VERSION ""

NS_ :

BS_:

BU_: PowertrainControlModule AtmosphericSensor SafetyRestraintSystem2 Aftertreatment_2_GasOutlet Aftertreatment_2_GasIntake DieselParticulateFilterControl Turbocharger SafetyRestraintSystem1 CabDisplay2 Aftertreatment_1_GasOutlet Aftertreatment_1_GasIntake OnBoardDataLogger OffBoardDiagnosticTool2 OffBoardDiagnosticTool1 FileServer ParkingBrakeController SeatController2 FanDriveController SteeringColumnUnit CommunicationUnitRadio CommunicationUnitSatellite CommunicationUnitCellular PropulsionBatteryCharger ChassisController2 ChassisController1 EngineValveControl AuxiliaryHeater2 AuxiliaryHeater1 ClutchUnit RampControl InformationSystem1 SuspensionSystemController2 OilSensor VehicleDynamicStability ExhaustEmissionController TransmissionDisplay2 TransmissionDisplay1 ClimateControl2 WaterPumpController RearAxleSteeringController LightingOperatorControl SeatController1 IgnitionController2 IgnitionController1 TirePressureController CabController2 CabController1 PneumaticSystemController SuspensionSystemController1 HydraulicPumpController EnduranceBrakingSystem RetarderExhaustEngine2 OnBoardDiagnosticUnit HeadwayController RetarderExhaustEngine1 CabDisplay1 ManagementComputer VirtualTerminal OffVehicleGateway PowerTakeOffFront HitchControl AuxiliaryValveControl BodyController TractorTrailerBridge1 StarterSystem ElectricalSystem VehicleSecurity VehicleNavigation AerodynamicControl ElectricalChargingSystem ClimateControl1 TripRecorder InstrumentCluster SuspensionDriveAxle2 SuspensionDriveAxle1 SuspensionSteerAxle SteeringController FuelSystem CruiseControl RetarderDriveline RetarderEngine BrakesDriveAxle2 BrakesDriveAxle1 BrakesSystemController BrakesSteerAxle AxleDrive2 AxleDrive1 AxleSteering PowerTakeOff ShiftConsoleSecondary ShiftConsolePrimary Transmission2 Transmission1 Engine2 Engine1

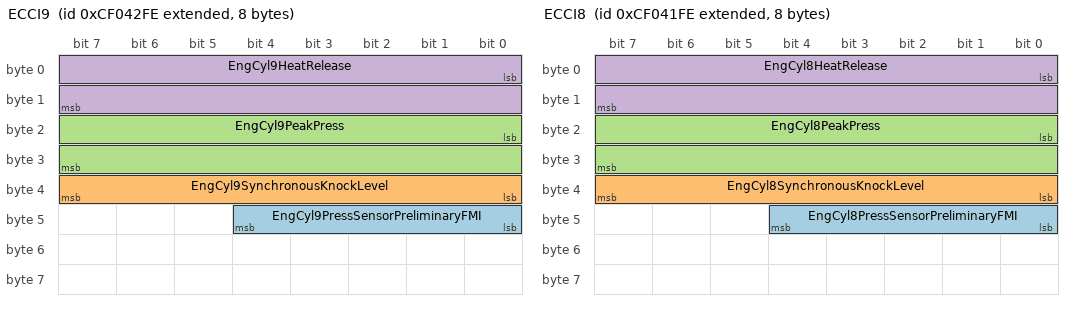
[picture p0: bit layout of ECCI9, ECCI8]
BO_ 2364556030 ECCI9: 8 Vector__XXX
 SG_ EngCyl9PressSensorPreliminaryFMI : 40|5@1+ (1,0) [0|31] "" Vector__XXX
 SG_ EngCyl9SynchronousKnockLevel : 32|8@1+ (1,0) [0|250] "%" Vector__XXX
 SG_ EngCyl9PeakPress : 16|16@1+ (0.0009765625,0) [0|62.74902344] "MPa" Vector__XXX
 SG_ EngCyl9HeatRelease : 0|16@1+ (0.0001220703125,-1) [-1|6.84362793] "kJ/l" Vector__XXX

BO_ 2364555774 ECCI8: 8 Vector__XXX
 SG_ EngCyl8PressSensorPreliminaryFMI : 40|5@1+ (1,0) [0|31] "" Vector__XXX
 SG_ EngCyl8SynchronousKnockLevel : 32|8@1+ (1,0) [0|250] "%" Vector__XXX
 SG_ EngCyl8PeakPress : 16|16@1+ (0.0009765625,0) [0|62.74902344] "MPa" Vector__XXX
 SG_ EngCyl8HeatRelease : 0|16@1+ (0.0001220703125,-1) [-1|6.84362793] "kJ/l" Vector__XXX

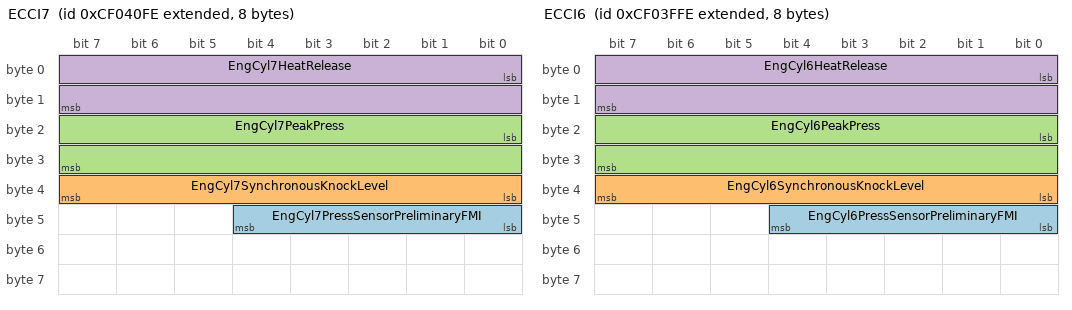
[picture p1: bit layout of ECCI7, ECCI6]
BO_ 2364555518 ECCI7: 8 Vector__XXX
 SG_ EngCyl7PressSensorPreliminaryFMI : 40|5@1+ (1,0) [0|31] "" Vector__XXX
 SG_ EngCyl7SynchronousKnockLevel : 32|8@1+ (1,0) [0|250] "%" Vector__XXX
 SG_ EngCyl7PeakPress : 16|16@1+ (0.0009765625,0) [0|62.74902344] "MPa" Vector__XXX
 SG_ EngCyl7HeatRelease : 0|16@1+ (0.0001220703125,-1) [-1|6.84362793] "kJ/l" Vector__XXX

BO_ 2364555262 ECCI6: 8 Vector__XXX
 SG_ EngCyl6PressSensorPreliminaryFMI : 40|5@1+ (1,0) [0|31] "" Vector__XXX
 SG_ EngCyl6SynchronousKnockLevel : 32|8@1+ (1,0) [0|250] "%" Vector__XXX
 SG_ EngCyl6PeakPress : 16|16@1+ (0.0009765625,0) [0|62.74902344] "MPa" Vector__XXX
 SG_ EngCyl6HeatRelease : 0|16@1+ (0.0001220703125,-1) [-1|6.84362793] "kJ/l" Vector__XXX

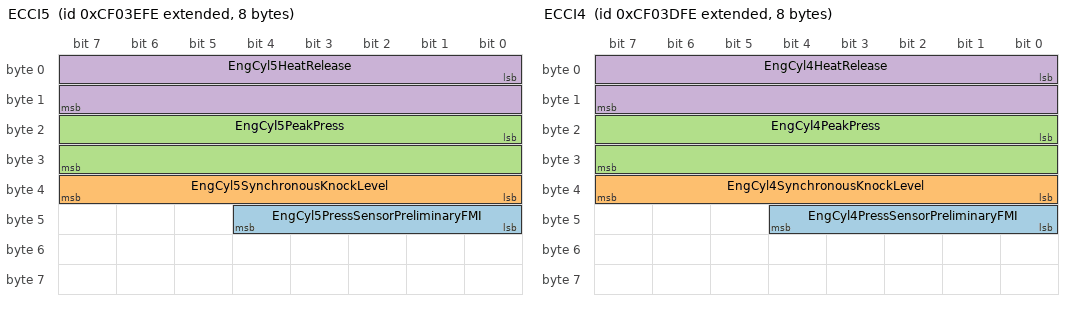
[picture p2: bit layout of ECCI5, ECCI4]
BO_ 2364555006 ECCI5: 8 Vector__XXX
 SG_ EngCyl5PressSensorPreliminaryFMI : 40|5@1+ (1,0) [0|31] "" Vector__XXX
 SG_ EngCyl5SynchronousKnockLevel : 32|8@1+ (1,0) [0|250] "%" Vector__XXX
 SG_ EngCyl5PeakPress : 16|16@1+ (0.0009765625,0) [0|62.74902344] "MPa" Vector__XXX
 SG_ EngCyl5HeatRelease : 0|16@1+ (0.0001220703125,-1) [-1|6.84362793] "kJ/l" Vector__XXX

BO_ 2364554750 ECCI4: 8 Vector__XXX
 SG_ EngCyl4PressSensorPreliminaryFMI : 40|5@1+ (1,0) [0|31] "" Vector__XXX
 SG_ EngCyl4SynchronousKnockLevel : 32|8@1+ (1,0) [0|250] "%" Vector__XXX
 SG_ EngCyl4PeakPress : 16|16@1+ (0.0009765625,0) [0|62.74902344] "MPa" Vector__XXX
 SG_ EngCyl4HeatRelease : 0|16@1+ (0.0001220703125,-1) [-1|6.84362793] "kJ/l" Vector__XXX

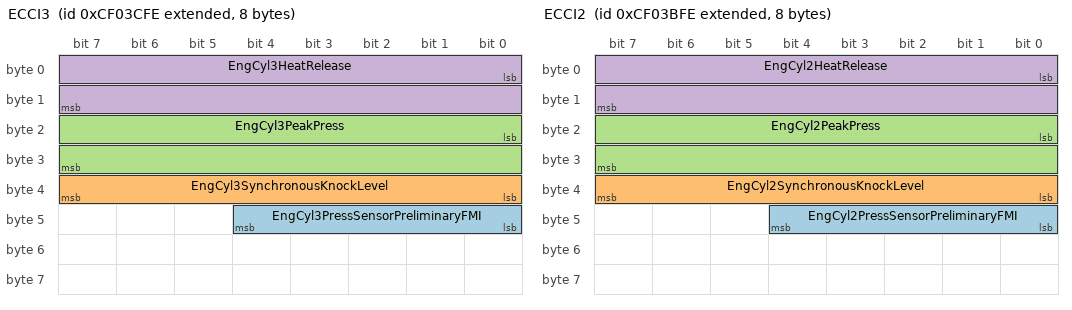
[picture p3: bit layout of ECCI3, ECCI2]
BO_ 2364554494 ECCI3: 8 Vector__XXX
 SG_ EngCyl3PressSensorPreliminaryFMI : 40|5@1+ (1,0) [0|31] "" Vector__XXX
 SG_ EngCyl3SynchronousKnockLevel : 32|8@1+ (1,0) [0|250] "%" Vector__XXX
 SG_ EngCyl3PeakPress : 16|16@1+ (0.0009765625,0) [0|62.74902344] "MPa" Vector__XXX
 SG_ EngCyl3HeatRelease : 0|16@1+ (0.0001220703125,-1) [-1|6.84362793] "kJ/l" Vector__XXX

BO_ 2364554238 ECCI2: 8 Vector__XXX
 SG_ EngCyl2PressSensorPreliminaryFMI : 40|5@1+ (1,0) [0|31] "" Vector__XXX
 SG_ EngCyl2SynchronousKnockLevel : 32|8@1+ (1,0) [0|250] "%" Vector__XXX
 SG_ EngCyl2PeakPress : 16|16@1+ (0.0009765625,0) [0|62.74902344] "MPa" Vector__XXX
 SG_ EngCyl2HeatRelease : 0|16@1+ (0.0001220703125,-1) [-1|6.84362793] "kJ/l" Vector__XXX

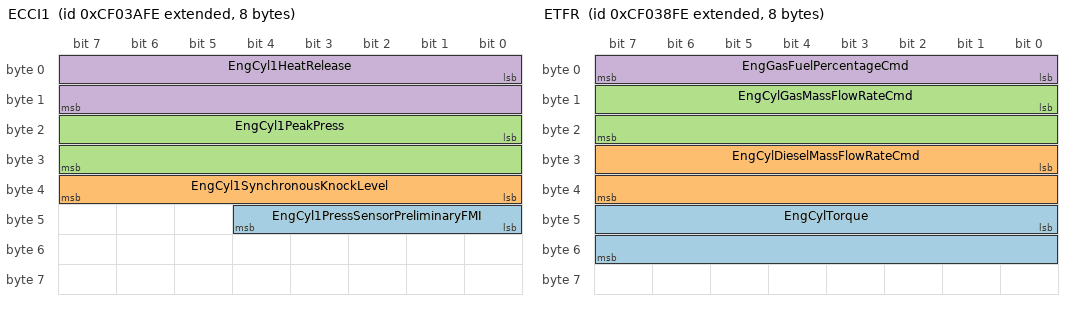
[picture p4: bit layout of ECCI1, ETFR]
BO_ 2364553982 ECCI1: 8 Vector__XXX
 SG_ EngCyl1PressSensorPreliminaryFMI : 40|5@1+ (1,0) [0|31] "" Vector__XXX
 SG_ EngCyl1SynchronousKnockLevel : 32|8@1+ (1,0) [0|100] "%" Vector__XXX
 SG_ EngCyl1PeakPress : 16|16@1+ (0.0009765625,0) [0|62.74902344] "MPa" Vector__XXX
 SG_ EngCyl1HeatRelease : 0|16@1+ (0.0001220703125,-1) [-1|6.84362793] "kJ/l" Vector__XXX

BO_ 2364553726 EASI: 8 Vector__XXX
 SG_ EngTotalIntakeMassAirFlowRate : 16|16@1+ (0.0009765625,0) [0|62.74902344] "kg/s" Vector__XXX
 SG_ EngDesiredAirFuelRatio : 0|16@1+ (0.001,0) [0|64.255] "" Vector__XXX

BO_ 2364553470 ETFR: 8 Vector__XXX
 SG_ EngCylTorque : 40|16@1+ (1,0) [0|64255] "Nm" Vector__XXX
 SG_ EngCylDieselMassFlowRateCmd : 24|16@1+ (6.103515625E-005,0) [0|3.921813965] "kg/s" Vector__XXX
 SG_ EngCylGasMassFlowRateCmd : 8|16@1+ (6.103515625E-005,0) [0|3.921813965] "kg/s" Vector__XXX
 SG_ EngGasFuelPercentageCmd : 0|8@1+ (0.5,0) [0|100] "%" Vector__XXX

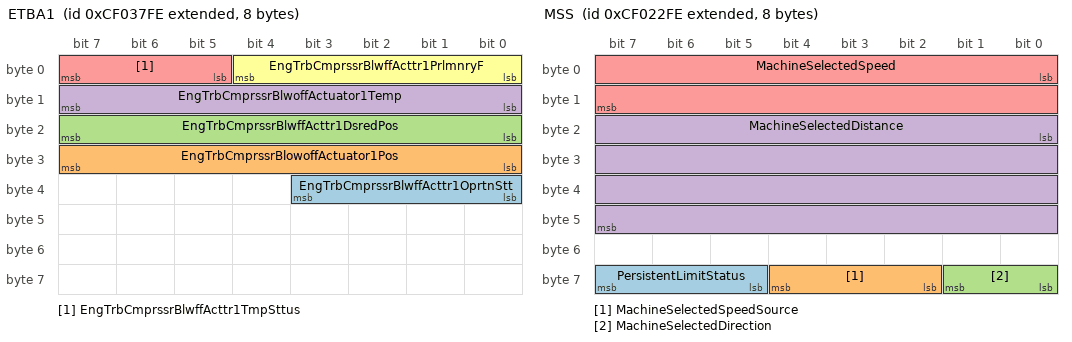
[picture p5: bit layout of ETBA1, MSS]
BO_ 2364553214 ETBA1: 8 Vector__XXX
 SG_ EngTrbCmprssrBlwffActtr1OprtnStt : 32|4@1+ (1,0) [0|15] "" Vector__XXX
 SG_ EngTrbCmprssrBlowoffActuator1Pos : 24|8@1+ (0.4,0) [0|100] "%" Vector__XXX
 SG_ EngTrbCmprssrBlwffActtr1DsredPos : 16|8@1+ (0.4,0) [0|100] "%" Vector__XXX
 SG_ EngTrbCmprssrBlwoffActuator1Temp : 8|8@1+ (1,-40) [-40|210] "°C" Vector__XXX
 SG_ EngTrbCmprssrBlwffActtr1TmpSttus : 5|3@1+ (1,0) [0|7] "" Vector__XXX
 SG_ EngTrbCmprssrBlwffActtr1PrlmnryF : 0|5@1+ (1,0) [0|31] "" Vector__XXX

BO_ 2364547838 MSS: 8 Vector__XXX
 SG_ PersistentLimitStatus : 61|3@1+ (1,0) [0|0] "" Vector__XXX
 SG_ MachineSelectedSpeedSource : 58|3@1+ (1,0) [0|0] "" Vector__XXX
 SG_ MachineSelectedDirection : 56|2@1+ (1,0) [0|0] "" Vector__XXX
 SG_ MachineSelectedDistance : 16|32@1+ (1,0) [0|0] "" Vector__XXX
 SG_ MachineSelectedSpeed : 0|16@1+ (1,0) [0|0] "" Vector__XXX

BO_ 2364547326 EBS25: 8 Vector__XXX

BO_ 2364547070 EBS26: 8 Vector__XXX

BO_ 2364546814 GC2: 8 Vector__XXX
 SG_ GeneratorGoverningBias : 0|16@1+ (0.004,-125) [-125|125] "%" Vector__XXX

BO_ 2364546046 GPM17: 8 Vector__XXX

BO_ 2364538369 PropA: 256 Vector__XXX
 SG_ ManufacturerSpecificInformation : 128|64@1+ (1,0) [0|0] "" Vector__XXX
 SG_ ManufacSpecInfo004_u32 : 96|32@1+ (1,0) [0|0] "" Vector__XXX
 SG_ ManufacSpecInfo002_u32 : 64|32@1+ (1,0) [0|0] "" Vector__XXX
 SG_ ManufacSpecInfo002_u32 : 32|32@1+ (1,0) [0|0] "" Vector__XXX
 SG_ ManufacSpecInfo001_u32 : 0|32@1+ (1,0) [0|0] "" Vector__XXX
 SG_ ManufacturerSpecificInformation1 : 192|64@1+ (1,0) [0|0] "" Vector__XXX

BO_ 2364014334 VT21: 8 Vector__XXX

BO_ 2363948798 VT12: 8 Vector__XXX

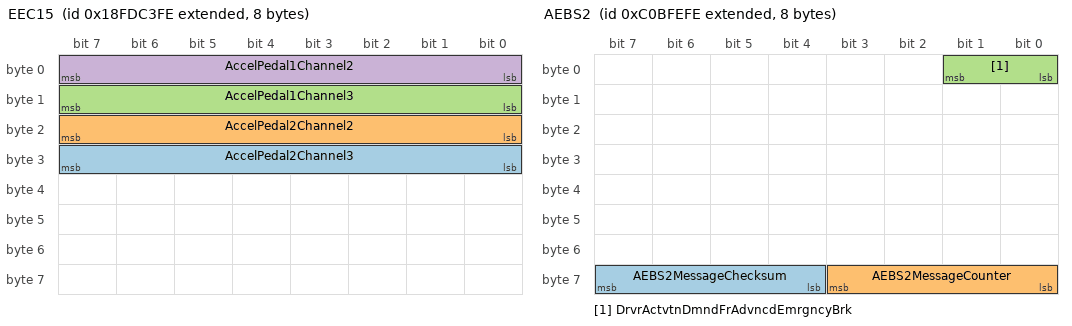
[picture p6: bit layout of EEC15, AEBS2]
BO_ 2566767614 EEC15: 8 Vector__XXX
 SG_ AccelPedal2Channel3 : 24|8@1+ (0.4,0) [0|100] "%" Vector__XXX
 SG_ AccelPedal2Channel2 : 16|8@1+ (0.4,0) [0|100] "%" Vector__XXX
 SG_ AccelPedal1Channel3 : 8|8@1+ (0.4,0) [0|100] "%" Vector__XXX
 SG_ AccelPedal1Channel2 : 0|8@1+ (0.4,0) [0|100] "%" Vector__XXX

BO_ 2559049470 ESR: 8 Vector__XXX
 SG_ DesiredEngFuelingState : 0|2@1+ (1,0) [0|3] "" Vector__XXX
 SG_ RequestedFuelType : 8|8@1+ (1,0) [0|255] "" Vector__XXX

BO_ 2349596414 AEBS2: 8 Vector__XXX
 SG_ AEBS2MessageChecksum : 60|4@1+ (1,0) [0|15] "" Vector__XXX
 SG_ AEBS2MessageCounter : 56|4@1+ (1,0) [0|15] "" Vector__XXX
 SG_ DrvrActvtnDmndFrAdvncdEmrgncyBrk : 0|2@1+ (1,0) [0|3] "" Vector__XXX

BO_ 2362375934 KWP3: 8 Vector__XXX

BO_ 2362310398 KWP4: 8 Vector__XXX

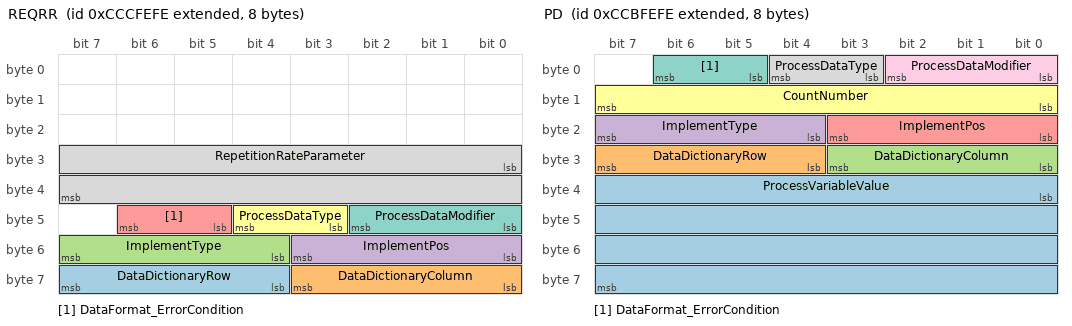
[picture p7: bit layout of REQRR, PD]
BO_ 2362244862 REQRR: 8 Vector__XXX
 SG_ DataDictionaryRow : 60|4@1+ (1,0) [0|0] "" Vector__XXX
 SG_ DataDictionaryColumn : 56|4@1+ (1,0) [0|0] "" Vector__XXX
 SG_ ImplementType : 52|4@1+ (1,0) [0|0] "" Vector__XXX
 SG_ ImplementPos : 48|4@1+ (1,0) [0|0] "" Vector__XXX
 SG_ DataFormat_ErrorCondition : 45|2@1+ (1,0) [0|0] "" Vector__XXX
 SG_ ProcessDataType : 43|2@1+ (1,0) [0|0] "" Vector__XXX
 SG_ ProcessDataModifier : 40|3@1+ (1,0) [0|0] "" Vector__XXX
 SG_ RepetitionRateParameter : 24|16@1+ (1,0) [0|0] "" Vector__XXX

BO_ 2362179326 PD: 8 Vector__XXX
 SG_ ProcessVariableValue : 32|32@1+ (1,0) [0|0] "" Vector__XXX
 SG_ DataDictionaryRow : 28|4@1+ (1,0) [0|0] "" Vector__XXX
 SG_ DataDictionaryColumn : 24|4@1+ (1,0) [0|0] "" Vector__XXX
 SG_ ImplementType : 20|4@1+ (1,0) [0|0] "" Vector__XXX
 SG_ ImplementPos : 16|4@1+ (1,0) [0|0] "" Vector__XXX
 SG_ CountNumber : 8|8@1+ (1,0) [0|0] "" Vector__XXX
 SG_ DataFormat_ErrorCondition : 5|2@1+ (1,0) [0|0] "" Vector__XXX
 SG_ ProcessDataType : 3|2@1+ (1,0) [0|0] "" Vector__XXX
 SG_ ProcessDataModifier : 0|3@1+ (1,0) [0|0] "" Vector__XXX

BO_ 2361982718 ETPCM: 8 Vector__XXX

BO_ 2361917182 ETPDT: 8 Vector__XXX

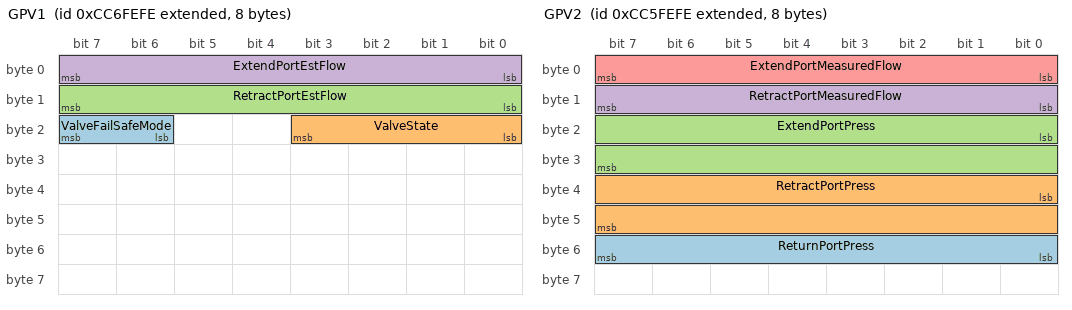
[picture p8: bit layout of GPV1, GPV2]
BO_ 2361851646 GPV1: 8 Vector__XXX
 SG_ ValveFailSafeMode : 22|2@1+ (1,0) [0|0] "" Vector__XXX
 SG_ ValveState : 16|4@1+ (1,0) [0|0] "" Vector__XXX
 SG_ RetractPortEstFlow : 8|8@1+ (1,0) [0|0] "" Vector__XXX
 SG_ ExtendPortEstFlow : 0|8@1+ (1,0) [0|0] "" Vector__XXX

BO_ 2361786110 GPV2: 8 Vector__XXX
 SG_ ReturnPortPress : 48|8@1+ (1,0) [0|0] "" Vector__XXX
 SG_ RetractPortPress : 32|16@1+ (1,0) [0|0] "" Vector__XXX
 SG_ ExtendPortPress : 16|16@1+ (1,0) [0|0] "" Vector__XXX
 SG_ RetractPortMeasuredFlow : 8|8@1+ (1,0) [0|0] "" Vector__XXX
 SG_ ExtendPortMeasuredFlow : 0|8@1+ (1,0) [0|0] "" Vector__XXX

BO_ 2361720574 GPV3: 8 Vector__XXX
 SG_ PortFlowCmd : 0|8@1+ (1,0) [0|0] "" Vector__XXX

BO_ 2361458430 PCM16: 8 Vector__XXX

BO_ 2361392894 PCM15: 8 Vector__XXX

BO_ 2361327358 PCM14: 8 Vector__XXX

BO_ 2361261822 PCM13: 8 Vector__XXX

BO_ 2361196286 PCM12: 8 Vector__XXX

BO_ 2361130750 PCM11: 8 Vector__XXX

BO_ 2361065214 PCM10: 8 Vector__XXX

BO_ 2360999678 PCM9: 8 Vector__XXX

BO_ 2360934142 PCM8: 8 Vector__XXX

BO_ 2360868606 PCM7: 8 Vector__XXX

BO_ 2360803070 PCM6: 8 Vector__XXX

BO_ 2360737534 PCM5: 8 Vector__XXX

BO_ 2360671998 PCM4: 8 Vector__XXX

BO_ 2360606462 PCM3: 8 Vector__XXX

BO_ 2360540926 PCM2: 8 Vector__XXX

BO_ 2360475390 PCM1: 8 Vector__XXX

BO_ 2360409854 CIM: 8 Vector__XXX

BO_ 2360344318 PLM: 8 Vector__XXX

BO_ 2360213246 GSC: 8 Vector__XXX

BO_ 2360147710 GMS: 8 Vector__XXX

BO_ 2360082174 FSC: 8 Vector__XXX

BO_ 2358968062 GPM18: 8 Vector__XXX

BO_ 2358509310 NM: 8 Vector__XXX
 SG_ VehicleSystemQualifierFlag m0 : 12|1@1+ (1,0) [0|1] "" Vector__XXX
 SG_ VehicleSystemInstanceQualifierFl m0 : 13|1@1+ (1,0) [0|1] "" Vector__XXX
 SG_ NameChecksum m0 : 0|8@1+ (1,0) [0|0] "" Vector__XXX
 SG_ NMControlModeIndicator M : 16|4@1+ (1,0) [0|15] "" Vector__XXX
 SG_ ManufacturerCodeQualifierFlag m0M : 8|1@1+ (1,0) [0|1] "" Vector__XXX
 SG_ IndustryGroupQualifierFlag m0 : 14|1@1+ (1,0) [0|1] "" Vector__XXX
 SG_ FunctionQualifierFlag m0 : 11|1@1+ (1,0) [0|1] "" Vector__XXX
 SG_ FunctionInstanceQualifierFlag m0 : 10|1@1+ (1,0) [0|1] "" Vector__XXX
 SG_ ErrorCode m4 : 0|8@1+ (1,0) [0|0] "" Vector__XXX
 SG_ ECUInstanceQualifierFlag m0 : 9|1@1+ (1,0) [0|1] "" Vector__XXX
 SG_ CommandVehicleSystemInstance m0 : 56|4@1+ (1,0) [0|15] "" Vector__XXX
 SG_ CommandVehicleSystem m0 : 49|7@1+ (1,0) [0|127] "" Vector__XXX
 SG_ CommandManufacturerCode m0 : 21|11@1+ (1,0) [0|2047] "" Vector__XXX
 SG_ CommandIndustryGroup m0 : 60|3@1+ (1,0) [0|7] "" Vector__XXX
 SG_ CommandFunctionInstance m0 : 35|5@1+ (1,0) [0|31] "" Vector__XXX
 SG_ CommandFunction m0 : 40|8@1+ (1,0) [0|255] "" Vector__XXX
 SG_ CommandECUInstance m0 : 32|3@1+ (1,0) [0|7] "" Vector__XXX
 SG_ CommandArbitraryAddressCapable m0 : 63|1@1+ (1,0) [0|1] "" Vector__XXX
 SG_ ArbitraryAddressCapableQualifier m0 : 15|1@1+ (1,0) [0|1] "" Vector__XXX

BO_ 2358181630 SCMCC: 8 Vector__XXX

BO_ 2358116094 SCCCM: 8 Vector__XXX

BO_ 2358050558 CCP_CRO: 8 Vector__XXX

BO_ 2357985022 CCP_DTO: 8 Vector__XXX

BO_ 2558983934 SPOC: 8 Vector__XXX
 SG_ SwitchedPowerOutput18Cmd : 36|2@1+ (1,0) [0|3] "" Vector__XXX
 SG_ SwitchedPowerOutput19Cmd : 34|2@1+ (1,0) [0|3] "" Vector__XXX
 SG_ SwitchedPowerOutput20Cmd : 32|2@1+ (1,0) [0|3] "" Vector__XXX
 SG_ SwitchedPowerOutput13Cmd : 30|2@1+ (1,0) [0|3] "" Vector__XXX
 SG_ SwitchedPowerOutput14Cmd : 27|2@1+ (1,0) [0|3] "" Vector__XXX
 SG_ SwitchedPowerOutput15Cmd : 26|2@1+ (1,0) [0|3] "" Vector__XXX
 SG_ SwitchedPowerOutput16Cmd : 24|2@1+ (1,0) [0|3] "" Vector__XXX
 SG_ SwitchedPowerOutput9Cmd : 22|2@1+ (1,0) [0|3] "" Vector__XXX
 SG_ SwitchedPowerOutput10Cmd : 20|2@1+ (1,0) [0|3] "" Vector__XXX
 SG_ SwitchedPowerOutput29Cmd : 62|2@1+ (1,0) [0|3] "" Vector__XXX
 SG_ SwitchedPowerOutput30Cmd : 60|2@1+ (1,0) [0|3] "" Vector__XXX
 SG_ SwitchedPowerOutput31Cmd : 58|2@1+ (1,0) [0|3] "" Vector__XXX
 SG_ SwitchedPowerOutput32Cmd : 56|2@1+ (1,0) [0|3] "" Vector__XXX
 SG_ SwitchedPowerOutput25Cmd : 54|2@1+ (1,0) [0|3] "" Vector__XXX
 SG_ SwitchedPowerOutput26Cmd : 52|2@1+ (1,0) [0|3] "" Vector__XXX
 SG_ SwitchedPowerOutput27Cmd : 50|2@1+ (1,0) [0|3] "" Vector__XXX
 SG_ SwitchedPowerOutput28Cmd : 48|2@1+ (1,0) [0|3] "" Vector__XXX
 SG_ SwitchedPowerOutput21Cmd : 46|2@1+ (1,0) [0|3] "" Vector__XXX
 SG_ SwitchedPowerOutput22Cmd : 44|2@1+ (1,0) [0|3] "" Vector__XXX
 SG_ SwitchedPowerOutput23Cmd : 42|2@1+ (1,0) [0|3] "" Vector__XXX
 SG_ SwitchedPowerOutput24Cmd : 40|2@1+ (1,0) [0|3] "" Vector__XXX
 SG_ SwitchedPowerOutput17Cmd : 38|2@1+ (1,0) [0|3] "" Vector__XXX
 SG_ SwitchedPowerOutput11Cmd : 18|2@1+ (1,0) [0|3] "" Vector__XXX
 SG_ SwitchedPowerOutput12Cmd : 16|2@1+ (1,0) [0|3] "" Vector__XXX
 SG_ SwitchedPowerOutput5Cmd : 14|2@1+ (1,0) [0|3] "" Vector__XXX
 SG_ SwitchedPowerOutput6Cmd : 12|2@1+ (1,0) [0|3] "" Vector__XXX
 SG_ SwitchedPowerOutput7Cmd : 10|2@1+ (1,0) [0|3] "" Vector__XXX
 SG_ SwitchedPowerOutput8Cmd : 8|2@1+ (1,0) [0|3] "" Vector__XXX
 SG_ SwitchedPowerOutput1Cmd : 6|2@1+ (1,0) [0|3] "" Vector__XXX
 SG_ SwitchedPowerOutput2Cmd : 4|2@1+ (1,0) [0|3] "" Vector__XXX
 SG_ SwitchedPowerOutput3Cmd : 2|2@1+ (1,0) [0|3] "" Vector__XXX
 SG_ SwitchedPowerOutput4Cmd : 0|2@1+ (1,0) [0|3] "" Vector__XXX

BO_ 2349727486 TC2: 8 Vector__XXX
 SG_ TransMode10 : 2|2@1+ (1,0) [0|3] "" Vector__XXX
 SG_ TransMode9 : 0|2@1+ (1,0) [0|3] "" Vector__XXX

BO_ 2550988542 EEC16: 8 Vector__XXX
 SG_ AccelPedalPos3 : 0|8@1+ (0.4,0) [0|100] "%" Vector__XXX

BO_ 2349268734 CAM21: 8 Vector__XXX

BO_ 2349203198 CAM11: 8 Vector__XXX

BO_ 2566767358 EEC14: 8 Vector__XXX
 SG_ FuelType : 48|8@1+ (1,0) [0|255] "" Vector__XXX
 SG_ EngFuelMassFlowRate : 32|16@1+ (0.005,0) [0|321.275] "g/s" Vector__XXX
 SG_ EngExhstGsRcrcltn1Valve2PosError : 16|16@1+ (0.004,-125) [-125|132.02] "%" Vector__XXX
 SG_ EngExhstGsRcrcltn1Valve1PosError : 0|16@1+ (0.004,-125) [-125|132.02] "%" Vector__XXX

BO_ 2566706686 AT1P1I: 8 Vector__XXX
 SG_ Aftrtrtmnt1DslExhstFldPumpHeater : 0|8@1+ (0.4,0) [0|100] "%" Vector__XXX

BO_ 2566705406 EPSI: 8 Vector__XXX
 SG_ Aftertreatment2ParticulateSensor : 16|16@1+ (0.0125,0) [0|803.1875] "mg/m^3" Vector__XXX
 SG_ Aftertreatment1ParticulateSensor : 0|16@1+ (0.0125,0) [0|803.1875] "mg/m^3" Vector__XXX

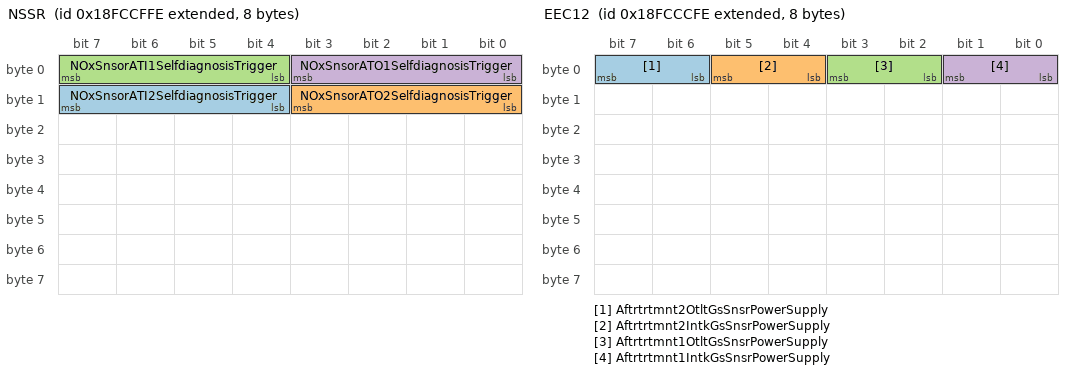
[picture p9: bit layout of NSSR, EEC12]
BO_ 2566705150 NSSR: 8 Vector__XXX
 SG_ NOxSnsorATI2SelfdiagnosisTrigger : 12|4@1+ (1,0) [0|15] "" Vector__XXX
 SG_ NOxSnsorATO2SelfdiagnosisTrigger : 8|4@1+ (1,0) [0|15] "" Vector__XXX
 SG_ NOxSnsorATI1SelfdiagnosisTrigger : 4|4@1+ (1,0) [0|15] "" Vector__XXX
 SG_ NOxSnsorATO1SelfdiagnosisTrigger : 0|4@1+ (1,0) [0|15] "" Vector__XXX

BO_ 2566704382 EEC12: 8 Vector__XXX
 SG_ Aftrtrtmnt2OtltGsSnsrPowerSupply : 6|2@1+ (1,0) [0|3] "" Vector__XXX
 SG_ Aftrtrtmnt2IntkGsSnsrPowerSupply : 4|2@1+ (1,0) [0|3] "" Vector__XXX
 SG_ Aftrtrtmnt1OtltGsSnsrPowerSupply : 2|2@1+ (1,0) [0|3] "" Vector__XXX
 SG_ Aftrtrtmnt1IntkGsSnsrPowerSupply : 0|2@1+ (1,0) [0|3] "" Vector__XXX

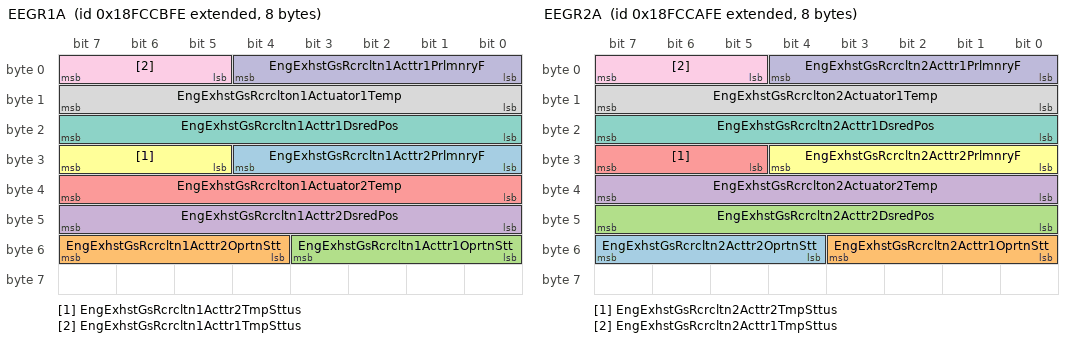
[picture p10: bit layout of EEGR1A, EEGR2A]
BO_ 2566704126 EEGR1A: 8 Vector__XXX
 SG_ EngExhstGsRcrcltn1Acttr2PrlmnryF : 24|5@1+ (1,0) [0|31] "" Vector__XXX
 SG_ EngExhstGsRcrcltn1Acttr2OprtnStt : 52|4@1+ (1,0) [0|15] "" Vector__XXX
 SG_ EngExhstGsRcrcltn1Acttr1OprtnStt : 48|4@1+ (1,0) [0|15] "" Vector__XXX
 SG_ EngExhstGsRcrcltn1Acttr2DsredPos : 40|8@1+ (0.4,0) [0|100] "%" Vector__XXX
 SG_ EngExhstGsRcrclton1Actuator2Temp : 32|8@1+ (1,-40) [-40|210] "°C" Vector__XXX
 SG_ EngExhstGsRcrcltn1Acttr2TmpSttus : 29|3@1+ (1,0) [0|7] "" Vector__XXX
 SG_ EngExhstGsRcrcltn1Acttr1DsredPos : 16|8@1+ (0.4,0) [0|100] "%" Vector__XXX
 SG_ EngExhstGsRcrclton1Actuator1Temp : 8|8@1+ (1,-40) [-40|210] "°C" Vector__XXX
 SG_ EngExhstGsRcrcltn1Acttr1TmpSttus : 5|3@1+ (1,0) [0|7] "" Vector__XXX
 SG_ EngExhstGsRcrcltn1Acttr1PrlmnryF : 0|5@1+ (1,0) [0|31] "" Vector__XXX

BO_ 2566703870 EEGR2A: 8 Vector__XXX
 SG_ EngExhstGsRcrcltn2Acttr2OprtnStt : 52|4@1+ (1,0) [0|15] "" Vector__XXX
 SG_ EngExhstGsRcrcltn2Acttr1OprtnStt : 48|4@1+ (1,0) [0|15] "" Vector__XXX
 SG_ EngExhstGsRcrcltn2Acttr2DsredPos : 40|8@1+ (0.4,0) [0|100] "%" Vector__XXX
 SG_ EngExhstGsRcrclton2Actuator2Temp : 32|8@1+ (1,-40) [-40|210] "°C" Vector__XXX
 SG_ EngExhstGsRcrcltn2Acttr2TmpSttus : 29|3@1+ (1,0) [0|7] "" Vector__XXX
 SG_ EngExhstGsRcrcltn2Acttr2PrlmnryF : 24|5@1+ (1,0) [0|31] "" Vector__XXX
 SG_ EngExhstGsRcrcltn2Acttr1DsredPos : 16|8@1+ (0.4,0) [0|100] "%" Vector__XXX
 SG_ EngExhstGsRcrclton2Actuator1Temp : 8|8@1+ (1,-40) [-40|210] "°C" Vector__XXX
 SG_ EngExhstGsRcrcltn2Acttr1TmpSttus : 5|3@1+ (1,0) [0|7] "" Vector__XXX
 SG_ EngExhstGsRcrcltn2Acttr1PrlmnryF : 0|5@1+ (1,0) [0|31] "" Vector__XXX

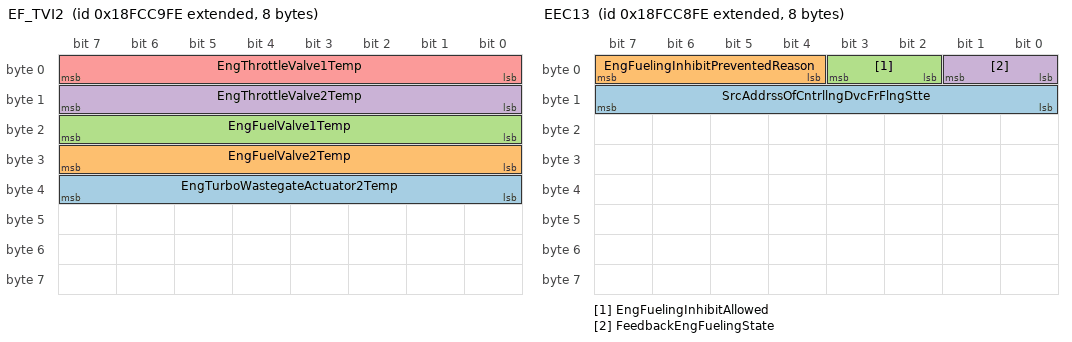
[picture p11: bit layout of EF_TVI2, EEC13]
BO_ 2566703614 EF_TVI2: 8 Vector__XXX
 SG_ EngTurboWastegateActuator2Temp : 32|8@1+ (1,-40) [-40|210] "°C" Vector__XXX
 SG_ EngFuelValve2Temp : 24|8@1+ (1,-40) [-40|210] "°C" Vector__XXX
 SG_ EngFuelValve1Temp : 16|8@1+ (1,-40) [-40|210] "°C" Vector__XXX
 SG_ EngThrottleValve2Temp : 8|8@1+ (1,-40) [-40|210] "°C" Vector__XXX
 SG_ EngThrottleValve1Temp : 0|8@1+ (1,-40) [-40|210] "°C" Vector__XXX

BO_ 2566703358 EEC13: 8 Vector__XXX
 SG_ SrcAddrssOfCntrllngDvcFrFlngStte : 8|8@1+ (1,0) [0|255] "" Vector__XXX
 SG_ EngFuelingInhibitPreventedReason : 4|4@1+ (1,0) [0|15] "" Vector__XXX
 SG_ EngFuelingInhibitAllowed : 2|2@1+ (1,0) [0|3] "" Vector__XXX
 SG_ FeedbackEngFuelingState : 0|2@1+ (1,0) [0|3] "" Vector__XXX

BO_ 2566702590 A1SCREGT2: 8 Vector__XXX
 SG_ Aftrtrtmnt1SCRIntrmdtGsTmpPrlmnr : 16|5@1+ (1,0) [0|31] "" Vector__XXX
 SG_ Aftrtrtmnt1SCRIntrmediateGasTemp : 0|16@1+ (0.03125,-273) [-273|1734.96875] "°C" Vector__XXX

BO_ 2566702334 A2SCREGT2: 8 Vector__XXX
 SG_ Aftrtrtmnt2SCRIntrmdtGsTmpPrlmnr : 16|5@1+ (1,0) [0|31] "" Vector__XXX
 SG_ Aftrtrtmnt2SCRIntrmediateGasTemp : 0|16@1+ (0.03125,-273) [-273|1734.96875] "°C" Vector__XXX

BO_ 2566702078 GFI4: 8 Vector__XXX
 SG_ SupplyGasMethanePercentage : 0|16@1+ (0.0025,0) [0|160.6375] "%" Vector__XXX

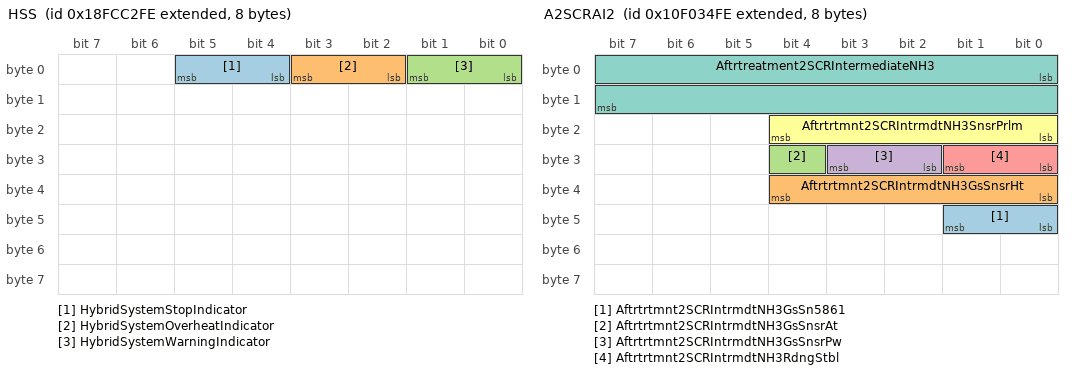
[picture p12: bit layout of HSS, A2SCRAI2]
BO_ 2566701822 HSS: 8 Vector__XXX
 SG_ HybridSystemStopIndicator : 4|2@1+ (1,0) [0|3] "" Vector__XXX
 SG_ HybridSystemOverheatIndicator : 2|2@1+ (1,0) [0|3] "" Vector__XXX
 SG_ HybridSystemWarningIndicator : 0|2@1+ (1,0) [0|3] "" Vector__XXX

BO_ 2431661310 A2SCRAI2: 8 Vector__XXX
 SG_ Aftrtrtmnt2SCRIntrmdtNH3GsSn5861 : 40|2@1+ (1,0) [0|3] "" Vector__XXX
 SG_ Aftrtrtmnt2SCRIntrmdtNH3GsSnsrHt : 32|5@1+ (1,0) [0|31] "" Vector__XXX
 SG_ Aftrtrtmnt2SCRIntrmdtNH3GsSnsrAt : 28|1@1+ (1,0) [0|1] "" Vector__XXX
 SG_ Aftrtrtmnt2SCRIntrmdtNH3GsSnsrPw : 26|2@1+ (1,0) [0|3] "" Vector__XXX
 SG_ Aftrtrtmnt2SCRIntrmdtNH3RdngStbl : 24|2@1+ (1,0) [0|3] "" Vector__XXX
 SG_ Aftrtrtmnt2SCRIntrmdtNH3SnsrPrlm : 16|5@1+ (1,0) [0|31] "" Vector__XXX
 SG_ Aftrtreatment2SCRIntermediateNH3 : 0|16@1+ (0.1,-200) [-200|6225.5] "ppm" Vector__XXX

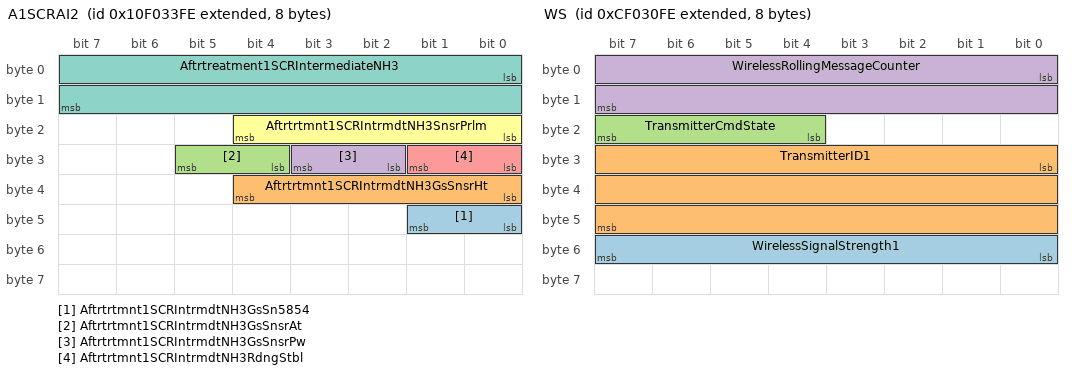
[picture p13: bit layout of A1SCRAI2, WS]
BO_ 2431661054 A1SCRAI2: 8 Vector__XXX
 SG_ Aftrtrtmnt1SCRIntrmdtNH3GsSn5854 : 40|2@1+ (1,0) [0|3] "" Vector__XXX
 SG_ Aftrtrtmnt1SCRIntrmdtNH3GsSnsrHt : 32|5@1+ (1,0) [0|31] "" Vector__XXX
 SG_ Aftrtrtmnt1SCRIntrmdtNH3GsSnsrAt : 28|2@1+ (1,0) [0|3] "" Vector__XXX
 SG_ Aftrtrtmnt1SCRIntrmdtNH3GsSnsrPw : 26|2@1+ (1,0) [0|3] "" Vector__XXX
 SG_ Aftrtrtmnt1SCRIntrmdtNH3RdngStbl : 24|2@1+ (1,0) [0|3] "" Vector__XXX
 SG_ Aftrtrtmnt1SCRIntrmdtNH3SnsrPrlm : 16|5@1+ (1,0) [0|31] "" Vector__XXX
 SG_ Aftrtreatment1SCRIntermediateNH3 : 0|16@1+ (0.1,-200) [-200|6225.5] "ppm" Vector__XXX

BO_ 2230334206 LDISP: 8 Vector__XXX
 SG_ LnrDsplcmntSnsrSnsrFigureOfMerit : 16|2@1+ (1,0) [0|3] "" Vector__XXX
 SG_ MeasuredLinearDisplacement : 0|16@1+ (0.1,0) [0|6425.5] "mm" Vector__XXX

BO_ 2230333950 WAND: 8 Vector__XXX
 SG_ WandSensorFigureOfMerit : 16|2@1+ (1,0) [0|3] "" Vector__XXX
 SG_ WandAngle : 0|16@1+ (0.002,-64) [-64|64.51] "deg" Vector__XXX

BO_ 2364551422 WS: 8 Vector__XXX
 SG_ WirelessSignalStrength1 : 48|8@1+ (0.5,-125) [-125|0] "dBm" Vector__XXX
 SG_ TransmitterID1 : 24|24@1+ (1,0) [0|16449635] "" Vector__XXX
 SG_ TransmitterCmdState : 20|4@1+ (1,0) [0|15] "" Vector__XXX
 SG_ WirelessRollingMessageCounter : 0|16@1+ (1,0) [0|64255] "" Vector__XXX

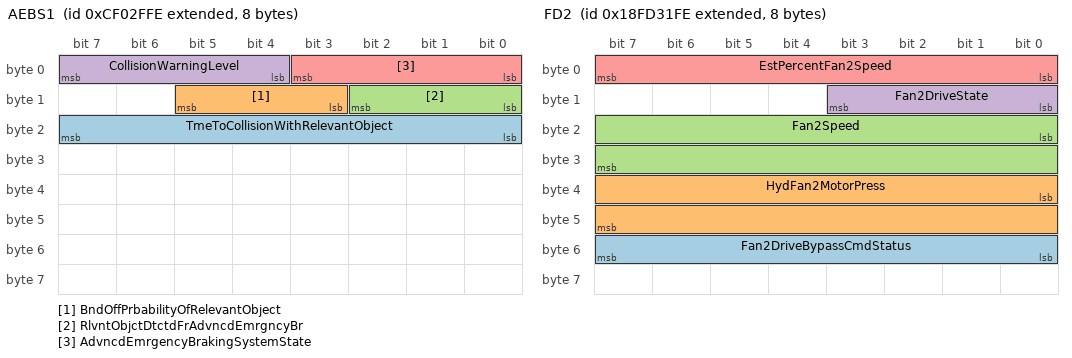
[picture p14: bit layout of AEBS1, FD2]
BO_ 2364551166 AEBS1: 8 Vector__XXX
 SG_ TmeToCollisionWithRelevantObject : 16|8@1+ (0.05,0) [0|12.5] "s" Vector__XXX
 SG_ BndOffPrbabilityOfRelevantObject : 11|3@1+ (1,0) [0|7] "" Vector__XXX
 SG_ RlvntObjctDtctdFrAdvncdEmrgncyBr : 8|3@1+ (1,0) [0|7] "" Vector__XXX
 SG_ CollisionWarningLevel : 4|4@1+ (1,0) [0|15] "" Vector__XXX
 SG_ AdvncdEmrgencyBrakingSystemState : 0|4@1+ (1,0) [0|15] "" Vector__XXX

BO_ 2566730238 FD2: 8 Vector__XXX
 SG_ Fan2DriveBypassCmdStatus : 48|8@1+ (0.4,0) [0|100] "%" Vector__XXX
 SG_ HydFan2MotorPress : 32|16@1+ (0.5,0) [0|32127.5] "kPa" Vector__XXX
 SG_ Fan2Speed : 16|16@1+ (0.125,0) [0|8031.875] "rpm" Vector__XXX
 SG_ Fan2DriveState : 8|4@1+ (1,0) [0|15] "" Vector__XXX
 SG_ EstPercentFan2Speed : 0|8@1+ (0.4,0) [0|100] "%" Vector__XXX

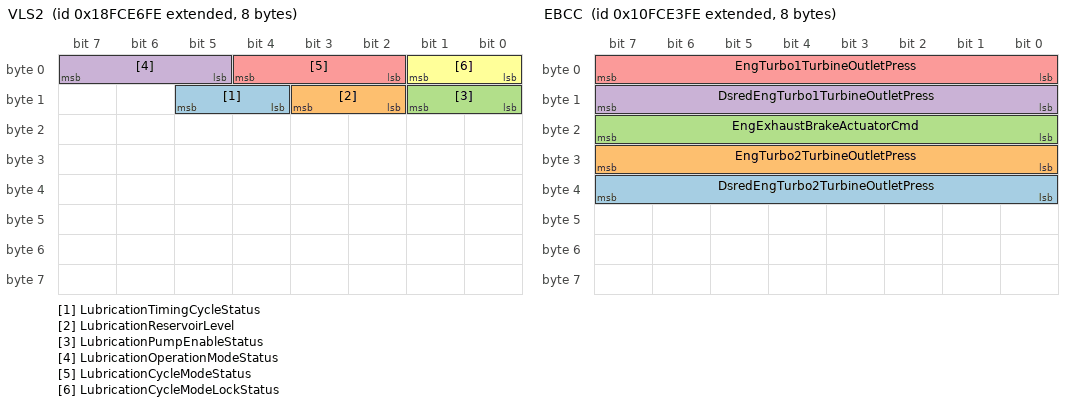
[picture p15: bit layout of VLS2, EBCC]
BO_ 2566711038 VLS2: 8 Vector__XXX
 SG_ LubricationTimingCycleStatus : 12|2@1+ (1,0) [0|3] "" Vector__XXX
 SG_ LubricationReservoirLevel : 10|2@1+ (1,0) [0|3] "" Vector__XXX
 SG_ LubricationPumpEnableStatus : 8|2@1+ (1,0) [0|3] "" Vector__XXX
 SG_ LubricationOperationModeStatus : 5|3@1+ (1,0) [0|7] "" Vector__XXX
 SG_ LubricationCycleModeStatus : 2|3@1+ (1,0) [0|7] "" Vector__XXX
 SG_ LubricationCycleModeLockStatus : 0|2@1+ (1,0) [0|3] "" Vector__XXX

BO_ 2566710782 HOP: 8 Vector__XXX
 SG_ HydOilTemp : 48|16@1+ (0.03125,-273) [-273|1734.96875] "°C" Vector__XXX
 SG_ HydOilRelativeDielectricity : 32|16@1+ (0.0001220703125,0) [0|7.844] "" Vector__XXX
 SG_ HydOilDensity : 16|16@1+ (3.052E-005,0) [0|1.961] "g/cc" Vector__XXX
 SG_ HydOilDynamicViscosity : 0|16@1+ (0.015625,0) [0|1003.984375] "Cp" Vector__XXX

BO_ 2566710526 EFP: 8 Vector__XXX
 SG_ EngFuelTemp : 48|16@1+ (0.03125,-273) [-273|1734.96875] "°C" Vector__XXX
 SG_ EngFuelDielectricity : 32|16@1+ (0.0001220703125,0) [0|7.844] "" Vector__XXX
 SG_ EngFuelDensity : 16|16@1+ (3.052E-005,0) [0|1.961] "g/cc" Vector__XXX
 SG_ EngFuelDynamicViscosity : 0|16@1+ (0.015625,0) [0|1003.984375] "Cp" Vector__XXX

BO_ 2432492542 EBCC: 8 Vector__XXX
 SG_ DsredEngTurbo2TurbineOutletPress : 32|8@1+ (2,0) [0|500] "kPa" Vector__XXX
 SG_ EngTurbo2TurbineOutletPress : 24|8@1+ (2,0) [0|500] "kPa" Vector__XXX
 SG_ EngExhaustBrakeActuatorCmd : 16|8@1+ (0.4,0) [0|100] "%" Vector__XXX
 SG_ DsredEngTurbo1TurbineOutletPress : 8|8@1+ (2,0) [0|500] "kPa" Vector__XXX
 SG_ EngTurbo1TurbineOutletPress : 0|8@1+ (2,0) [0|500] "kPa" Vector__XXX

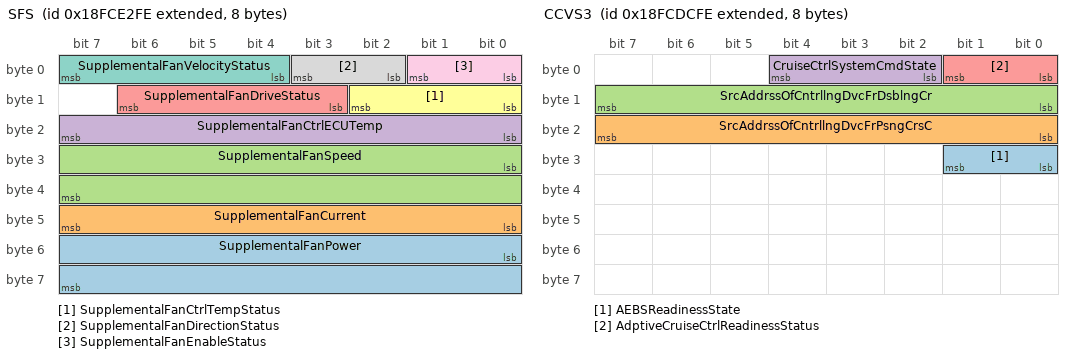
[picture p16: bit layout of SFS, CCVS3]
BO_ 2566710014 SFS: 8 Vector__XXX
 SG_ SupplementalFanPower : 48|16@1+ (0.5,0) [0|32127.5] "W" Vector__XXX
 SG_ SupplementalFanCurrent : 40|8@1+ (1,-125) [-125|125] "A" Vector__XXX
 SG_ SupplementalFanSpeed : 24|16@1+ (0.5,0) [0|32127.5] "rpm" Vector__XXX
 SG_ SupplementalFanCtrlECUTemp : 16|8@1+ (1,-40) [-40|210] "°C" Vector__XXX
 SG_ SupplementalFanDriveStatus : 11|4@1+ (1,0) [0|15] "" Vector__XXX
 SG_ SupplementalFanCtrlTempStatus : 8|3@1+ (1,0) [0|7] "" Vector__XXX
 SG_ SupplementalFanVelocityStatus : 4|4@1+ (1,0) [0|15] "" Vector__XXX
 SG_ SupplementalFanDirectionStatus : 2|2@1+ (1,0) [0|3] "" Vector__XXX
 SG_ SupplementalFanEnableStatus : 0|2@1+ (1,0) [0|3] "" Vector__XXX

BO_ 2566709758 LFE2: 8 Vector__XXX
 SG_ HighResolutionEngFuelRate : 0|32@1+ (0.001,0) [0|4211081.215] "L/h" Vector__XXX

BO_ 2566709502 DPFC2: 8 Vector__XXX
 SG_ Aftertreatment2FuelMassRate : 48|16@1+ (0.05,0) [0|3212.75] "g/min" Vector__XXX
 SG_ Aftertreatment1FuelMassRate : 32|16@1+ (0.05,0) [0|3212.75] "g/min" Vector__XXX
 SG_ RelativeUnburnedFuelMassFromEng : 16|16@1+ (0.0025,0) [0|160.6375] "%" Vector__XXX
 SG_ Aftrtrtmnt1DslPrtcltFltrIntkTmpS : 0|16@1+ (0.03125,-273) [-273|1734.96875] "°C" Vector__XXX

BO_ 2566709246 EFL_P12: 8 Vector__XXX
 SG_ EngFuelFilterDegradation : 24|8@1+ (1,0) [0|250] "%" Vector__XXX
 SG_ EngFilteredFuelDeliveryAbsPress : 16|8@1+ (4,0) [0|1000] "kPa" Vector__XXX
 SG_ EngFilteredFuelDeliveryPress : 8|8@1+ (4,0) [0|1000] "kPa" Vector__XXX
 SG_ EngFuelDeliveryAbsPress : 0|8@1+ (4,0) [0|1000] "kPa" Vector__XXX

BO_ 2566708990 AT1AC3: 8 Vector__XXX
 SG_ Aftertreatment1SecondAirAbsPress : 0|16@1+ (0.1,0) [0|6425.5] "kPa" Vector__XXX

BO_ 2566708734 AT2AC3: 8 Vector__XXX
 SG_ Aftertreatment2SecondAirAbsPress : 0|16@1+ (0.1,0) [0|6425.5] "kPa" Vector__XXX

BO_ 2566708478 CCVS3: 8 Vector__XXX
 SG_ AEBSReadinessState : 24|2@1+ (1,0) [0|3] "" Vector__XXX
 SG_ SrcAddrssOfCntrllngDvcFrPsngCrsC : 16|8@1+ (1,0) [0|255] "" Vector__XXX
 SG_ SrcAddrssOfCntrllngDvcFrDsblngCr : 8|8@1+ (1,0) [0|255] "" Vector__XXX
 SG_ CruiseCtrlSystemCmdState : 2|3@1+ (1,0) [0|7] "" Vector__XXX
 SG_ AdptiveCruiseCtrlReadinessStatus : 0|2@1+ (1,0) [0|3] "" Vector__XXX

BO_ 2566708222 AT1DPF1S3: 8 Vector__XXX
 SG_ Aftrtrtmnt1DslPrtcltFltr1StS5635 : 48|16@1+ (0.1,0) [0|6425.5] "MHz" Vector__XXX
 SG_ Aftrtrtmnt1DslPrtcltFltr1StS5634 : 32|16@1+ (0.1,0) [0|6425.5] "MHz" Vector__XXX
 SG_ Aftrtrtmnt1DslPrtcltFltr1StS5633 : 16|16@1+ (0.1,0) [0|6425.5] "MHz" Vector__XXX
 SG_ Aftrtrtmnt1DslPrtcltFltr1StSnsrA : 0|16@1+ (0.1,0) [0|6425.5] "MHz" Vector__XXX

BO_ 2566707966 AT1DPF1S4: 8 Vector__XXX
 SG_ Aftrtrtmnt1DslPrtcltFltr1StS5639 : 48|16@1+ (0.0025,0) [0|160.6375] "%" Vector__XXX
 SG_ Aftrtrtmnt1DslPrtcltFltr1StS5638 : 32|16@1+ (0.1,0) [0|6425.5] "MHz" Vector__XXX
 SG_ Aftrtrtmnt1DslPrtcltFltr1StSnsrF : 16|16@1+ (0.0025,0) [0|160.6375] "%" Vector__XXX
 SG_ Aftrtrtmnt1DslPrtcltFltr1StSnsrA : 0|16@1+ (0.1,0) [0|6425.5] "MHz" Vector__XXX

BO_ 2566707710 AT1DPF1S5: 8 Vector__XXX
 SG_ Aftrtrtmnt1DslPrtcltFltr1StS5643 : 48|16@1+ (0.0025,0) [0|160.6375] "%" Vector__XXX
 SG_ Aftrtrtmnt1DslPrtcltFltr1StS5642 : 32|16@1+ (0.1,0) [0|6425.5] "MHz" Vector__XXX
 SG_ Aftrtrtmnt1DslPrtcltFltr1StSnsrF : 16|16@1+ (0.0025,0) [0|160.6375] "%" Vector__XXX
 SG_ Aftrtrtmnt1DslPrtcltFltr1StSnsrA : 0|16@1+ (0.1,0) [0|6425.5] "MHz" Vector__XXX

BO_ 2360016638 CFS: 8 Vector__XXX

BO_ 2365423102 FMS1: 8 Vector__XXX

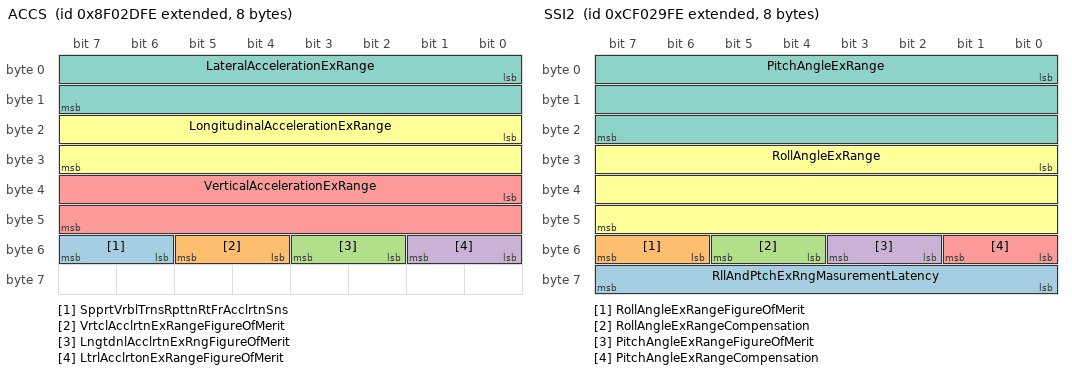
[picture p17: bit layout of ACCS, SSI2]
BO_ 2297441790 ACCS: 8 Vector__XXX
 SG_ SpprtVrblTrnsRpttnRtFrAcclrtnSns : 54|2@1+ (1,0) [0|3] "" Vector__XXX
 SG_ VrtclAcclrtnExRangeFigureOfMerit : 52|2@1+ (1,0) [0|3] "" Vector__XXX
 SG_ LngtdnlAcclrtnExRngFigureOfMerit : 50|2@1+ (1,0) [0|3] "" Vector__XXX
 SG_ LtrlAcclrtonExRangeFigureOfMerit : 48|2@1+ (1,0) [0|3] "" Vector__XXX
 SG_ VerticalAccelerationExRange : 32|16@1+ (0.01,-320) [-320|322.55] "m/s²" Vector__XXX
 SG_ LongitudinalAccelerationExRange : 16|16@1+ (0.01,-320) [-320|322.55] "m/s²" Vector__XXX
 SG_ LateralAccelerationExRange : 0|16@1+ (0.01,-320) [-320|322.55] "m/s²" Vector__XXX

BO_ 2566699006 VEP4: 8 Vector__XXX
 SG_ HybridBatteryPackRemainingCharge : 0|16@1+ (0.0025,0) [0|160.6375] "%" Vector__XXX

BO_ 2364549630 SSI2: 8 Vector__XXX
 SG_ RllAndPtchExRngMasurementLatency : 56|8@1+ (0.5,0) [0|125] "ms" Vector__XXX
 SG_ RollAngleExRangeFigureOfMerit : 54|2@1+ (1,0) [0|3] "" Vector__XXX
 SG_ RollAngleExRangeCompensation : 52|2@1+ (1,0) [0|3] "" Vector__XXX
 SG_ PitchAngleExRangeFigureOfMerit : 50|2@1+ (1,0) [0|3] "" Vector__XXX
 SG_ PitchAngleExRangeCompensation : 48|2@1+ (1,0) [0|3] "" Vector__XXX
 SG_ RollAngleExRange : 24|24@1+ (3.0517578125E-005,-250) [-250|250.9999] "deg" Vector__XXX
 SG_ PitchAngleExRange : 0|24@1+ (3.0517578125E-005,-250) [-250|250.9999] "deg" Vector__XXX

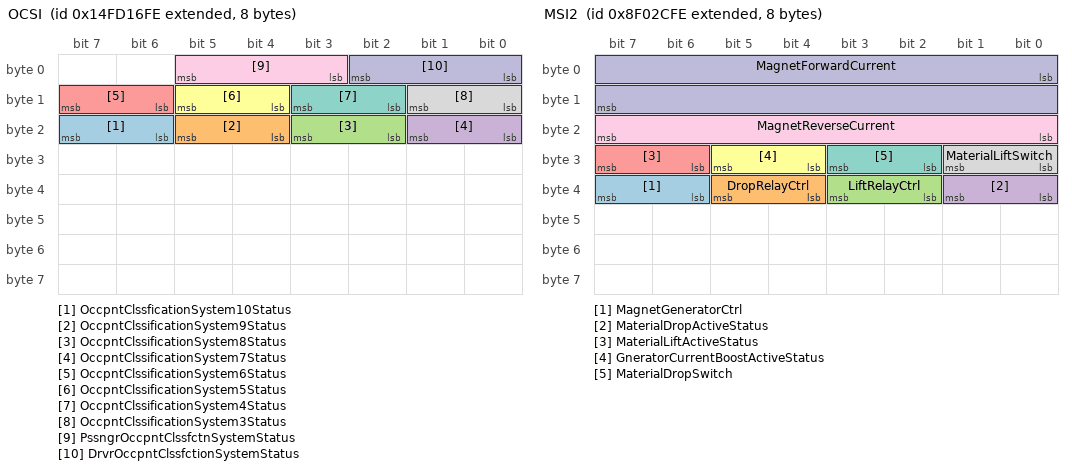
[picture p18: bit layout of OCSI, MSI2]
BO_ 2499614462 OCSI: 8 Vector__XXX
 SG_ OccpntClssficationSystem10Status : 22|2@1+ (1,0) [0|3] "" Vector__XXX
 SG_ OccpntClssificationSystem9Status : 20|2@1+ (1,0) [0|3] "" Vector__XXX
 SG_ OccpntClssificationSystem8Status : 18|2@1+ (1,0) [0|3] "" Vector__XXX
 SG_ OccpntClssificationSystem7Status : 16|2@1+ (1,0) [0|3] "" Vector__XXX
 SG_ OccpntClssificationSystem6Status : 14|2@1+ (1,0) [0|3] "" Vector__XXX
 SG_ OccpntClssificationSystem5Status : 12|2@1+ (1,0) [0|3] "" Vector__XXX
 SG_ OccpntClssificationSystem4Status : 10|2@1+ (1,0) [0|3] "" Vector__XXX
 SG_ OccpntClssificationSystem3Status : 8|2@1+ (1,0) [0|3] "" Vector__XXX
 SG_ PssngrOccpntClssfctnSystemStatus : 3|3@1+ (1,0) [0|7] "" Vector__XXX
 SG_ DrvrOccpntClssfctionSystemStatus : 0|3@1+ (1,0) [0|7] "" Vector__XXX

BO_ 2560098046 NCS: 8 Vector__XXX
 SG_ CabNoiseCtrlTuningStatus : 2|4@1+ (1,0) [0|15] "" Vector__XXX
 SG_ CabNoiseCtrlStatus : 0|2@1+ (1,0) [0|3] "" Vector__XXX

BO_ 2560163582 NC1: 8 Vector__XXX
 SG_ CabNoiseCtrlTuningCmd : 2|3@1+ (1,0) [0|7] "" Vector__XXX
 SG_ CabNoiseCtrlCmd : 0|2@1+ (1,0) [0|3] "" Vector__XXX

BO_ 2297441534 MSI2: 8 Vector__XXX
 SG_ MagnetGeneratorCtrl : 38|2@1+ (1,0) [0|3] "" Vector__XXX
 SG_ DropRelayCtrl : 36|2@1+ (1,0) [0|3] "" Vector__XXX
 SG_ LiftRelayCtrl : 34|2@1+ (1,0) [0|3] "" Vector__XXX
 SG_ MaterialDropActiveStatus : 32|2@1+ (1,0) [0|3] "" Vector__XXX
 SG_ MaterialLiftActiveStatus : 30|2@1+ (1,0) [0|3] "" Vector__XXX
 SG_ GneratorCurrentBoostActiveStatus : 28|2@1+ (1,0) [0|3] "" Vector__XXX
 SG_ MaterialDropSwitch : 26|2@1+ (1,0) [0|3] "" Vector__XXX
 SG_ MaterialLiftSwitch : 24|2@1+ (1,0) [0|3] "" Vector__XXX
 SG_ MagnetReverseCurrent : 16|8@1+ (1,0) [0|250] "A" Vector__XXX
 SG_ MagnetForwardCurrent : 0|16@1+ (1,0) [0|64255] "A" Vector__XXX

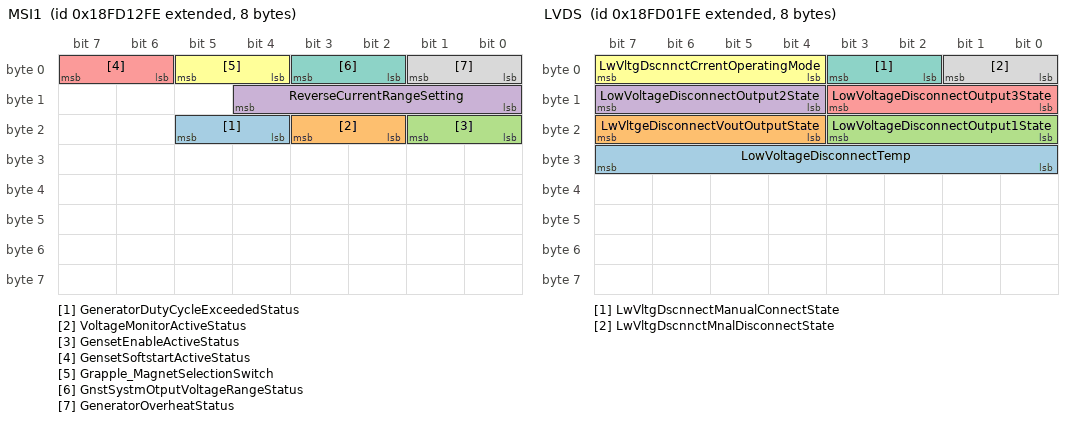
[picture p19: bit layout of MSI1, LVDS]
BO_ 2566722302 MSI1: 8 Vector__XXX
 SG_ GeneratorDutyCycleExceededStatus : 20|2@1+ (1,0) [0|3] "" Vector__XXX
 SG_ VoltageMonitorActiveStatus : 18|2@1+ (1,0) [0|3] "" Vector__XXX
 SG_ GensetEnableActiveStatus : 16|2@1+ (1,0) [0|3] "" Vector__XXX
 SG_ ReverseCurrentRangeSetting : 8|5@1+ (1,0) [0|31] "" Vector__XXX
 SG_ GensetSoftstartActiveStatus : 6|2@1+ (1,0) [0|3] "" Vector__XXX
 SG_ Grapple_MagnetSelectionSwitch : 4|2@1+ (1,0) [0|3] "" Vector__XXX
 SG_ GnstSystmOtputVoltageRangeStatus : 2|2@1+ (1,0) [0|3] "" Vector__XXX
 SG_ GeneratorOverheatStatus : 0|2@1+ (1,0) [0|3] "" Vector__XXX

BO_ 2566722558 MSCI: 8 Vector__XXX
 SG_ MagnetRatedPower : 8|16@1+ (0.5,0) [0|32127.5] "kW" Vector__XXX
 SG_ MagnetBoostTime : 0|8@1+ (0.25,0) [0|62.5] "s" Vector__XXX

BO_ 2560032510 LVDSOM: 8 Vector__XXX
 SG_ LwVltgDscnnctDsiredOperatingMode : 0|4@1+ (1,0) [0|15] "" Vector__XXX

BO_ 2566717950 LVDS: 8 Vector__XXX
 SG_ LowVoltageDisconnectTemp : 24|8@1+ (1,-40) [-40|210] "°C" Vector__XXX
 SG_ LwVltgeDisconnectVoutOutputState : 20|4@1+ (1,0) [0|15] "" Vector__XXX
 SG_ LowVoltageDisconnectOutput1State : 16|4@1+ (1,0) [0|15] "" Vector__XXX
 SG_ LowVoltageDisconnectOutput2State : 12|4@1+ (1,0) [0|15] "" Vector__XXX
 SG_ LowVoltageDisconnectOutput3State : 8|4@1+ (1,0) [0|15] "" Vector__XXX
 SG_ LwVltgDscnnctCrrentOperatingMode : 4|4@1+ (1,0) [0|15] "" Vector__XXX
 SG_ LwVltgDscnnectManualConnectState : 2|2@1+ (1,0) [0|3] "" Vector__XXX
 SG_ LwVltgDscnnctMnalDisconnectState : 0|2@1+ (1,0) [0|3] "" Vector__XXX

BO_ 2499604222 LLRE: 8 Vector__XXX
 SG_ BldReferenceElevationOffsetRight : 48|16@1+ (1,-32000) [-32000|32255] "mm" Vector__XXX
 SG_ BldeReferenceElevationOffsetLeft : 32|16@1+ (1,-32000) [-32000|32255] "mm" Vector__XXX
 SG_ BladeElevationDeviationRight : 16|16@1+ (1,-32000) [-32000|32255] "mm" Vector__XXX
 SG_ BladeElevationDeviationLeft : 0|16@1+ (1,-32000) [-32000|32255] "mm" Vector__XXX

BO_ 2358902526 JLCM: 8 Vector__XXX
 SG_ Joystick3Lamp10Cmd : 58|2@1+ (1,0) [0|3] "" Vector__XXX
 SG_ Joystick3Lamp9Cmd : 56|2@1+ (1,0) [0|3] "" Vector__XXX
 SG_ Joystick3Lamp8Cmd : 54|2@1+ (1,0) [0|3] "" Vector__XXX
 SG_ Joystick3Lamp7Cmd : 52|2@1+ (1,0) [0|3] "" Vector__XXX
 SG_ Joystick3Lamp6Cmd : 50|2@1+ (1,0) [0|3] "" Vector__XXX
 SG_ Joystick3Lamp5Cmd : 48|2@1+ (1,0) [0|3] "" Vector__XXX
 SG_ Joystick3Lamp4Cmd : 46|2@1+ (1,0) [0|3] "" Vector__XXX
 SG_ Joystick3Lamp3Cmd : 44|2@1+ (1,0) [0|3] "" Vector__XXX
 SG_ Joystick3Lamp2Cmd : 42|2@1+ (1,0) [0|3] "" Vector__XXX
 SG_ Joystick3Lamp1Cmd : 40|2@1+ (1,0) [0|3] "" Vector__XXX
 SG_ Joystick2Lamp10Cmd : 38|2@1+ (1,0) [0|3] "" Vector__XXX
 SG_ Joystick2Lamp9Cmd : 36|2@1+ (1,0) [0|3] "" Vector__XXX
 SG_ Joystick2Lamp8Cmd : 34|2@1+ (1,0) [0|3] "" Vector__XXX
 SG_ Joystick2Lamp7Cmd : 32|2@1+ (1,0) [0|3] "" Vector__XXX
 SG_ Joystick2Lamp6Cmd : 30|2@1+ (1,0) [0|3] "" Vector__XXX
 SG_ Joystick2Lamp5Cmd : 28|2@1+ (1,0) [0|3] "" Vector__XXX
 SG_ Joystick2Lamp4Cmd : 26|2@1+ (1,0) [0|3] "" Vector__XXX
 SG_ Joystick2Lamp3Cmd : 24|2@1+ (1,0) [0|3] "" Vector__XXX
 SG_ Joystick2Lamp2Cmd : 22|2@1+ (1,0) [0|3] "" Vector__XXX
 SG_ Joystick2Lamp1Cmd : 20|2@1+ (1,0) [0|3] "" Vector__XXX
 SG_ Joystick1Lamp10Cmd : 18|2@1+ (1,0) [0|3] "" Vector__XXX
 SG_ Joystick1Lamp9Cmd : 16|2@1+ (1,0) [0|3] "" Vector__XXX
 SG_ Joystick1Lamp8Cmd : 14|2@1+ (1,0) [0|3] "" Vector__XXX
 SG_ Joystick1Lamp7Cmd : 12|2@1+ (1,0) [0|3] "" Vector__XXX
 SG_ Joystick1Lamp6Cmd : 10|2@1+ (1,0) [0|3] "" Vector__XXX
 SG_ Joystick1Lamp5Cmd : 8|2@1+ (1,0) [0|3] "" Vector__XXX
 SG_ Joystick1Lamp4Cmd : 6|2@1+ (1,0) [0|3] "" Vector__XXX
 SG_ Joystick1Lamp3Cmd : 4|2@1+ (1,0) [0|3] "" Vector__XXX
 SG_ Joystick1Lamp2Cmd : 2|2@1+ (1,0) [0|3] "" Vector__XXX
 SG_ Joystick1Lamp1Cmd : 0|2@1+ (1,0) [0|3] "" Vector__XXX

CM_ BO_ 2364556030 "Used to communicate combustion information of Engine Cylinder 9. The PGN is transmitted at the end of every combustion in Cylinder 9.";
CM_ SG_ 2364556030 EngCyl9PressSensorPreliminaryFMI "Used to identify the applicable J1939-73 FMI detected in the engine cylinder 9 pressure sensor.  When there is no failure FMI 31 is sent. In the case of multiple failures the most severe is communicated.";
CM_ SG_ 2364556030 EngCyl9SynchronousKnockLevel "Used to indicate the level of knock for engine cylinder 9. The level of knock is reported using a relative scale where 0% is least level of knock, and increasing levels indicate more knock until 100% indicates the most severe level of knock allowed ...";
CM_ SG_ 2364556030 EngCyl9PeakPress "Peak pressure in engine cylinder 9 in combustion cycle.";
CM_ SG_ 2364556030 EngCyl9HeatRelease "The amount of heat produced during combustion in engine cylinder 9.  The negative range is to cover thermodynamic behavior during misfire.";
CM_ BO_ 2364555774 "Used to communicate combustion information of Engine Cylinder 8. The PGN is transmitted at the end of every combustion in Cylinder 8.";
CM_ SG_ 2364555774 EngCyl8PressSensorPreliminaryFMI "Used to identify the applicable J1939-73 FMI detected in the engine cylinder 8 pressure sensor.  When there is no failure FMI 31 is sent. In the case of multiple failures the most severe is communicated.";
CM_ SG_ 2364555774 EngCyl8SynchronousKnockLevel "Used to indicate the level of knock for engine cylinder 8. The level of knock is reported using a relative scale where 0% is least level of knock, and increasing levels indicate more knock until 100% indicates the most severe level of knock allowed ...";
CM_ SG_ 2364555774 EngCyl8PeakPress "Peak pressure in engine cylinder 8 in combustion cycle.";
CM_ SG_ 2364555774 EngCyl8HeatRelease "The amount of heat produced during combustion in engine cylinder 8.  The negative range is to cover thermodynamic behavior during misfire.";
CM_ BO_ 2364555518 "Used to communicate combustion information of Engine Cylinder 7. The PGN is transmitted at the end of every combustion in Cylinder 7.";
CM_ SG_ 2364555518 EngCyl7PressSensorPreliminaryFMI "Used to identify the applicable J1939-73 FMI detected in the engine cylinder 7 pressure sensor.  When there is no failure FMI 31 is sent. In the case of multiple failures the most severe is communicated.";
CM_ SG_ 2364555518 EngCyl7SynchronousKnockLevel "Used to indicate the level of knock for engine cylinder 7. The level of knock is reported using a relative scale where 0% is least level of knock, and increasing levels indicate more knock until 100% indicates the most severe level of knock allowed ...";
CM_ SG_ 2364555518 EngCyl7PeakPress "Peak pressure in engine cylinder 7 in combustion cycle.";
CM_ SG_ 2364555518 EngCyl7HeatRelease "The amount of heat produced during combustion in engine cylinder 7.  The negative range is to cover thermodynamic behavior during misfire.";
CM_ BO_ 2364555262 "Used to communicate combustion information of Engine Cylinder 6. The PGN is transmitted at the end of every combustion in Cylinder 6.";
CM_ SG_ 2364555262 EngCyl6PressSensorPreliminaryFMI "Used to identify the applicable J1939-73 FMI detected in the engine cylinder 6 pressure sensor.  When there is no failure FMI 31 is sent. In the case of multiple failures the most severe is communicated.";
CM_ SG_ 2364555262 EngCyl6SynchronousKnockLevel "Used to indicate the level of knock for engine cylinder 6. The level of knock is reported using a relative scale where 0% is least level of knock, and increasing levels indicate more knock until 100% indicates the most severe level of knock allowed ...";
CM_ SG_ 2364555262 EngCyl6PeakPress "Peak pressure in engine cylinder 6 in combustion cycle.";
CM_ SG_ 2364555262 EngCyl6HeatRelease "The amount of heat produced during combustion in engine cylinder 6.  The negative range is to cover thermodynamic behavior during misfire.";
CM_ BO_ 2364555006 "Used to communicate combustion information of Engine Cylinder 5. The PGN is transmitted at the end of every combustion in Cylinder 5.";
CM_ SG_ 2364555006 EngCyl5PressSensorPreliminaryFMI "Used to identify the applicable J1939-73 FMI detected in the engine cylinder 5 pressure sensor.  When there is no failure FMI 31 is sent. In the case of multiple failures the most severe is communicated.";
CM_ SG_ 2364555006 EngCyl5SynchronousKnockLevel "Used to indicate the level of knock for engine cylinder 6. The level of knock is reported using a relative scale where 0% is least level of knock, and increasing levels indicate more knock until 100% indicates the most severe level of knock allowed ...";
CM_ SG_ 2364555006 EngCyl5PeakPress "Peak pressure in engine cylinder 5 in combustion cycle.";
CM_ SG_ 2364555006 EngCyl5HeatRelease "The amount of heat produced during combustion in engine cylinder 5.  The negative range is to cover thermodynamic behavior during misfire.";
CM_ BO_ 2364554750 "Used to communicate combustion information of Engine Cylinder 4. The PGN is transmitted at the end of every combustion in Cylinder 4.";
CM_ SG_ 2364554750 EngCyl4PressSensorPreliminaryFMI "Used to identify the applicable J1939-73 FMI detected in the engine cylinder 4 pressure sensor.  When there is no failure FMI 31 is sent. In the case of multiple failures the most severe is communicated.";
CM_ SG_ 2364554750 EngCyl4SynchronousKnockLevel "Used to indicate the level of knock for engine cylinder 4. The level of knock is reported using a relative scale where 0% is least level of knock, and increasing levels indicate more knock until 100% indicates the most severe level of knock allowed ...";
CM_ SG_ 2364554750 EngCyl4PeakPress "Peak pressure in engine cylinder 4 in combustion cycle.";
CM_ SG_ 2364554750 EngCyl4HeatRelease "The amount of heat produced during combustion in engine cylinder 4.  The negative range is to cover thermodynamic behavior during misfire.";
CM_ BO_ 2364554494 "Used to communicate combustion information of Engine Cylinder 3. The PGN is transmitted at the end of every combustion in Cylinder 3.";
CM_ SG_ 2364554494 EngCyl3PressSensorPreliminaryFMI "Used to identify the applicable J1939-73 FMI detected in the engine cylinder 3 pressure sensor.  When there is no failure FMI 31 is sent. In the case of multiple failures the most severe is communicated.";
CM_ SG_ 2364554494 EngCyl3SynchronousKnockLevel "Used to indicate the level of knock for engine cylinder 3. The level of knock is reported using a relative scale where 0% is least level of knock, and increasing levels indicate more knock until 100% indicates the most severe level of knock allowed ...";
CM_ SG_ 2364554494 EngCyl3PeakPress "Peak pressure in engine cylinder 3 in combustion cycle.";
CM_ SG_ 2364554494 EngCyl3HeatRelease "The amount of heat produced during combustion in engine cylinder 3.  The negative range is to cover thermodynamic behavior during misfire.";
CM_ BO_ 2364554238 "Used to communicate combustion information of Engine Cylinder 2. The PGN is transmitted at the end of every combustion in Cylinder 2.";
CM_ SG_ 2364554238 EngCyl2PressSensorPreliminaryFMI "Used to identify the applicable J1939-73 FMI detected in the engine cylinder 2 pressure sensor.  When there is no failure FMI 31 is sent. In the case of multiple failures the most severe is communicated.";
CM_ SG_ 2364554238 EngCyl2SynchronousKnockLevel "Used to indicate the level of knock for engine cylinder 2. The level of knock is reported using a relative scale where 0% is least level of knock, and increasing levels indicate more knock until 100% indicates the most severe level of knock allowed ...";
CM_ SG_ 2364554238 EngCyl2PeakPress "Peak pressure in engine cylinder 2 in combustion cycle.";
CM_ SG_ 2364554238 EngCyl2HeatRelease "The amount of heat produced during combustion in engine cylinder 2.  The negative range is to cover thermodynamic behavior during misfire.";
CM_ BO_ 2364553982 "Used to communicate combustion information of Engine Cylinder 1. The PGN is transmitted at the end of every combustion in Cylinder 1.";
CM_ SG_ 2364553982 EngCyl1PressSensorPreliminaryFMI "Used to identify the applicable J1939-73 FMI detected in the engine cylinder 1 pressure sensor.  When there is no failure FMI 31 is sent. In the case of multiple failures the most severe is communicated.";
CM_ SG_ 2364553982 EngCyl1SynchronousKnockLevel "Used to indicate the level of knock for engine cylinder 1. The level of knock is reported using a relative scale where 0% is least level of knock, and increasing levels indicate more knock until 100% indicates the most severe level of knock allowed ...";
CM_ SG_ 2364553982 EngCyl1PeakPress "Peak pressure in engine cylinder 1 in combustion cycle.";
CM_ SG_ 2364553982 EngCyl1HeatRelease "The amount of heat produced during combustion in Engine cylinder 1. The negative range is to cover thermodynamic behavior during misfire.";
CM_ BO_ 2364553726 "Used to transmit parameters related to air systems.";
CM_ SG_ 2364553726 EngTotalIntakeMassAirFlowRate "Mass Flow rate of air entering the engine. This also includes the amount of exhaust gas recirculated, if any.";
CM_ SG_ 2364553726 EngDesiredAirFuelRatio "Reports the desired Air Fuel ratio for the engine.

Air Fuel Ratio specifies the amount of air required to completely burn one unit of fuel in the engine to meet the required engine performance and emission standards.";
CM_ BO_ 2364553470 "Used to transmit requested information for engine torque and fuel rate.";
CM_ SG_ 2364553470 EngCylTorque "Calculated engine torque output per cylinder.";
CM_ SG_ 2364553470 EngCylDieselMassFlowRateCmd "Commanded Mass Flow rate of diesel fuel delivered to the engine normalized per cylinder.";
CM_ SG_ 2364553470 EngCylGasMassFlowRateCmd "Commanded Mass Flow rate of gaseous fuel delivered to the engine normalized per cylinder.";
CM_ SG_ 2364553470 EngGasFuelPercentageCmd "Percentage of Gaseous fuel used, in terms of % mass of fuel. 0% means no Gaseous fuel used and 100 % means completely gaseous fuel is used.";
CM_ BO_ 2364553214 "Used to transmit Engine Turbocharger Blowoff Actuator parameters";
CM_ SG_ 2364553214 EngTrbCmprssrBlwffActtr1OprtnStt "Used to identify the status of Engine Turbocharger Compressor Blowoff Actuator 1.
0000 - Normal
0001 - Alarm (fully operational but needs service)
0010 - Alarm High Severity (functional but transient performance may be reduced)
0011 - Derate ...";
CM_ SG_ 2364553214 EngTrbCmprssrBlowoffActuator1Pos "Actual position of the turbocharger compressor blowoff actuator, where 0% represents fully closed and 100% represents fully open.";
CM_ SG_ 2364553214 EngTrbCmprssrBlwffActtr1DsredPos "The requested position of the Engine Turbocharger Compressor Blowoff actuator by the engine ECM, where 0% represents bypass fully closed and 100% represents fully open.  This is the position that the device is attempting to achieve.";
CM_ SG_ 2364553214 EngTrbCmprssrBlwoffActuator1Temp "Temperature of the Engine Turbocharger Compressor Bypass Actuator 1 drive circuitry. Temperature excursions may affect the torque output.";
CM_ SG_ 2364553214 EngTrbCmprssrBlwffActtr1TmpSttus "Used to identify the status of the Engine Turbocharger Compresssor Blowoff Actuator 1 drive circuitry temperature. Temperature excursions may affect the torque output.
000 - High Most severe
001 - High Least severe
010 - In Range
011 - Low Least ...";
CM_ SG_ 2364553214 EngTrbCmprssrBlwffActtr1PrlmnryF "Used to identify the applicable J1939-73 FMI detected in the Engine Turbocharger Blowoff Actuator 1 by the manufacturer's software. When there is no failure FMI 31 is transmitted. When there are multiple failures, the most severe is transmitted.";
CM_ BO_ 2364547838 "Message that provides the current machine selected speed, direction, and source parameters.";
CM_ SG_ 2364547838 PersistentLimitStatus "Reports the tractor ECU's present limit status associated with a parameter whose commands are presistent  (i.e. hitch position)";
CM_ SG_ 2364547838 MachineSelectedSpeedSource "Indicates the speed source that is currently being reported in the machine speed parameter.";
CM_ SG_ 2364547838 MachineSelectedDirection "Indicates the current direction of travel of the machine.";
CM_ SG_ 2364547838 MachineSelectedDistance "Actual distance traveled by the machine based on the value of selected machine speed.";
CM_ SG_ 2364547838 MachineSelectedSpeed "Reports the value of one of the currently available machine speeds (wheel, ground, or navigational-based) which the machine has determined to best represent the machine's speed.";
CM_ BO_ 2364547326 "Message to transmit data of the towed vehicle to the towing vehicle. See ISO 11992-2.";
CM_ BO_ 2364547070 "Message to transmit data of the towed vehicle to the towing vehicle. See ISO 11992-2.";
CM_ BO_ 2364546814 "Contains parameters that allow the generator control system to control the engine and to provide information about the generator control system";
CM_ SG_ 2364546814 GeneratorGoverningBias "Control signal used to govern the genset's speed or load (depending on isochronous or utility parallel operation, respectively)
NOTE:  If this method of engine control is used, the PGN 0 (TSC1) is not expected to be received by the engine ...";
CM_ BO_ 2364546046 "Message to transmit data of the towing vehicle to the towed vehicle. See ISO 11992-3.";
CM_ BO_ 2364538369 "This proprietary PG uses the Destination Specific PDU Format allowing manufacturers to direct their proprietary communications to a specific destination node.";
CM_ SG_ 2566767614 AccelPedal2Channel3 "Sensor output 3 for the accelerator pedal #2 position when using a redundant-style sensor.  The ratio of actual accelerator pedal position to maximum pedal position. This is for the second occurrence of the accelerator pedal. Although it is used as ...";
CM_ SG_ 2566767614 AccelPedal2Channel2 "Sensor output 2 for the accelerator pedal #2 position when using a redundant-style sensor.  The ratio of actual accelerator pedal position to maximum pedal position. This is for the second occurrence of the accelerator pedal. Although it is used as ...";
CM_ SG_ 2566767614 AccelPedal1Channel3 "Sensor output 3 for the accelerator pedal #1 position when using a redundant-style sensor.  The ratio of actual accelerator pedal position to maximum pedal position. This is for the first occurrence of the accelerator pedal. Although it is used as ...";
CM_ SG_ 2566767614 AccelPedal1Channel2 "Sensor output 2 for the accelerator pedal #1 position when using a redundant-style sensor.  The ratio of actual accelerator pedal position to maximum pedal position. This is for the first occurrence of the accelerator pedal. Although it is used as ...";
CM_ SG_ 2559049470 DesiredEngFuelingState "Devices send this request to the engine controller to:
(a) Shut off engine fueling, but remain prepared to re-start quickly by not shutting down the control system, or
(b) Keep the engine running.
00 Fueling not desired (shut off engine fueling)
 ...";
CM_ SG_ 2559049470 RequestedFuelType "Engine controller receives this request from another control module to select the type of fuel to be used for engine operation.
0x00 - Not available - NONE
0x01 - Gasoline/petrol - GAS
0x02 - Methanol - METH
0x03 - Ethanol - ETH
0x04 - Diesel - ...";
CM_ BO_ 2349596414 "Advanced Emergency Braking System message 2.";
CM_ SG_ 2349596414 AEBS2MessageChecksum "Used to check the message checksum of the transmitting (HMI) unit within the AEBS2 system.
Checksum = (Byte1 + Byte2 + Byte3 + Byte4 + Byte5 + Byte6 + Byte7 + (message counter & 0x0F) + message ID low byte + message ID mid low byte + message ID mid ...";
CM_ SG_ 2349596414 AEBS2MessageCounter "The message counter is increased with every transmitted AEBS2 message.  After reaching a value of 0xF the next value will be 0.";
CM_ SG_ 2349596414 DrvrActvtnDmndFrAdvncdEmrgncyBrk "According to the Vienna world convention on road traffic the driver must be provided with means to deactivate an Advanced Emergency Braking System. This command is to be transmitted from the respective HMI unit to the AEBS unit.
00 - the driver ...";
CM_ BO_ 2362375934 "KWP2000 Mixed physical addressing";
CM_ BO_ 2362310398 "KWP2000 Mixed functional addressing";
CM_ BO_ 2362244862 "This message allows the system to adapt the bus bandwidth to the needs of the user of messages.";
CM_ SG_ 2362244862 DataDictionaryRow "This 4 bit parameter indicates the Row that is to be used within the specific Data Dictionary Table identified by the Implement Type. This is the Group (GRUP) in LBS documents.";
CM_ SG_ 2362244862 DataDictionaryColumn "This 4 bit parameter indicates the Column that is to be used within the specific Data Dictionary Table identified by the Implement Type. This is the Instance (INST) in LBS documents.";
CM_ SG_ 2362244862 ImplementType "This 4 bit parameter indicates which data dictionary page is to be used to locate the identity of the following data.";
CM_ SG_ 2362244862 ImplementPos "This 4 bit parameter of this message will indicate which Implement is referenced within a set of identical Implements.";
CM_ SG_ 2362244862 DataFormat_ErrorCondition "This 2 bit parameter that indicates the format or availability of the data in the following Process Data Parameter.";
CM_ SG_ 2362244862 ProcessDataType "This 2 bit parameter indicates what the data in the following Process Data Parameters is to be used for.";
CM_ SG_ 2362244862 ProcessDataModifier "This 3 bit parameter that indicates how the data in the following Process Data Parameters is to be used when combined with the Process Data Type parameter.";
CM_ SG_ 2362244862 RepetitionRateParameter "This parameter defines the repetition rate of the specified PGN.";
CM_ BO_ 2362179326 "The Process Data message has been defined as a destination specific message implying that the sender must decide which implement should receive the message.Working Set).";
CM_ SG_ 2362179326 ProcessVariableValue "This 4 byte parameter contains the actual data  for the Process Data Message.";
CM_ SG_ 2362179326 DataDictionaryRow "This 4 bit parameter indicates the Row that is to be used within the specific Data Dictionary Table identified by the Implement Type. This is the Group (GRUP) in LBS documents.";
CM_ SG_ 2362179326 DataDictionaryColumn "This 4 bit parameter indicates the Column that is to be used within the specific Data Dictionary Table identified by the Implement Type. This is the Instance (INST) in LBS documents.";
CM_ SG_ 2362179326 ImplementType "This 4 bit parameter indicates which data dictionary page is to be used to locate the identity of the following data.";
CM_ SG_ 2362179326 ImplementPos "This 4 bit parameter of this message will indicate which Implement is referenced within a set of identical Implements.";
CM_ SG_ 2362179326 CountNumber "This parameter indicates which member of the set of possible entities is being referenced. The means of generating this Count Number is explained in the following clause.";
CM_ SG_ 2362179326 DataFormat_ErrorCondition "This 2 bit parameter that indicates the format or availability of the data in the following Process Data Parameter.";
CM_ SG_ 2362179326 ProcessDataType "This 2 bit parameter indicates what the data in the following Process Data Parameters is to be used for.";
CM_ SG_ 2362179326 ProcessDataModifier "This 3 bit parameter that indicates how the data in the following Process Data Parameters is to be used when combined with the Process Data Type parameter.";
CM_ BO_ 2361982718 "Defined in ISO 11783-6  Annex L";
CM_ BO_ 2361917182 "Defined in ISO 11783-6  Annex L";
CM_ BO_ 2361851646 "This message provides the estimated flow of a general purpose valve.  Defined in ISO 11783-7.";
CM_ SG_ 2361851646 ValveFailSafeMode "Command for setting the fail safe mode of a general purpose valve.";
CM_ SG_ 2361851646 ValveState "The measured state of the general purpose valve.   With float enabled, hydraulic fluid may flow to or from the tractor as driven by the implement.";
CM_ SG_ 2361851646 RetractPortEstFlow "The value reported by the controller of flow through the extend port of an auxiliary valve of a tractor";
CM_ SG_ 2361851646 ExtendPortEstFlow "The value reported by the controller of flow through the extend port of an auxiliary valve of a tractor";
CM_ BO_ 2361786110 "This message provides the measurement of a general purpose valve.  Defined in ISO11783-7.";
CM_ SG_ 2361786110 ReturnPortPress "The measured nominal pressure at the return port of an auxiliary valve of a tractor";
CM_ SG_ 2361786110 RetractPortPress "The measured nominal pressure at the retract port of an auxiliary valve of a tractor";
CM_ SG_ 2361786110 ExtendPortPress "The measured nominal pressure at the extend port of an auxiliary valve of a tractor";
CM_ SG_ 2361786110 RetractPortMeasuredFlow "The measured flow through the retract port of an auxiliary valve of a tractor";
CM_ SG_ 2361786110 ExtendPortMeasuredFlow "The measured flow through the extend port of an auxiliary valve of a tractor";
CM_ BO_ 2361720574 "This message provides control of the flow through a general purpose valve.  Defined in ISO 11783-7.";
CM_ SG_ 2361720574 PortFlowCmd "The command to set the flow through the extend or retract port of an auxiliary valve of a tractor";
CM_ BO_ 2361458430 "Proprietarily Configuration message for use in J1939-74.";
CM_ BO_ 2361392894 "Proprietarily Configuration message for use in J1939-74.";
CM_ BO_ 2361327358 "Proprietarily Configuration message for use in J1939-74.";
CM_ BO_ 2361261822 "Proprietarily Configuration message for use in J1939-74.";
CM_ BO_ 2361196286 "Proprietarily Configuration message for use in J1939-74.";
CM_ BO_ 2361130750 "Proprietarily Configuration message for use in J1939-74.";
CM_ BO_ 2361065214 "Proprietarily Configuration message for use in J1939-74.";
CM_ BO_ 2360999678 "Proprietarily Configuration message for use in J1939-74.";
CM_ BO_ 2360934142 "Proprietarily Configuration message for use in J1939-74.";
CM_ BO_ 2360868606 "Proprietarily Configuration message for use in J1939-74.";
CM_ BO_ 2360803070 "Proprietarily Configuration message for use in J1939-74.";
CM_ BO_ 2360737534 "Proprietarily Configuration message for use in J1939-74.";
CM_ BO_ 2360671998 "Proprietarily Configuration message for use in J1939-74.";
CM_ BO_ 2360606462 "Proprietarily Configuration message for use in J1939-74.";
CM_ BO_ 2360540926 "Proprietarily Configuration message for use in J1939-74.";
CM_ BO_ 2360475390 "Proprietarily Configuration message for use in J1939-74.";
CM_ BO_ 2360409854 "Message used to identify the data content (by SPN) of one of the configurable messages
(identified by PGN).";
CM_ BO_ 2360344318 "This message is designed to cause other CAs to respond with the identity of any message that they send in which the particular parameter (identified by specific SPN) is contained";
CM_ BO_ 2360213246 "Steering command expressed as desired curvature";
CM_ BO_ 2360147710 "Machine system feedback detailing status of machine relative to guidance operation";
CM_ BO_ 2360082174 "Used for obtaining status of the client, volume handling, file access, file handling and directory handling.  Description of messages is given in ISO 11783 Part 13.";
CM_ BO_ 2358968062 "Message to transmit data of the towing vehicle to the towed vehicle. See ISO 11992-3.";
CM_ BO_ 2358509310 "A message to change fields of the NAME of a CA";
CM_ BO_ 2358181630 "The PGN is for a sequence control system, such as a headland management system, which includes tractor and implement functions in one system.";
CM_ BO_ 2358116094 "This PGN is for sending response messages from control functions to a Sequence Control Master on the tractor and connected implement(s).";
CM_ BO_ 2358050558 "TheCRO message is the one of two PGNs needed by the CAN Calibration Protocol. It is sent by a tool to send queries or commands to a target ECU.";
CM_ BO_ 2357985022 "The DTO message is the one of two PGNs needed by the CAN Calibration Protocol. It is sent by an ECU in response tool to tool queries or commands.";
CM_ BO_ 2558983934 "The switched power outputs command is sent to the Power Distribution Module (PDM) to change the state of the PDM's switched power outputs.

This command is sent to the PDM as needed to change the power outputs, but no faster than once every 100ms.";
CM_ SG_ 2558983934 SwitchedPowerOutput18Cmd "Desired state of Switched Power Output #18. Used to set the desired state.

00 - Output off
01 - Output on
10 - Reserved
11 - Take no action";
CM_ SG_ 2558983934 SwitchedPowerOutput19Cmd "Desired state of Switched Power Output #19. Used to set the desired state.

00 - Output off
01 - Output on
10 - Reserved
11 - Take no action";
CM_ SG_ 2558983934 SwitchedPowerOutput20Cmd "Desired state of Switched Power Output #20. Used to set the desired state.

00 - Output off
01 - Output on
10 - Reserved
11 - Take no action";
CM_ SG_ 2558983934 SwitchedPowerOutput13Cmd "Desired state of Switched Power Output #13. Used to set the desired state.

00 - Output off
01 - Output on
10 - Reserved
11 - Take no action";
CM_ SG_ 2558983934 SwitchedPowerOutput14Cmd "Desired state of Switched Power Output #14. Used to set the desired state.

00 - Output off
01 - Output on
10 - Reserved
11 - Take no action";
CM_ SG_ 2558983934 SwitchedPowerOutput15Cmd "Desired state of Switched Power Output #15. Used to set the desired state.

00 - Output off
01 - Output on
10 - Reserved
11 - Take no action";
CM_ SG_ 2558983934 SwitchedPowerOutput16Cmd "Desired state of Switched Power Output #16. Used to set the desired state.

00 - Output off
01 - Output on
10 - Reserved
11 - Take no action";
CM_ SG_ 2558983934 SwitchedPowerOutput9Cmd "Desired state of Switched Power Output #9. Used to set the desired state.

00 - Output off
01 - Output on
10 - Reserved
11 - Take no action";
CM_ SG_ 2558983934 SwitchedPowerOutput10Cmd "Desired state of Switched Power Output #10. Used to set the desired state.

00 - Output off
01 - Output on
10 - Reserved
11 - Take no action";
CM_ SG_ 2558983934 SwitchedPowerOutput29Cmd "Desired state of Switched Power Output #29. Used to set the desired state.

00 - Output off
01 - Output on
10 - Reserved
11 - Take no action";
CM_ SG_ 2558983934 SwitchedPowerOutput30Cmd "Desired state of Switched Power Output #30. Used to set the desired state.

00 - Output off
01 - Output on
10 - Reserved
11 - Take no action";
CM_ SG_ 2558983934 SwitchedPowerOutput31Cmd "Desired state of Switched Power Output #31. Used to set the desired state.

00 - Output off
01 - Output on
10 - Reserved
11 - Take no action";
CM_ SG_ 2558983934 SwitchedPowerOutput32Cmd "Desired state of Switched Power Output #32. Used to set the desired state.

00 - Output off
01 - Output on
10 - Reserved
11 - Take no action";
CM_ SG_ 2558983934 SwitchedPowerOutput25Cmd "Desired state of Switched Power Output #25. Used to set the desired state.

00 - Output off
01 - Output on
10 - Reserved
11 - Take no action";
CM_ SG_ 2558983934 SwitchedPowerOutput26Cmd "Desired state of Switched Power Output #26. Used to set the desired state.

00 - Output off
01 - Output on
10 - Reserved
11 - Take no action";
CM_ SG_ 2558983934 SwitchedPowerOutput27Cmd "Desired state of Switched Power Output #27. Used to set the desired state.

00 - Output off
01 - Output on
10 - Reserved
11 - Take no action";
CM_ SG_ 2558983934 SwitchedPowerOutput28Cmd "Desired state of Switched Power Output #28. Used to set the desired state.

00 - Output off
01 - Output on
10 - Reserved
11 - Take no action";
CM_ SG_ 2558983934 SwitchedPowerOutput21Cmd "Desired state of Switched Power Output #21. Used to set the desired state.

00 - Output off
01 - Output on
10 - Reserved
11 - Take no action";
CM_ SG_ 2558983934 SwitchedPowerOutput22Cmd "Desired state of Switched Power Output #22. Used to set the desired state.

00 - Output off
01 - Output on
10 - Reserved
11 - Take no action";
CM_ SG_ 2558983934 SwitchedPowerOutput23Cmd "Desired state of Switched Power Output #23. Used to set the desired state.

00 - Output off
01 - Output on
10 - Reserved
11 - Take no action";
CM_ SG_ 2558983934 SwitchedPowerOutput24Cmd "Desired state of Switched Power Output #24. Used to set the desired state.

00 - Output off
01 - Output on
10 - Reserved
11 - Take no action";
CM_ SG_ 2558983934 SwitchedPowerOutput17Cmd "Desired state of Switched Power Output #17. Used to set the desired state.

00 - Output off
01 - Output on
10 - Reserved
11 - Take no action";
CM_ SG_ 2558983934 SwitchedPowerOutput11Cmd "Desired state of Switched Power Output #11. Used to set the desired state.

00 - Output off
01 - Output on
10 - Reserved
11 - Take no action";
CM_ SG_ 2558983934 SwitchedPowerOutput12Cmd "Desired state of Switched Power Output #12. Used to set the desired state.

00 - Output off
01 - Output on
10 - Reserved
11 - Take no action";
CM_ SG_ 2558983934 SwitchedPowerOutput5Cmd "Desired state of Switched Power Output #5. Used to set the desired state.

00 - Output off
01 - Output on
10 - Reserved
11 - Take no action";
CM_ SG_ 2558983934 SwitchedPowerOutput6Cmd "Desired state of Switched Power Output #6. Used to set the desired state.

00 - Output off
01 - Output on
10 - Reserved
11 - Take no action";
CM_ SG_ 2558983934 SwitchedPowerOutput7Cmd "Desired state of Switched Power Output #7. Used to set the desired state.

00 - Output off
01 - Output on
10 - Reserved
11 - Take no action";
CM_ SG_ 2558983934 SwitchedPowerOutput8Cmd "Desired state of Switched Power Output #8. Used to set the desired state.

00 - Output off
01 - Output on
10 - Reserved
11 - Take no action";
CM_ SG_ 2558983934 SwitchedPowerOutput1Cmd "Desired state of Switched Power Output #1. Used to set the desired state.

00 - Output off
01 - Output on
10 - Reserved
11 - Take no action";
CM_ SG_ 2558983934 SwitchedPowerOutput2Cmd "Desired state of Switched Power Output #2. Used to set the desired state.

00 - Output off
01 - Output on
10 - Reserved
11 - Take no action";
CM_ SG_ 2558983934 SwitchedPowerOutput3Cmd "Desired state of Switched Power Output #3. Used to set the desired state.

00 - Output off
01 - Output on
10 - Reserved
11 - Take no action";
CM_ SG_ 2558983934 SwitchedPowerOutput4Cmd "Desired state of Switched Power Output #4. Used to set the desired state.

00 - Output off
01 - Output on
10 - Reserved
11 - Take no action";
CM_ BO_ 2349727486 "Used to communicate transmission control information";
CM_ SG_ 2349727486 TransMode10 "Indicates whether transmission mode 10 is enabled. Modes are manufacturer specific and are not necessarily mutually exclusive. See also SPN 6568. 

00 Disable
01 Enable
10 Reserved
11 Take no action";
CM_ SG_ 2349727486 TransMode9 "Indicates whether transmission mode 9 is enabled. Modes are manufacturer specific and are not necessarily mutually exclusive. See also SPN 6567. 

00 Disable
01 Enable
10 Reserved
11 Take no action";
CM_ SG_ 2550988542 AccelPedalPos3 "The ratio of actual position of the third analog engine speed/torque request input device (such as an accelerator pedal or throttle lever) to the maximum position of the input device.  This parameter is intended for the third accelerator control in ...";
CM_ BO_ 2349268734 "Message to transmit data of the towed vehicle to the towing vehicle. See ISO 11992-3.";
CM_ BO_ 2349203198 "Message to transmit data of the towing vehicle to the towed vehicle. See ISO 11992-3.";
CM_ SG_ 2566767358 FuelType "Type of fuel currently being utilized by the vehicle
Data Byte - Scaling - External Display
0x00 - Not available - NONE
0x01 - Gasoline/petrol - GAS
0x02 - Methanol - METH
0x03 - Ethanol - ETH
0x04 - Diesel - DSL
0x05 - Liquefied Petroleum ...";
CM_ SG_ 2566767358 EngFuelMassFlowRate "Mass of liquid fuel consumed by engine per unit of time.";
CM_ SG_ 2566767358 EngExhstGsRcrcltn1Valve2PosError "The position error of the Exhaust Gas Recirculation 1 valve 2, determined as the actual position (SPN 3821) minus the commanded position (SPN 3822).";
CM_ SG_ 2566767358 EngExhstGsRcrcltn1Valve1PosError "The position error of the Exhaust Gas Recirculation 1 valve, determined as the actual position (SPN 27) minus the commanded position (SPN 2791).";
CM_ BO_ 2566706686 "Contains information on Diesel Exhaust Fluid Pumps";
CM_ SG_ 2566706686 Aftrtrtmnt1DslExhstFldPumpHeater "Percentage of heating applied to the aftertreatment 1 diesel exhaust fluid pump heater. A value of 0% means no heating applied, a value of 100% means full heating applied. The diesel exhaust fluid pump heater warms the diesel exhaust fluid in the ...";
CM_ SG_ 2566705406 Aftertreatment2ParticulateSensor "The particulate sensor measures the mass concentration of particulate matter in the exhaust downstream of the DPF in exhaust bank 2.";
CM_ SG_ 2566705406 Aftertreatment1ParticulateSensor "The particulate sensor measures the mass concentration of particulate matter in the exhaust downstream of the DPF in exhaust bank 1.";
CM_ BO_ 2566705150 "Request to initiate the self-diagnosis of the NOx sensors implemented in the system.
This request may be sent at any time, but should not be sent if the status parameter indicates the self-diagnosis is not possible (state = 100 in SPNs 5713, 5714, ...";
CM_ SG_ 2566705150 NOxSnsorATI2SelfdiagnosisTrigger "Signal to trigger the self-diagnosis of NOx sensor ATI2 (Aftertreatment Intake Bank 2)
0000 Diagnostic mode disabled
0001 NOx Sensor ATI2 Self Diagnosis Request at Lambda=1.0
0010 NOx Sensor ATI2 Self Diagnosis Request at partial load
0011 NOx ...";
CM_ SG_ 2566705150 NOxSnsorATO2SelfdiagnosisTrigger "Signal to trigger the self-diagnosis of NOx sensor ATO2 (Aftertreatment Outlet Bank 2)
0000 Diagnostic mode disabled
0001 NOx Sensor ATO2 Self Diagnosis Request at Lambda=1.0
0010 NOx Sensor ATO2 Self Diagnosis Request at partial load
0011 NOx ...";
CM_ SG_ 2566705150 NOxSnsorATI1SelfdiagnosisTrigger "Signal to trigger the self-diagnosis of NOx sensor ATI1 (Aftertreatment Intake Bank 1)
0000 Diagnostic mode disabled
0001 NOx Sensor ATI1 Self Diagnosis Request at Lambda=1.0
0010 NOx Sensor ATI1 Self Diagnosis Request at partial load
0011 NOx ...";
CM_ SG_ 2566705150 NOxSnsorATO1SelfdiagnosisTrigger "Signal to trigger the self-diagnosis of NOx sensor ATO1 (Aftertreatment Outlet Bank 1)
0000 Diagnostic mode disabled
0001 NOx Sensor ATO1 Self Diagnosis Request at Lambda=1.0
0010 NOx Sensor ATO1 Self Diagnosis Request at partial load
0011 NOx ...";
CM_ BO_ 2566704382 "Engine Related Parameters";
CM_ SG_ 2566704382 Aftrtrtmnt2OtltGsSnsrPowerSupply "State signal which indicates when the Aftertreatment 2 Outlet Gas Sensor driver output is being driven.  On means the ECU is powering the Aftertreatment 2 Intake Gas Sensor.  Note that the ECU is external to the sensor.
00 – Off
01 – On: The ECU ...";
CM_ SG_ 2566704382 Aftrtrtmnt2IntkGsSnsrPowerSupply "State signal which indicates when the Aftertreatment 2 Intake Gas Sensor driver output is being driven.  On means the ECU is powering the Aftertreatment 2 Intake Gas Sensor.  Note that the ECU is external to the sensor.
00 – Off
01 – On: The ECU ...";
CM_ SG_ 2566704382 Aftrtrtmnt1OtltGsSnsrPowerSupply "State signal which indicates when the Aftertreatment 1 Outlet Gas Sensor driver output is being driven.  On means the ECU is powering the Aftertreatment 1 Intake Gas Sensor.  Note that the ECU is external to the sensor.
00 – Off
01 – On: The ECU ...";
CM_ SG_ 2566704382 Aftrtrtmnt1IntkGsSnsrPowerSupply "State signal which indicates when the Aftertreatment 1 Intake Gas Sensor driver output is being driven.  On means the ECU is powering the Aftertreatment 1 Intake Gas Sensor.  Note that the ECU is external to the sensor.
00 – Off
01 – On: The ECU ...";
CM_ BO_ 2566704126 "Engine Exhaust Gas Recirculation 1 Actuator related parameters";
CM_ SG_ 2566704126 EngExhstGsRcrcltn1Acttr2PrlmnryF "Used to identify the applicable J1939-73 FMI detected in the Engine Exhaust Gas Recirculation 1 Actuator 2 by the manufacturer’s software. When there is no failure FMI 31 is transmitted. When there are multiple failures, the most severe is ...";
CM_ SG_ 2566704126 EngExhstGsRcrcltn1Acttr2OprtnStt "Used to identify the status of Exhaust Gas Recirculation 1 Actuator 2
0000 – Normal
0001 – Alarm (fully operational but needs service)
0010 – Alarm High Severity (functional but transient performance may be reduced)
0011 – Derate Active (torque ...";
CM_ SG_ 2566704126 EngExhstGsRcrcltn1Acttr1OprtnStt "Used to identify the status of Exhaust Gas Recirculation 1 Actuator 1
0000 – Normal
0001 – Alarm (fully operational but needs service)
0010 – Alarm High Severity (functional but transient performance may be reduced)
0011 – Derate Active (torque ...";
CM_ SG_ 2566704126 EngExhstGsRcrcltn1Acttr2DsredPos "The requested position of the Engine Exhaust Gas Recirculation 1 Actuator 2 by the engine ECU, where 0% represents fully closed and 100% represents fully open.

This is the position that the device is attempting to achieve.";
CM_ SG_ 2566704126 EngExhstGsRcrclton1Actuator2Temp "Temperature of the Engine Exhaust Gas Recirculation 1 Actuator 2 drive circuitry.  Temperature excursions may affect the torque output.";
CM_ SG_ 2566704126 EngExhstGsRcrcltn1Acttr2TmpSttus "Used to identify the status of the Engine Exhaust Gas Recirculation 1 Actuator 2 drive circuitry temperature.  Temperature excursions may affect the torque output.
000 – High Most severe
001 – High Least severe
010 – In Range
011 – Low Least ...";
CM_ SG_ 2566704126 EngExhstGsRcrcltn1Acttr1DsredPos "The requested position of the Engine Exhaust Gas Recirculation 1 Actuator 1 by the engine ECU, where 0% represents fully closed and 100% represents fully open.

This is the position that the device is attempting to achieve.";
CM_ SG_ 2566704126 EngExhstGsRcrclton1Actuator1Temp "Temperature of the Engine Exhaust Gas Recirculation 1 Actuator 1 drive circuitry.  Temperature excursions may affect the torque output.";
CM_ SG_ 2566704126 EngExhstGsRcrcltn1Acttr1TmpSttus "Used to identify the status of the Engine Exhaust Gas Recirculation 1 Actuator 1 drive circuitry temperature.  Temperature excursions may affect the torque output.
000 – High Most severe
001 – High Least severe
010 – In Range
011 – Low Least ...";
CM_ SG_ 2566704126 EngExhstGsRcrcltn1Acttr1PrlmnryF "Used to identify the applicable J1939-73 FMI detected in the Engine Exhaust Gas Recirculation 1 Actuator 1 by the manufacturer’s software. When there is no failure FMI 31 is transmitted. When there are multiple failures, the most severe is ...";
CM_ BO_ 2566703870 "Engine Exhaust Gas Recirculation 2 Actuator related parameters";
CM_ SG_ 2566703870 EngExhstGsRcrcltn2Acttr2OprtnStt "Used to identify the status of Exhaust Gas Recirculation 2 Actuator 2
0000 – Normal
0001 – Alarm (fully operational but needs service)
0010 – Alarm High Severity (functional but transient performance may be reduced)
0011 – Derate Active (torque ...";
CM_ SG_ 2566703870 EngExhstGsRcrcltn2Acttr1OprtnStt "Used to identify the status of Exhaust Gas Recirculation 2 Actuator 1
0000 – Normal
0001 – Alarm (fully operational but needs service)
0010 – Alarm High Severity (functional but transient performance may be reduced)
0011 – Derate Active (torque ...";
CM_ SG_ 2566703870 EngExhstGsRcrcltn2Acttr2DsredPos "The requested position of the Engine Exhaust Gas Recirculation 2 Actuator 2 by the engine ECU, where 0% represents fully closed and 100% represents fully open.

This is the position that the device is attempting to achieve.";
CM_ SG_ 2566703870 EngExhstGsRcrclton2Actuator2Temp "Temperature of the Engine Exhaust Gas Recirculation 2 Actuator 2 drive circuitry.  Temperature excursions may affect the torque output.";
CM_ SG_ 2566703870 EngExhstGsRcrcltn2Acttr2TmpSttus "Used to identify the status of the Engine Exhaust Gas Recirculation 2 Actuator 2 drive circuitry temperature.  Temperature excursions may affect the torque output.
000 – High Most severe
001 – High Least severe
010 – In Range
011 – Low Least ...";
CM_ SG_ 2566703870 EngExhstGsRcrcltn2Acttr2PrlmnryF "Used to identify the applicable J1939-73 FMI detected in the Engine Exhaust Gas Recirculation 2 Actuator 2 by the manufacturer’s software. When there is no failure FMI 31 is transmitted. When there are multiple failures, the most severe is ...";
CM_ SG_ 2566703870 EngExhstGsRcrcltn2Acttr1DsredPos "The requested position of the Engine Exhaust Gas Recirculation 2 Actuator 1 by the engine ECU, where 0% represents fully closed and 100% represents fully open.

This is the position that the device is attempting to achieve.";
CM_ SG_ 2566703870 EngExhstGsRcrclton2Actuator1Temp "Temperature of the Engine Exhaust Gas Recirculation 2 Actuator 1 drive circuitry.  Temperature excursions may affect the torque output.";
CM_ SG_ 2566703870 EngExhstGsRcrcltn2Acttr1TmpSttus "Used to identify the status of the Engine Exhaust Gas Recirculation 2 Actuator 1 drive circuitry temperature.  Temperature excursions may affect the torque output.
000 – High Most severe
001 – High Least severe
010 – In Range
011 – Low Least ...";
CM_ SG_ 2566703870 EngExhstGsRcrcltn2Acttr1PrlmnryF "Used to identify the applicable J1939-73 FMI detected in the Engine Exhaust Gas Recirculation 2 Actuator 1 by the manufacturer’s software. When there is no failure FMI 31 is transmitted. When there are multiple failures, the most severe is ...";
CM_ BO_ 2566703614 "This PGN will be used to transmit the Feedback information from the Engine Throttle and Fuel Actuator.";
CM_ SG_ 2566703614 EngTurboWastegateActuator2Temp "Temperature of the Engine Turbocharger Wastegate Actuator 2 drive circuitry.  Temperature excursions may affect the torque output.";
CM_ SG_ 2566703614 EngFuelValve2Temp "Temperature of the Engine Fuel Valve 2 drive circuitry. Temperature excursions may affect the torque output.";
CM_ SG_ 2566703614 EngFuelValve1Temp "Temperature of the Engine Fuel Valve 1 drive circuitry. Temperature excursions may affect the torque output.";
CM_ SG_ 2566703614 EngThrottleValve2Temp "Temperature of the engine throttle valve 2 drive circuitry (SPN 3783).  Temperature excursions may affect the torque output.";
CM_ SG_ 2566703614 EngThrottleValve1Temp "Temperature of the engine throttle valve 1 drive circuitry (SPN 53).  Temperature excursions may affect the torque output.";
CM_ SG_ 2566703358 SrcAddrssOfCntrllngDvcFrFlngStte "The J1939 source address of the device currently controlling the fueling state via SPN 5793.
254 (0xFE) is used to indicate that the Source Address of Controlling Device for Fueling State parameter is supported, but no device is currently ...";
CM_ SG_ 2566703358 EngFuelingInhibitPreventedReason "If Engine Fueling Inhibit Allowed (SPN 5795) indicates that the engine will not inhibit fueling, then this parameter will indicate the reason.
If more than one reason exists at the same time, then it is up to the manufacturer to decide which one to ...";
CM_ SG_ 2566703358 EngFuelingInhibitAllowed "This parameter is broadcast by the engine control system, and indicates to other devices on the network whether or not it will respond to requests to inhibit engine fueling via SPN 5793 Desired Engine Fueling State. With this information, devices ...";
CM_ SG_ 2566703358 FeedbackEngFuelingState "This parameter provides feedback to the network that SPN 5793 Desired Engine Fueling State was honored. SPN 5795 Engine Fueling Inhibit Allowed indicates the engine’s current ability to honor requests via SPN 5793 Desired Engine Fueling State.
00 = ...";
CM_ BO_ 2566702590 "This message contains SCR catalyst gas temperature information for aftertreatment system 1 (or bank 1).";
CM_ SG_ 2566702590 Aftrtrtmnt1SCRIntrmdtGsTmpPrlmnr "Used to identify the applicable J1939-73 FMI detected in the aftertreatment SCR intermediate temperature sensor by the manufacturer’s sensor control software in exhaust bank 1. When there is no failure FMI 31 is sent. In the case of multiple ...";
CM_ SG_ 2566702590 Aftrtrtmnt1SCRIntrmediateGasTemp "Temperature of engine combustion byproducts at an intermediate point in the SCR component in exhaust bank 1.";
CM_ BO_ 2566702334 "This message contains SCR catalyst gas temperature information for aftertreatment system 2 (or bank 2).";
CM_ SG_ 2566702334 Aftrtrtmnt2SCRIntrmdtGsTmpPrlmnr "Used to identify the applicable J1939-73 FMI detected in the aftertreatment SCR intermediate temperature sensor by the manufacturer’s sensor control software in exhaust bank 2. When there is no failure FMI 31 is sent. In the case of multiple ...";
CM_ SG_ 2566702334 Aftrtrtmnt2SCRIntrmediateGasTemp "Temperature of engine combustion byproducts at an intermediate point in the SCR component in exhaust bank 2.";
CM_ BO_ 2566702078 "Gaseous fuel information 4";
CM_ SG_ 2566702078 SupplyGasMethanePercentage "The percentage of methane in the gas supplied to the engine.";
CM_ BO_ 2566701822 "Status information of a hybrid system.";
CM_ SG_ 2566701822 HybridSystemStopIndicator "Signal from a hybrid system indicating that some aspect of its operation is not functioning correctly, and as a result, the vehicle must be stopped. The indicator is typically a lamp. Distinctions in meaning between the continuous and flashing ...";
CM_ SG_ 2566701822 HybridSystemOverheatIndicator "Signal from a hybrid system indicating that at least one of its monitored temperatures is above normal acceptable limits, and as a result, hybrid system operation may be altered or restricted. The indicator is typically a lamp. Distinctions in ...";
CM_ SG_ 2566701822 HybridSystemWarningIndicator "Signal from a hybrid system indicating that some aspect of its operation is not functioning correctly, and as a result, hybrid system operation may be altered or restricted. The indicator is typically a lamp. Distinctions in meaning between the ...";
CM_ BO_ 2431661310 "This message contains aftertreatment intermediate ammonia information for aftertreatment system 2 (or bank 2).";
CM_ SG_ 2431661310 Aftrtrtmnt2SCRIntrmdtNH3GsSn5861 "Indicates the heater status in the warm-up process. Upon receiving a power-up command, the NH3 gas sensor ramps up according to a manufacturer defined profile. The Preheat 1, Preheat 2, and Automatic messages are regions within this profile in ...";
CM_ SG_ 2431661310 Aftrtrtmnt2SCRIntrmdtNH3GsSnsrHt "Used to identify the applicable J1939-73 FMI detected in the heater of the SCR intermediate NH3 exhaust gas sensor by the manufacturer’s sensor control software in exhaust bank 2. When there is no failure FMI 31 is sent. In the case of multiple ...";
CM_ SG_ 2431661310 Aftrtrtmnt2SCRIntrmdtNH3GsSnsrAt "Indicates that the heater element of the aftertreatment SCR intermediate NH3 gas sensor is within the manufacturer’s specified range for accurate measurements in exhaust bank 2.
00 - Heater element is not in range
01 - Heater element is in range
 ...";
CM_ SG_ 2431661310 Aftrtrtmnt2SCRIntrmdtNH3GsSnsrPw "Indicates that the power supplied to the aftertreatment SCR intermediate NH3 gas sensor is within the manufacturer’s specification in exhaust bank 2.
00 - Heater element is not in range
01 - Heater element is in range
10 - Error
11 - Not ...";
CM_ SG_ 2431661310 Aftrtrtmnt2SCRIntrmdtNH3RdngStbl "Indicates that the NH3 reading of the aftertreatment SCR intermediate NH3 sensor is stable as determined by the manufacturer’s control software in exhaust bank 2.

00 - Reading is not stable
01 - Reading is stable
10 - Error
11 - Not available";
CM_ SG_ 2431661310 Aftrtrtmnt2SCRIntrmdtNH3SnsrPrlm "Used to identify the applicable J1939-73 FMI detected in the aftertreatment SCR intermediate NH3 sensor by the manufacturer’s sensor control software in exhaust bank 2. When there is no failure FMI 31 is sent. In the case of multiple failures the ...";
CM_ SG_ 2431661310 Aftrtreatment2SCRIntermediateNH3 "The amount of NH3 in the exhaust aftertreatment system measured by a NH3 sensor at an intermediate point in the SCR system, represented in NH3 molecule parts per million non-NH3 molecules in exhaust bank 2.";
CM_ BO_ 2431661054 "This message contains aftertreatment intermediate ammonia information for aftertreatment system 1 (or bank 1).";
CM_ SG_ 2431661054 Aftrtrtmnt1SCRIntrmdtNH3GsSn5854 "Indicates the heater status in the warm-up process. Upon receiving a power-up command, the NH3 gas sensor ramps up according to a manufacturer defined profile. The Preheat 1, Preheat 2, and Automatic messages are regions within this profile in ...";
CM_ SG_ 2431661054 Aftrtrtmnt1SCRIntrmdtNH3GsSnsrHt "Used to identify the applicable J1939-73 FMI detected in the heater of the outlet NH3 exhaust gas sensor by the manufacturer’s sensor control software in exhaust bank 1. When there is no failure FMI 31 is sent. In the case of multiple failures the ...";
CM_ SG_ 2431661054 Aftrtrtmnt1SCRIntrmdtNH3GsSnsrAt "Indicates that the heater element of the aftertreatment SCR intermediate NH3 gas sensor is within the manufacturer’s specified range for accurate measurements in exhaust bank 1.
00 - Heater element is not in range
01 - Heater element is in range
 ...";
CM_ SG_ 2431661054 Aftrtrtmnt1SCRIntrmdtNH3GsSnsrPw "Indicates that the power supplied to the aftertreatment SCR intermediate NH3 gas sensor is within the manufacturer’s specification in exhaust bank 1.

00 - Power is not in range
01 - Power is in range
10 - Error
11 - Not available";
CM_ SG_ 2431661054 Aftrtrtmnt1SCRIntrmdtNH3RdngStbl "Indicates that the NH3 reading of the aftertreatment SCR intermediate NH3 sensor is stable as determined by the manufacturer’s control software in exhaust bank 1.

00 - Reading is not stable
01 - Reading is stable
10 - Error
11 - Not available";
CM_ SG_ 2431661054 Aftrtrtmnt1SCRIntrmdtNH3SnsrPrlm "Used to identify the applicable J1939-73 FMI detected in the aftertreatment SCR intermediate NH3 sensor by the manufacturer’s sensor control software in exhaust bank 1. When there is no failure FMI 31 is sent. In the case of multiple failures the ...";
CM_ SG_ 2431661054 Aftrtreatment1SCRIntermediateNH3 "The amount of NH3 in the exhaust aftertreatment system measured by a NH3 sensor at an intermediate point in the SCR system, represented in NH3 molecule parts per million non-NH3 molecules in exhaust bank 1.";
CM_ BO_ 2230334206 "The Linear Displacement Sensor is an electromechanical sensor that detects the distance of an object from the body of the sensor.";
CM_ SG_ 2230334206 LnrDsplcmntSnsrSnsrFigureOfMerit "Figure of Merit sensor status of Linear Displacement Sensor.

00    Sensor fully functional
01    Sensor degraded
10    Sensor failed
11    Sensor not available";
CM_ SG_ 2230334206 MeasuredLinearDisplacement "Distance to target as measured by the Linear Displacement Sensor.";
CM_ BO_ 2230333950 "The wand sensor is an electromechanical sensor that detects the angle of deflection of a wand.";
CM_ SG_ 2230333950 WandSensorFigureOfMerit "Figure of Merit sensor status for a wand sensor.

00    Sensor fully functional
01    Sensor degraded
10    Sensor failed
11    Sensor not available";
CM_ SG_ 2230333950 WandAngle "A wand sensor measures the angle of deflection of a wand from its null position. This parameter reports the measured angle of a wand sensor.";
CM_ BO_ 2364551422 "Carries commands received by the wireless transceiver from an off-board transmitter and conveys
the status of the on-board wireless transceiver. The message originates from the on-board wireless
transceiver and is directed to an Electronic Control ...";
CM_ SG_ 2364551422 WirelessSignalStrength1 "The absolute received signal strength of the signal received from the off-board transmitter. The signal strength is reported as a Received Signal Strength Indicator (RSSI) value calculated in dBm.";
CM_ SG_ 2364551422 TransmitterID1 "The ID of the off-board transmitter that sent the incoming message received by the wireless transceiver.";
CM_ SG_ 2364551422 TransmitterCmdState "The command contained in the signal received by the wireless transceiver from an off-board transmitter.
0000b - Stop
0001b - Clear
0010b - Field Test
0011b - Transmitter Test
0100b - Standby
0101b to 1101b - Reserved
1110b - Error
1111b - ...";
CM_ SG_ 2364551422 WirelessRollingMessageCounter "A counter incremented with each instance of the Wireless Status message. The counter shall increment from 0 to 64255, rolling over to 0 on the next increment after 64255. The enables recipients of the Wireless Status message to detect problems with ...";
CM_ BO_ 2364551166 "Advanced Emergency Braking System message 1.";
CM_ SG_ 2364551166 TmeToCollisionWithRelevantObject "The time to collision is the duration after which the predicted travelling paths of host vehicle and relevant object lead to a distance of 0m between both.
Note:  It is up to the system manufacturer to choose a suitable calculation method to ...";
CM_ SG_ 2364551166 BndOffPrbabilityOfRelevantObject "Probabilty if monitored relevant object might start a turning maneuver, which could clear the travelling path of the host vehicle.
000 - no indication for a bend off maneuver of the relevant object
001 - low probability for a bend off maneuver of ...";
CM_ SG_ 2364551166 RlvntObjctDtctdFrAdvncdEmrgncyBr "Indication if the advanced emergency braking system (AEBS) is monitoring a relevant object
000 - no relevant object monitored
001 - relevant object is being monitored
010 - relevant object is not being detected reliably
011..101 - reserved
110 ...";
CM_ SG_ 2364551166 CollisionWarningLevel "To implement different HMI (human machine interface) concepts, e.g. visual only, visual/audible, different warning tones etc., the AEBS provides different levels of collision warning.
0000 - no warning
0001 - warning level 1 - lowest
0010 - ...";
CM_ SG_ 2364551166 AdvncdEmrgencyBrakingSystemState "Current operational state of advanced emergency braking system
0000 - system is not ready (initialization not finished)
0001 - system is temporarily not available (e.g. due to boundary conditions necessary for operation)
0010 - system is ...";
CM_ BO_ 2566730238 "This parameter group transfers status and measured information for a second engine coolant fan.  For systems with a single or the primary fan, see PGN 65213.";
CM_ SG_ 2566730238 Fan2DriveBypassCmdStatus "Status of the Fan Drive Bypass Command for the second fan as being commanded by the ECU.  The fan drive bypass diverts pump pressure away from the hydraulic motor to maintain the fan drive pressure.  0% is defined as no bypass (i.e. diverting no fan ...";
CM_ SG_ 2566730238 HydFan2MotorPress "The hydraulic pressure used to drive the second fan system, sensed before the hydraulic fan motor.";
CM_ SG_ 2566730238 Fan2Speed "The speed of the second fan associated with engine coolant system.";
CM_ SG_ 2566730238 Fan2DriveState "This parameter is used to indicate the current state or mode of operation by the second fan drive.
0000 Fan off
0001 Engine system–General
0010 Excessive engine air temperature
0011 Excessive engine oil temperature
0100 Excessive engine coolant ...";
CM_ SG_ 2566730238 EstPercentFan2Speed "Estimated fan speed as a ratio of the fan drive (current speed) to the fully engaged fan drive (maximum fan speed).  A two state fan (off/on) will use 0% and 100% respectively.  A three state fan (off/intermediate/on) will use 0%, 50% and 100% ...";
CM_ BO_ 2566711038 "Reports vehicle/chassis lubrication systems status";
CM_ SG_ 2566711038 LubricationTimingCycleStatus "Reports the status of the lubrication activation clock.
00 - Paused
01 - Enabled
10 - Error
11 - Not available or not installed
Note:  In some vehicles or machines, lubrication is only required when the vehicle or machine is in certain state e ...";
CM_ SG_ 2566711038 LubricationReservoirLevel "Reports the status of the lubrication system reservior level.  The lubrication reservoir stores the grease for the lubrication system. The lubrication pump draws grease from this reservoir and pushes it into the vehicle/chassis joints
00 - ...";
CM_ SG_ 2566711038 LubricationPumpEnableStatus "Reports the operational status of the lubrication system pump.  In the disabled state, the lubrication pump will not run a lubrication cycle.  In the enabled state, the lubrication system will perform normal operations.
00 - Disabled
01 - Enabled
 ...";
CM_ SG_ 2566711038 LubricationOperationModeStatus "Reports the current operational mode status of the lubrication system.
Automatic is the normal operation mode of lubrication system. In this mode the operator has the privilege to change duty cycle mode, if the lubrication mode in not locked.
In ...";
CM_ SG_ 2566711038 LubricationCycleModeStatus "Reports the current lubrication cycle mode of the lubrication system
000 - Cycle mode # 1 (Lowest Lubrication Frequency)
001 - Cycle mode # 2
010 - Cycle mode # 3 (Highest Lubrication Frequency)
011 to 101 - Reserved
110 - Error
111 - Not ...";
CM_ SG_ 2566711038 LubricationCycleModeLockStatus "Reports status of the ability to change the lubrication cycle mode.  Locking the lubrication mode would prevent the changing of the lubrication cycle mode, perhaps by an operator

00 - Not Locked
01 - Locked
10 - Error
11 - Not available";
CM_ BO_ 2566710782 "Hydraulic Oil Properties.  This hydraulic fluid is for the entire hydraulics system of a piece of equipment.";
CM_ SG_ 2566710782 HydOilTemp "Hydraulic Oil Temperature.  This hydraulic fluid is for the entire hydraulics system of a piece of equipment.";
CM_ SG_ 2566710782 HydOilRelativeDielectricity "Hydraulic oil relative dielectricity used to describe the hydraulic oil quality.  This hydraulic fluid is for the entire hydraulics system of a piece of equipment.";
CM_ SG_ 2566710782 HydOilDensity "Density of hydraulic oil.  This hydraulic fluid is for the entire hydraulics system of a piece of equipment.";
CM_ SG_ 2566710782 HydOilDynamicViscosity "Dynamic viscosity of hydraulic oil.  This hydraulic fluid is for the entire hydraulics system of a piece of equipment.";
CM_ BO_ 2566710526 "Engine Fuel Properties";
CM_ SG_ 2566710526 EngFuelTemp "Engine Fuel Temperature.  See also SPNs 174 or 3468 for alternate resolution.";
CM_ SG_ 2566710526 EngFuelDielectricity "Engine fuel relative dielectricity.";
CM_ SG_ 2566710526 EngFuelDensity "Density of engine fuel";
CM_ SG_ 2566710526 EngFuelDynamicViscosity "Dynamic viscosity of engine fuel";
CM_ BO_ 2432492542 "Contains information about the engine exhaust brake system control.";
CM_ SG_ 2432492542 DsredEngTurbo2TurbineOutletPress "The desired gage pressure of the combustion by-products exiting the turbine side of the turbocharger 5 at the current engine operating conditions.";
CM_ SG_ 2432492542 EngTurbo2TurbineOutletPress "Gage pressure of the combustion by-products exiting the turbine side of the turbocharger 2.";
CM_ SG_ 2432492542 EngExhaustBrakeActuatorCmd "The control command applied to the engine exhaust brake actuator, where 0% represents no braking and 100% represents full braking.";
CM_ SG_ 2432492542 DsredEngTurbo1TurbineOutletPress "The desired gage pressure of the combustion by-products exiting the turbine side of the turbocharger 1 at the current engine operating conditions.";
CM_ SG_ 2432492542 EngTurbo1TurbineOutletPress "Gage pressure of the combustion by-products exiting the turbine side of the turbocharger 1.";
CM_ BO_ 2566710014 "The status of Supplemental Fan. This is a supplemental fan used for additional cooling beyond that of the primary cooling fan system. For example, this fan could be used to provide additional cooling to an aftertreatment system";
CM_ SG_ 2566710014 SupplementalFanPower "Estimated Power output of Supplemental Fan";
CM_ SG_ 2566710014 SupplementalFanCurrent "Measured electrical current of supplemental fan drive.";
CM_ SG_ 2566710014 SupplementalFanSpeed "Measured speed of supplemental fan.";
CM_ SG_ 2566710014 SupplementalFanCtrlECUTemp "Measured temperature of Supplemental Fan Controller ECU.";
CM_ SG_ 2566710014 SupplementalFanDriveStatus "The drive status of the Supplemental Fan. This status parameter indicates the overall health of the fan drive. It will indicate that the fan is working OK or if there is an internal fault such as open winding or internal short circuit.
0000 ...";
CM_ SG_ 2566710014 SupplementalFanCtrlTempStatus "Internal Controller Temperature Status of Supplemental Fan.

000   High most severe 
001   High Least severe 
010   In Range 
011   Low Least severe 
100   Low Most severe 
101   Not Defined 
110   Error 
111   Not available";
CM_ SG_ 2566710014 SupplementalFanVelocityStatus "Status of the rotational velocity of Supplemental Fan. Used to indicate if the fan is spinning at the desired speed. If fan is not able to obtain the commanded speed, velocity error is indicated. If fan is unable to spin, the fan is in Fan Stall ...";
CM_ SG_ 2566710014 SupplementalFanDirectionStatus "Rotational Direction of Supplemental Fan. Fan could be spinning forward or reverse.

00   Forward
01   Reverse
10   Error
11   Not available/Not installed";
CM_ SG_ 2566710014 SupplementalFanEnableStatus "Enable/Disable Status of Supplemental Fan.

00   Disabled
01   Enabled
10   Error
11   Not available/Not installed";
CM_ SG_ 2566709758 HighResolutionEngFuelRate "Amount of fuel consumed by engine per unit of time.  

NOTE - See SPN 183 for alternate resolution.";
CM_ BO_ 2566709502 "The purpose of this PGN is to group parameters about the diesel particulate filter regeneration control.";
CM_ SG_ 2566709502 Aftertreatment2FuelMassRate "Mass rate of total fuel being delivered to Atertreatment 2 for DPF regeneration.";
CM_ SG_ 2566709502 Aftertreatment1FuelMassRate "Mass rate of total fuel being delivered to aftertreatment 1 for DPF regeneration.";
CM_ SG_ 2566709502 RelativeUnburnedFuelMassFromEng "The unburned amount of diesel fuel coming out of the engine. This fuel increases the temperature while oxidated in the DOC. Therefore, this amount of fuel also needs to be taken into account of the HCD temperature controller.";
CM_ SG_ 2566709502 Aftrtrtmnt1DslPrtcltFltrIntkTmpS "Set point temperature for the particulate filter (DPF) regeneration at the intake to the DPF for Exhaust bank 1.";
CM_ BO_ 2566709246 "12th PGN which identifies parameters that are either measuring various pressures within the engine or identifying engine fluid levels";
CM_ SG_ 2566709246 EngFuelFilterDegradation "The estimated percentage relative to the useful life of the engine fuel filter.
This is not a calculation of the physical restriction of the filter.  0% is typical of a new filter.  100% is typical of an end of life filter, the filter should be ...";
CM_ SG_ 2566709246 EngFilteredFuelDeliveryAbsPress "Absolute pressure of fuel in system as delivered from supply pump to the injection pump after the pressure side fuel filter.  See SPN 5579 for gage pressure of fuel in system after the pressure side fuel filter.";
CM_ SG_ 2566709246 EngFilteredFuelDeliveryPress "Gage pressure of fuel in system as delivered from supply pump to the injection pump after the pressure side fuel filter.  See SPN 5580 for absolute pressure of fuel in system after the pressure side fuel filter.";
CM_ SG_ 2566709246 EngFuelDeliveryAbsPress "Absolute pressure of fuel in system as delivered from supply pump to the injection pump.  See also SPN 94 for Fuel Delivery Pressure (Gage).";
CM_ BO_ 2566708990 "This PGN contains information about the Aftertreatment 1 Air Control.
NOTE: This message will be transmitted by the engine or aftertreatment controller. Other aftertreatment air control information could be added in the future.";
CM_ SG_ 2566708990 Aftertreatment1SecondAirAbsPress "Absolute pressure of the secondary air for aftertreatment 1. Secondary air is air provided to the exhaust system (per SAE J2403).

For gage pressure, see SPN 3837.";
CM_ BO_ 2566708734 "This PGN contains information about the Aftertreatment 2 Air Control.
NOTE: This message will be transmitted by the engine or aftertreatment controller. Other aftertreatment air control information could be added in the future.";
CM_ SG_ 2566708734 Aftertreatment2SecondAirAbsPress "Absolute pressure of the secondary air for aftertreatment 2. Secondary air is air provided to the exhaust system (per SAE J2403).

For gage pressure, see SPN 3838.";
CM_ BO_ 2566708478 "Cruise Control / Vehicle Speed 3";
CM_ SG_ 2566708478 AEBSReadinessState "Advanced emergency braking systems (AEBS) will limit the engine torque via TSC1 during warning and braking phases. Therefore the engine controller gives a feedback to the AEBS if it is configured and able to obey these limitation commands.
00 - Off ...";
CM_ SG_ 2566708478 SrcAddrssOfCntrllngDvcFrPsngCrsC "The source address of the SAE J1939 device that is currently sending the Cruise Control Pause Command (SPN 5605).
If there are multiple devices sending Cruise Control Pause Command with a value of 01, then the value transmitted for this parameter ...";
CM_ SG_ 2566708478 SrcAddrssOfCntrllngDvcFrDsblngCr "The source address of the SAE J1939 device that is currently sending the Cruise Control Disable Command (SPN 5603).
If there are multiple devices sending Cruise Control Disable Command with a value of 01, then the value transmitted for this ...";
CM_ SG_ 2566708478 CruiseCtrlSystemCmdState "Indicates the current state of the cruise control system due to the Cruise Control System Commands, which include Cruise Control Disable Command (SPN 5603), Cruise Control Resume Command (SPN 5604), and Cruise Control Pause Command (SPN 5605).
000 ...";
CM_ SG_ 2566708478 AdptiveCruiseCtrlReadinessStatus "This parameter is used to indicate an application's state of readiness for responding to commands from an adaptive cruise control system controller.
00 - Off -- Cruise Control System is not configured to accept commands from an adaptive cruise ...";
CM_ BO_ 2566708222 "This message is used to specify up to 4 soot sensor analysis frequencies to request the soot sensor signal data associated with those analysis frequencies for aftertreatment 1 diesel particulate filter 1.";
CM_ SG_ 2566708222 Aftrtrtmnt1DslPrtcltFltr1StS5635 "Fourth requested analysis frequency for the diesel particulate filter 1 soot sensor.";
CM_ SG_ 2566708222 Aftrtrtmnt1DslPrtcltFltr1StS5634 "Third requested analysis frequency for the diesel particulate filter 1 soot sensor.";
CM_ SG_ 2566708222 Aftrtrtmnt1DslPrtcltFltr1StS5633 "Second requested analysis frequency for the diesel particulate filter 1 soot sensor.";
CM_ SG_ 2566708222 Aftrtrtmnt1DslPrtcltFltr1StSnsrA "First requested analysis frequency for the diesel particulate filter 1 soot sensor.";
CM_ BO_ 2566707966 "This message is used report the analysis frequency and associated soot sensor signal data for two of the requested analysis frequencies for the aftertreatment 1 diesel particulate filter 1.";
CM_ SG_ 2566707966 Aftrtrtmnt1DslPrtcltFltr1StS5639 "The soot signal attenuation measurement for analysis frequency 2 for the diesel particulate filter 1 soot sensor.  See SPN 5633.";
CM_ SG_ 2566707966 Aftrtrtmnt1DslPrtcltFltr1StS5638 "The analysis frequency associated with the frequency 2 soot signal for the diesel particulate filter 1 soot sensor.  See SPN 5633.";
CM_ SG_ 2566707966 Aftrtrtmnt1DslPrtcltFltr1StSnsrF "The soot signal attenuation measurement for analysis frequency 1 for the diesel particulate filter 1 soot sensor.  See SPN 5632.";
CM_ SG_ 2566707966 Aftrtrtmnt1DslPrtcltFltr1StSnsrA "The analysis frequency associated with the frequency 1 soot signal for the diesel particulate filter 1 soot sensor.  See SPN 5632.";
CM_ BO_ 2566707710 "This message is used report the analysis frequency and associated soot sensor signal data for two of the requested analysis frequencies for the aftertreatment 1 diesel particulate filter 1.";
CM_ SG_ 2566707710 Aftrtrtmnt1DslPrtcltFltr1StS5643 "The soot signal attenuation measurement for analysis frequency 4 for the diesel particulate filter 1 soot sensor.  See SPN 5635.";
CM_ SG_ 2566707710 Aftrtrtmnt1DslPrtcltFltr1StS5642 "The analysis frequency associated with the frequency 4 soot signal for the diesel particulate filter 1 soot sensor.  See SPN 5635.";
CM_ SG_ 2566707710 Aftrtrtmnt1DslPrtcltFltr1StSnsrF "The soot signal attenuation measurement for analysis frequency 3 for the diesel particulate filter 1 soot sensor.  See SPN 5634.";
CM_ SG_ 2566707710 Aftrtrtmnt1DslPrtcltFltr1StSnsrA "The analysis frequency associated with the frequency 3 soot signal for the diesel particulate filter 1 soot sensor.  See SPN 5634.";
CM_ BO_ 2360016638 "Used for send Status of the client to the file server, volume handling, file access, file handling and directory handling.  Description of messages is given in ISO 11783 Part 13.";
CM_ BO_ 2365423102 "Reserved for FMS Telltale Status";
CM_ BO_ 2297441790 "The acceleration sensor message shall provide a measurement of the vehicle's acceleration in the lateral, longitudinal, and vertical axes.  The vehicle dynamics measurements in this message shall be according to a Z-Up axis system as referenced in ...";
CM_ SG_ 2297441790 SpprtVrblTrnsRpttnRtFrAcclrtnSns "Indicates which acceleration transmission rate are supported by the ECU in addition to the required 10 ms transmission rate.
Bit Position                                           Transmission Rate
1 (bit position 7.7 of PGN 61485)      0 = 20 ms ...";
CM_ SG_ 2297441790 VrtclAcclrtnExRangeFigureOfMerit "Figure of merit for vertical acceleration measurement.
00 = vertical acceleration is fully functional.  Data is within sensor specification
01 = verticalacceleration is degraded.  Data is suspect due to enviromental conditions
10 = error
11 = ...";
CM_ SG_ 2297441790 LngtdnlAcclrtnExRngFigureOfMerit "Figure of merit for longitudinal acceleration measurement.
00 = longitudinal acceleration is fully functional.  Data is within sensor specification
01 = longitudinal acceleration is degraded.  Data is suspect due to enviromental conditions
10 = ...";
CM_ SG_ 2297441790 LtrlAcclrtonExRangeFigureOfMerit "Figure of merit for lateral acceleration measurement.
00 = lateral acceleration is fully functional.  Data is within sensor specification
01 = lateral acceleration is degraded.  Data is suspect due to enviromental conditions
10 = error
11 = not ...";
CM_ SG_ 2297441790 VerticalAccelerationExRange "Indicates vertical acceleration of the vehicle and the effect of gravity (the component of vehicle acceleration vector along the Z-axis).  A positive vertical acceleration signal of 1 gravity results when the vehicle is stationary on a horizontal ...";
CM_ SG_ 2297441790 LongitudinalAccelerationExRange "Indicates longitudinal acceleration of the vehicle (the component of vehicle acceleration vector along the X-axis).  A positive longitudinal acceleration signal results when the vehicle speed increases in the forward direction.  Longitudinal ...";
CM_ SG_ 2297441790 LateralAccelerationExRange "Indicates lateral acceleration of the vehicle (the component of vehicle acceleration vector along the Y-axis).  A positive lateral acceleration signal results when the vehicle is accelerated to the left.  This parameter is defined according to a ...";
CM_ BO_ 2566699006 "Hybrid system voltage information";
CM_ SG_ 2566699006 HybridBatteryPackRemainingCharge "Indicates the hybrid battery pack remaining charge. 0% means no charge remaining, 100% means full charge remaining.";
CM_ BO_ 2364549630 "The Slope Sensor Information 2 message shall provide a measurement of the vehicle's extended pitch angle and a measurement of the vehicle's extended roll angle.  The vehicle dynamics measurements in this message shall be according to a Z-Down axis ...";
CM_ SG_ 2364549630 RllAndPtchExRngMasurementLatency "Time between start of sensor processing and CAN transmission";
CM_ SG_ 2364549630 RollAngleExRangeFigureOfMerit "Figure of merit for roll angle measurement.

00 = Roll angle fully functional. Data is within sensor specification.
01 = Roll angle degraded. Data is suspect due to environmental conditions.
10 = Error
11 = Not available";
CM_ SG_ 2364549630 RollAngleExRangeCompensation "Compensated mode for the roll angle measurement.  Compensation is the use of multiple sensors together to enhance the output of the roll angle measurement.

00 = On
01 = Off
10 = Error
11 = Not Available";
CM_ SG_ 2364549630 PitchAngleExRangeFigureOfMerit "Figure of merit for pitch angle measurement.

00 = Pitch angle fully functional. Data is within sensor specification.
01 = Pitch angle degraded. Data is suspect due to environmental conditions.
10 = Error
11 = Not available";
CM_ SG_ 2364549630 PitchAngleExRangeCompensation "Compensated mode for the pitch measurement.  Compensation is the use of multiple sensors together to enhance the output of the pitch measurement.

00 = On
01 = Off
10 = Error
11 = Not Available";
CM_ SG_ 2364549630 RollAngleExRange "The angle between the vehicle y-axis and the ground plane (i.e. rotation about the X-axis).  The roll angle for a roll to the right is reported with a positive value. Roll angle is the same for both Z-Down and Z-Up axis systems, since both systems ...";
CM_ SG_ 2364549630 PitchAngleExRange "The angle between the vehicle x-axis and the ground plane (i.e. rotation about the vehicle Y-axis).  The pitch angle for an angle of ascent is reported with a positive value. This parameter is defined according to a Z-Down axis system and the sign ...";
CM_ BO_ 2499614462 "Message containing status of Occupant Classification System for driver, passenger and rear seating positions. The PGN becomes updated every time a Beltlock Status changes in the Beltlock and Airbag Deactivation PGN.";
CM_ SG_ 2499614462 OccpntClssficationSystem10Status "State of Occupant Classification System for seat position 10.

00 = empty
01 = occupied
10 = Error - Classification cannot be determined
11 = not available";
CM_ SG_ 2499614462 OccpntClssificationSystem9Status "State of Occupant Classification System for seat position 9.

00 = empty
01 = occupied
10 = Error - Classification cannot be determined
11 = not available";
CM_ SG_ 2499614462 OccpntClssificationSystem8Status "State of Occupant Classification System for seat position 8.

00 = empty
01 = occupied
10 = Error - Classification cannot be determined
11 = not available";
CM_ SG_ 2499614462 OccpntClssificationSystem7Status "State of Occupant Classification System for seat position 7.

00 = empty
01 = occupied
10 = Error - Classification cannot be determined
11 = not available";
CM_ SG_ 2499614462 OccpntClssificationSystem6Status "State of Occupant Classification System for seat position 6.

00 = empty
01 = occupied
10 = Error - Classification cannot be determined
11 = not available";
CM_ SG_ 2499614462 OccpntClssificationSystem5Status "State of Occupant Classification System for seat position 5.

00 = empty
01 = occupied
10 = Error - Classification cannot be determined
11 = not available";
CM_ SG_ 2499614462 OccpntClssificationSystem4Status "State of Occupant Classification System for seat position 4.

00 = empty
01 = occupied
10 = Error - Classification cannot be determined
11 = not available";
CM_ SG_ 2499614462 OccpntClssificationSystem3Status "State of Occupant Classification System for seat position 3.

00 = empty
01 = occupied
10 = Error - Classification cannot be determined
11 = not available";
CM_ SG_ 2499614462 PssngrOccpntClssfctnSystemStatus "State of Occupant Classification System for passenger.

000 = empty
001 = child
010 = small adult
011 = adult
100 = large adult
101 = Error - Classification of occupant cannot be determined
111 = not available";
CM_ SG_ 2499614462 DrvrOccpntClssfctionSystemStatus "State of Occupant Classification System for driver.

000 = empty
001 = child
010 = small adult
011 = adult
100 = large adult
101 = reserved
110 = Error - Classification of occupant cannot be determined
111 = not available";
CM_ BO_ 2560098046 "Used to report the current state of the Noise Control System.";
CM_ SG_ 2560098046 CabNoiseCtrlTuningStatus "This parameter returns the current status of tuning function of the Cab Noise Control system.    When the tuning state is active, the Cab Noise Control System adjusts certain system characteristics (e.g. to account for sensor and/or transducer ...";
CM_ SG_ 2560098046 CabNoiseCtrlStatus "This parameter returns the current status of the Cab Noise Control system.

00 - Cab Noise Control System ON-Line
01 - Cab Noise Control System OFF-Line
10 - Error Indicator
11 - Not Available/Not Requested";
CM_ BO_ 2560163582 "Used to issue commands to the Noise Control System.  This command PGN typically originates from either a Cab control panel or a diagnostic tool.";
CM_ SG_ 2560163582 CabNoiseCtrlTuningCmd "Command values for the Tuning State of the Cab Noise Control System.  The Tuning State allows the Cab Noise Control System to adjust certain system characteristics (e.g. to account for microphone or speaker degradation over time).
000 - Activate ...";
CM_ SG_ 2560163582 CabNoiseCtrlCmd "Command signal to change the state of the Cab Noise Control System to on-line or off-line

00 - Take Cab Noise Control System Off Line
01 - Bring Cab Noise Control System On Line
10 - Reserved
11 - Don't Care/Not Commanded";
CM_ BO_ 2297441534 "This message carries data related to the status of the magnetic material handling system, possibly including the generator that provides power to the magnet.";
CM_ SG_ 2297441534 MagnetGeneratorCtrl "Command signal used to Enable and Disable the Generator controlling a Magnet.

00  Off, Disable Generator
01  On, Enable Generator
10  Reserved
11  Take No Action";
CM_ SG_ 2297441534 DropRelayCtrl "Command signal used to Engage and Disengage the Drop Relay controlling a Steady-State Magnet.

00 = Off, Disable Drop Relay Request
01 = On, Enable Drop Relay Request
10 = Reserved
11 = Take No Action";
CM_ SG_ 2297441534 LiftRelayCtrl "Command signal used to Engage and Disengage the Lift Relay controlling a Steady-State Magnet.

00 = Off, Disable Lift Relay Request 
01 = On, Enable Lift Relay Request
10 = Reserved
11 = Take No Action";
CM_ SG_ 2297441534 MaterialDropActiveStatus "The status of Material Drop Relay. When it is on, the generator generates reverse direction current so that the material handler machine can release material.

00 = Off
01 = On
10 = Error
11 = Not Available";
CM_ SG_ 2297441534 MaterialLiftActiveStatus "The status of Material Lift Relay. When it is on, the generator generates forward direction current so that the material handler machine can pick up material.

00 = Off
01 = On
10 = Error
11 = Not Available";
CM_ SG_ 2297441534 GneratorCurrentBoostActiveStatus "Status of generator current boost relay that can boost the generator output current for picking-up material operations. When this relay is \"on\", the generator is generating the maximum current for the material handler machine to pick-up material ...";
CM_ SG_ 2297441534 MaterialDropSwitch "This is a switch that can be used to enable the drop functionality of the Material Handler machine.

00 = Don't Drop
01 = Drop
10 = Error
11 = Not Available";
CM_ SG_ 2297441534 MaterialLiftSwitch "This is a switch that can be used to enable the lift functionality of the Material Handler machine. When it is activated, the magnet is energized to pick up material.

00 = Don't Lift
01 = Lift
10 = Error
11 = Not Available";
CM_ SG_ 2297441534 MagnetReverseCurrent "A reverse current being supplied to the electric magnet to reduce the forward current generated magnet field as quick as possible so that the magnet can release material as fast as possible.";
CM_ SG_ 2297441534 MagnetForwardCurrent "The forward current being supplied by the generator to the electric magnet to create a magnet field to lift material.";
CM_ BO_ 2566722302 "This message carries data related to the status of the magnetic material handling system, possibly including the generator that provides power to the magnet.";
CM_ SG_ 2566722302 GeneratorDutyCycleExceededStatus "The status of the duty cycle of the generator usage, indicating if the generator has been on for too much time within a defined time window.  The duty cycle is the ratio of the time the generator is on and the time the generator is off within a time ...";
CM_ SG_ 2566722302 VoltageMonitorActiveStatus "Status of Voltage Monitor Relay. When it is activated, the Generator Voltage Monitor is connected to the generator output line so that the generator output voltage range could be monitored.
00 = Monitor is Off
01 = Monitor is On
10 = Error
11 = ...";
CM_ SG_ 2566722302 GensetEnableActiveStatus "Status of the Genset Enable Relay that enables or disables the Genset.

00 = Not Enabled
01 = Enabled
10 = Error
11 = Not Avaialble";
CM_ SG_ 2566722302 ReverseCurrentRangeSetting "The operator setting for the Reverse Current. The setting defines the maximum reverse current. The actual current limits are specific to the application.
00000 = 1
00001 = 2
00010 = 3
00011 = 4
00100 = 5
00101 = 6
00110 = 7
00111 = 8
01000 ...";
CM_ SG_ 2566722302 GensetSoftstartActiveStatus "The Genset Softstart Active Status refers to the status of the genset softstart relay. The moment the Genset System is started, this relay is activated. As a result, the hydraulic power is hold on for a short period of time, and this relay will be ...";
CM_ SG_ 2566722302 Grapple_MagnetSelectionSwitch "This is a switch that can be used to select either the Grapple or Magnet function of the material handler machine.

00 = Grapple Selected
01 = Magnet Selected
10 = Error
11 = Not Available";
CM_ SG_ 2566722302 GnstSystmOtputVoltageRangeStatus "Status of generator voltage in or out of desired operating range.

00 = Out of Range 
01 = In Range
10 = Error
11 = Not Available";
CM_ SG_ 2566722302 GeneratorOverheatStatus "The Status of Generator being Overheated.

00 = Not Overheat
01 = Overheat
10 = Error
11 = Not Available";
CM_ BO_ 2566722558 "This message carries data related to the configuration of the magnetic material handling system, possibly including the generator that provides power to the magnet.";
CM_ SG_ 2566722558 MagnetRatedPower "The rated power that the magnet can accept during material holding operations.  Note that the magnet may experience more power over short intervals, such as during initial activation of the magnet circuit to pick up material.";
CM_ SG_ 2566722558 MagnetBoostTime "The duration of time after the activation of the magnet circuit that a relatively high current is sent to the magnet for material pick up operations. This time is called boost time. After the boost time expires, a lower operation current is sent to ...";
CM_ BO_ 2560032510 "Low Voltage Disconnect (LVD) Set Operating Mode is sent to the LVD to either manuallly override the normal LVD function and force the outputs to be disconnected or connected, or to put the LVD back into normal mode.";
CM_ SG_ 2560032510 LwVltgDscnnctDsiredOperatingMode "Desired Operating Mode of the LVD.  Used to issue a J1939 request to the LVD to change modes.

0000 - Automatic
0001-0011 - Reserved
0100 - Manual Disconnect
0101 - Manual Connect
0110-1110 - Reserved
1111 - No change";
CM_ BO_ 2566717950 "Status of the Low-Voltage Disconnect (LVD) device.";
CM_ SG_ 2566717950 LowVoltageDisconnectTemp "Internal temperature of the LVD.";
CM_ SG_ 2566717950 LwVltgeDisconnectVoutOutputState "State of the Vout Output from the LVD.  Vout is the LVD's main internal, controllable, high-current output.  If the LVD supports prioritization, this circuit will be the last to disconnect and the first to reconnect.
0000 - Output off or ...";
CM_ SG_ 2566717950 LowVoltageDisconnectOutput1State "State of the Output #1 from the LVD.  Output #1 controls an external load or relay.  This external load could be independent of the main output, and may apply to an application specific circuit or zone.  If the LVD supports prioritization, this ...";
CM_ SG_ 2566717950 LowVoltageDisconnectOutput2State "State of the Output #2 from the LVD.  Output #2 controls an external load or relay.  This external load could be independent of the main output, and may apply to an application specific circuit or zone.  If the LVD supports prioritization, this ...";
CM_ SG_ 2566717950 LowVoltageDisconnectOutput3State "State of the Output #3 from the LVD.  Output #3 controls an external load or relay.  This external load could be independent of the main output, and may apply to an application specific circuit or zone.  If the LVD supports prioritization, this ...";
CM_ SG_ 2566717950 LwVltgDscnnctCrrentOperatingMode "Current operating mode of the LVD.  The current mode is dependent on the state of the Manual Disconnect/Connect hardwired inputs and on the most-recent received LVD Set Desired Operating Mode message.  The hardwired inputs have priority over the LVD ...";
CM_ SG_ 2566717950 LwVltgDscnnectManualConnectState "State of the Manual Connect hardwired input to the LVD.  Manual Connect is used to override the LVD's normal activlty and connect all of the LVD outputs.  Manual Connect has priority over the Manual Dicsonnect hardwired input and all LVD Set ...";
CM_ SG_ 2566717950 LwVltgDscnnctMnalDisconnectState "State of the Manual Disconnect hardwired input to the LVD.  Manual Disconnect is used to override the LVD's normal activlty and dicconnect all of the LVD outputs.  Manual Disconnect is lower in priority than the Manual Connect hardwired input, but ...";
CM_ BO_ 2499604222 "This PGN will be used to communicate the reference elvation information for the land leveling system.  It will communicate the left and right blade offset data and left and right elevation deviation data.";
CM_ SG_ 2499604222 BldReferenceElevationOffsetRight "Indicates the blade's right elevation offset with respect to the reference elevation.  An offset of 0 m represents no offset from the reference elevation.  A positive number indicates that the offset elevation is above the original reference ...";
CM_ SG_ 2499604222 BldeReferenceElevationOffsetLeft "Indicates the blade's left elevation offset with respect to the reference elevation.  An offset of 0 m represents no offset from the reference elevation.  A positive number indicates that the offset elevation is above the original reference ...";
CM_ SG_ 2499604222 BladeElevationDeviationRight "Indicate the blade's right elevation deviation with respect to the reference elevation.  Serves as an indication of how far the left end of the blade is above or below grade.  A positive number indicates that the blade is above the desired grade.  A ...";
CM_ SG_ 2499604222 BladeElevationDeviationLeft "Indicate the blade's left elevation deviation with respect to the reference elevation.  Serves as an indication of how far the left end of the blade is above or below grade.  A positive number indicates that the blade is above the desired grade.  A ...";
CM_ BO_ 2358902526 "Used to transfer joystick lamp command informations which are used to switch on/off/blinking joystick 1...3 lamps 1...10.";
CM_ SG_ 2358902526 Joystick3Lamp10Cmd "Tells joystick 3 to switch on/off/blinking lamp 10.

00 - Off
01 - On
10 - Blinking
11 - Don't care / Take no action";
CM_ SG_ 2358902526 Joystick3Lamp9Cmd "Tells joystick 3 to switch on/off/blinking lamp 9.

00 - Off
01 - On
10 - Blinking
11 - Don't care / Take no action";
CM_ SG_ 2358902526 Joystick3Lamp8Cmd "Tells joystick 3 to switch on/off/blinking lamp 8.

00 - Off
01 - On
10 - Blinking
11 - Don't care / Take no action";
CM_ SG_ 2358902526 Joystick3Lamp7Cmd "Tells joystick 3 to switch on/off/blinking lamp 7.

00 - Off
01 - On
10 - Blinking
11 - Don't care / Take no action";
CM_ SG_ 2358902526 Joystick3Lamp6Cmd "Tells joystick 3 to switch on/off/blinking lamp 6.

00 - Off
01 - On
10 - Blinking
11 - Don't care / Take no action";
CM_ SG_ 2358902526 Joystick3Lamp5Cmd "Tells joystick 3 to switch on/off/blinking lamp 5.

00 - Off
01 - On
10 - Blinking
11 - Don't care / Take no action";
CM_ SG_ 2358902526 Joystick3Lamp4Cmd "Tells joystick 3 to switch on/off/blinking lamp 4.

00 - Off
01 - On
10 - Blinking
11 - Don't care / Take no action";
CM_ SG_ 2358902526 Joystick3Lamp3Cmd "Tells joystick 3 to switch on/off/blinking lamp 3.

00 - Off
01 - On
10 - Blinking
11 - Don't care / Take no action";
CM_ SG_ 2358902526 Joystick3Lamp2Cmd "Tells joystick 3 to switch on/off/blinking lamp 2.

00 - Off
01 - On
10 - Blinking
11 - Don't care / Take no action";
CM_ SG_ 2358902526 Joystick3Lamp1Cmd "Tells joystick 3 to switch on/off/blinking lamp 1.

00 - Off
01 - On
10 - Blinking
11 - Don't care / Take no action";
CM_ SG_ 2358902526 Joystick2Lamp10Cmd "Tells joystick 2 to switch on/off/blinking lamp 10.

00 - Off
01 - On
10 - Blinking
11 - Don't care / Take no action";
CM_ SG_ 2358902526 Joystick2Lamp9Cmd "Tells joystick 2 to switch on/off/blinking lamp 9.

00 - Off
01 - On
10 - Blinking
11 - Don't care / Take no action";
CM_ SG_ 2358902526 Joystick2Lamp8Cmd "Tells joystick 2 to switch on/off/blinking lamp 8.

00 - Off
01 - On
10 - Blinking
11 - Don't care / Take no action";
CM_ SG_ 2358902526 Joystick2Lamp7Cmd "Tells joystick 2 to switch on/off/blinking lamp 7.

00 - Off
01 - On
10 - Blinking
11 - Don't care / Take no action";
CM_ SG_ 2358902526 Joystick2Lamp6Cmd "Tells joystick 2 to switch on/off/blinking lamp 6.

00 - Off
01 - On
10 - Blinking
11 - Don't care / Take no action";
CM_ SG_ 2358902526 Joystick2Lamp5Cmd "Tells joystick 2 to switch on/off/blinking lamp 5.

00 - Off
01 - On
10 - Blinking
11 - Don't care / Take no action";
CM_ SG_ 2358902526 Joystick2Lamp4Cmd "Tells joystick 2 to switch on/off/blinking lamp 4.

00 - Off
01 - On
10 - Blinking
11 - Don't care / Take no action";
CM_ SG_ 2358902526 Joystick2Lamp3Cmd "Tells joystick 2 to switch on/off/blinking lamp 3.

00 - Off
01 - On
10 - Blinking
11 - Don't care / Take no action";
CM_ SG_ 2358902526 Joystick2Lamp2Cmd "Tells joystick 2 to switch on/off/blinking lamp 2.

00 - Off
01 - On
10 - Blinking
11 - Don't care / Take no action";
CM_ SG_ 2358902526 Joystick2Lamp1Cmd "Tells joystick 2 to switch on/off/blinking lamp 1.

00 - Off
01 - On
10 - Blinking
11 - Don't care / Take no action";
CM_ SG_ 2358902526 Joystick1Lamp10Cmd "Tells joystick 1 to switch on/off/blinking lamp 10.

00 - Off
01 - On
10 - Blinking
11 - Don't care / Take no action";
CM_ SG_ 2358902526 Joystick1Lamp9Cmd "Tells joystick 1 to switch on/off/blinking lamp 9.

00 - Off
01 - On
10 - Blinking
11 - Don't care / Take no action";
CM_ SG_ 2358902526 Joystick1Lamp8Cmd "Tells joystick 1 to switch on/off/blinking lamp 8.

00 - Off
01 - On
10 - Blinking
11 - Don't care / Take no action";
CM_ SG_ 2358902526 Joystick1Lamp7Cmd "Tells joystick 1 to switch on/off/blinking lamp 7.

00 - Off
01 - On
10 - Blinking
11 - Don't care / Take no action";
CM_ SG_ 2358902526 Joystick1Lamp6Cmd "Tells joystick 1 to switch on/off/blinking lamp 6.

00 - Off
01 - On
10 - Blinking
11 - Don't care / Take no action";
CM_ SG_ 2358902526 Joystick1Lamp5Cmd "Tells joystick 1 to switch on/off/blinking lamp 5.

00 - Off
01 - On
10 - Blinking
11 - Don't care / Take no action";
CM_ SG_ 2358902526 Joystick1Lamp4Cmd "Tells joystick 1 to switch on/off/blinking lamp 4.

00 - Off
01 - On
10 - Blinking
11 - Don't care / Take no action";
CM_ SG_ 2358902526 Joystick1Lamp3Cmd "Tells joystick 1 to switch on/off/blinking lamp 3.

00 - Off
01 - On
10 - Blinking
11 - Don't care / Take no action";
CM_ SG_ 2358902526 Joystick1Lamp2Cmd "Tells joystick 1 to switch on/off/blinking lamp 2.

00 - Off
01 - On
10 - Blinking
11 - Don't care / Take no action";
CM_ SG_ 2358902526 Joystick1Lamp1Cmd "Tells joystick 1 to switch on/off/blinking lamp 1.

00 - Off
01 - On
10 - Blinking
11 - Don't care / Take no action";
BA_DEF_ SG_  "SigType" ENUM  "Default","Range","RangeSigned","ASCII","Discrete","Control","ReferencePGN","DTC","StringDelimiter","StringLength","StringLengthControl","MessageCounter","MessageChecksum";
BA_DEF_ SG_  "GenSigStartValue" INT 0 10000;
BA_DEF_ SG_  "GenSigSendType" ENUM  "Cyclic","OnWrite","OnWriteWithRepetition","OnChange","OnChangeWithRepetition","IfActive","IfActiveWithRepetition","NoSigSendType";
BA_DEF_ SG_  "GenSigILSupport" ENUM  "No","Yes";
BA_DEF_ SG_  "GenSigEVName" STRING ;
BA_DEF_ SG_  "SPN" INT 0 524287;
BA_DEF_ BO_  "GenMsgStartDelayTime" INT 0 100000;
BA_DEF_ BO_  "GenMsgILSupport" ENUM  "No","Yes";
BA_DEF_ BO_  "GenMsgRequestable" INT 0 1;
BA_DEF_ BO_  "GenMsgSendType" ENUM  "cyclic","NotUsed","NotUsed","NotUsed","NotUsed","NotUsed","NotUsed","IfActive","noMsgSendType";
BA_DEF_ BO_  "VFrameFormat" ENUM  "StandardCAN","ExtendedCAN","reserved","J1939PG";
BA_DEF_ BO_  "GenMsgCycleTime" INT 0 3600000;
BA_DEF_ SG_  "SystemSignalLongSymbol" STRING ;
BA_DEF_DEF_  "SigType" "Default";
BA_DEF_DEF_  "GenSigStartValue" 0;
BA_DEF_DEF_  "GenSigSendType" "NoSigSendType";
BA_DEF_DEF_  "GenSigILSupport" "Yes";
BA_DEF_DEF_  "GenSigEVName" "Env@Nodename_@Signame";
BA_DEF_DEF_  "SPN" 0;
BA_DEF_DEF_  "GenMsgStartDelayTime" 0;
BA_DEF_DEF_  "GenMsgILSupport" "Yes";
BA_DEF_DEF_  "GenMsgRequestable" 1;
BA_DEF_DEF_  "GenMsgSendType" "noMsgSendType";
BA_DEF_DEF_  "VFrameFormat" "J1939PG";
BA_DEF_DEF_  "GenMsgCycleTime" 0;
BA_DEF_DEF_  "SystemSignalLongSymbol" "";
BA_ "GenMsgSendType" BO_ 2364553726 0;
BA_ "GenMsgCycleTime" BO_ 2364553726 20;
BA_ "GenMsgSendType" BO_ 2364553470 0;
BA_ "GenMsgCycleTime" BO_ 2364553470 20;
BA_ "GenMsgSendType" BO_ 2364553214 0;
BA_ "GenMsgCycleTime" BO_ 2364553214 100;
BA_ "GenMsgSendType" BO_ 2364546814 0;
BA_ "GenMsgCycleTime" BO_ 2364546814 20;
BA_ "GenMsgSendType" BO_ 2559049470 0;
BA_ "GenMsgCycleTime" BO_ 2559049470 1000;
BA_ "GenMsgSendType" BO_ 2349596414 0;
BA_ "GenMsgCycleTime" BO_ 2349596414 50;
BA_ "GenMsgSendType" BO_ 2558983934 0;
BA_ "GenMsgCycleTime" BO_ 2558983934 100;
BA_ "GenMsgSendType" BO_ 2349727486 0;
BA_ "GenMsgCycleTime" BO_ 2349727486 50;
BA_ "GenMsgSendType" BO_ 2550988542 0;
BA_ "GenMsgCycleTime" BO_ 2550988542 50;
BA_ "GenMsgSendType" BO_ 2566706686 0;
BA_ "GenMsgCycleTime" BO_ 2566706686 500;
BA_ "GenMsgSendType" BO_ 2566704126 0;
BA_ "GenMsgCycleTime" BO_ 2566704126 100;
BA_ "GenMsgSendType" BO_ 2566703870 0;
BA_ "GenMsgCycleTime" BO_ 2566703870 100;
BA_ "GenMsgSendType" BO_ 2566703614 0;
BA_ "GenMsgCycleTime" BO_ 2566703614 100;
BA_ "GenMsgSendType" BO_ 2566703358 0;
BA_ "GenMsgCycleTime" BO_ 2566703358 1000;
BA_ "GenMsgSendType" BO_ 2566702590 0;
BA_ "GenMsgCycleTime" BO_ 2566702590 500;
BA_ "GenMsgSendType" BO_ 2566702334 0;
BA_ "GenMsgCycleTime" BO_ 2566702334 500;
BA_ "GenMsgSendType" BO_ 2566702078 0;
BA_ "GenMsgCycleTime" BO_ 2566702078 200;
BA_ "GenMsgSendType" BO_ 2566701822 0;
BA_ "GenMsgCycleTime" BO_ 2566701822 1000;
BA_ "GenMsgSendType" BO_ 2431661310 0;
BA_ "GenMsgCycleTime" BO_ 2431661310 50;
BA_ "GenMsgSendType" BO_ 2431661054 0;
BA_ "GenMsgCycleTime" BO_ 2431661054 50;
BA_ "GenMsgSendType" BO_ 2230334206 0;
BA_ "GenMsgCycleTime" BO_ 2230334206 20;
BA_ "GenMsgSendType" BO_ 2230333950 0;
BA_ "GenMsgCycleTime" BO_ 2230333950 20;
BA_ "GenMsgSendType" BO_ 2364551422 0;
BA_ "GenMsgCycleTime" BO_ 2364551422 50;
BA_ "GenMsgSendType" BO_ 2364551166 0;
BA_ "GenMsgCycleTime" BO_ 2364551166 50;
BA_ "GenMsgSendType" BO_ 2566730238 0;
BA_ "GenMsgCycleTime" BO_ 2566730238 1000;
BA_ "GenMsgSendType" BO_ 2566711038 0;
BA_ "GenMsgCycleTime" BO_ 2566711038 500;
BA_ "GenMsgSendType" BO_ 2566710782 0;
BA_ "GenMsgCycleTime" BO_ 2566710782 30000;
BA_ "GenMsgSendType" BO_ 2566710526 0;
BA_ "GenMsgCycleTime" BO_ 2566710526 30000;
BA_ "GenMsgSendType" BO_ 2432492542 0;
BA_ "GenMsgCycleTime" BO_ 2432492542 100;
BA_ "GenMsgSendType" BO_ 2566710014 0;
BA_ "GenMsgCycleTime" BO_ 2566710014 1000;
BA_ "GenMsgSendType" BO_ 2566709758 0;
BA_ "GenMsgCycleTime" BO_ 2566709758 100;
BA_ "GenMsgSendType" BO_ 2566709502 0;
BA_ "GenMsgCycleTime" BO_ 2566709502 100;
BA_ "GenMsgSendType" BO_ 2566709246 0;
BA_ "GenMsgCycleTime" BO_ 2566709246 500;
BA_ "GenMsgSendType" BO_ 2566708990 0;
BA_ "GenMsgCycleTime" BO_ 2566708990 500;
BA_ "GenMsgSendType" BO_ 2566708734 0;
BA_ "GenMsgCycleTime" BO_ 2566708734 500;
BA_ "GenMsgSendType" BO_ 2566708478 0;
BA_ "GenMsgCycleTime" BO_ 2566708478 1000;
BA_ "GenMsgSendType" BO_ 2566708222 0;
BA_ "GenMsgCycleTime" BO_ 2566708222 1000;
BA_ "GenMsgSendType" BO_ 2566707966 0;
BA_ "GenMsgCycleTime" BO_ 2566707966 1000;
BA_ "GenMsgSendType" BO_ 2566707710 0;
BA_ "GenMsgCycleTime" BO_ 2566707710 1000;
BA_ "GenMsgSendType" BO_ 2297441790 0;
BA_ "GenMsgCycleTime" BO_ 2297441790 10;
BA_ "GenMsgSendType" BO_ 2364549630 0;
BA_ "GenMsgCycleTime" BO_ 2364549630 10;
BA_ "GenMsgSendType" BO_ 2499614462 0;
BA_ "GenMsgCycleTime" BO_ 2499614462 5000;
BA_ "GenMsgSendType" BO_ 2560098046 0;
BA_ "GenMsgCycleTime" BO_ 2560098046 10000;
BA_ "GenMsgSendType" BO_ 2560163582 0;
BA_ "GenMsgCycleTime" BO_ 2560163582 10000;
BA_ "GenMsgSendType" BO_ 2297441534 0;
BA_ "GenMsgCycleTime" BO_ 2297441534 50;
BA_ "GenMsgSendType" BO_ 2566722302 0;
BA_ "GenMsgCycleTime" BO_ 2566722302 500;
BA_ "GenMsgSendType" BO_ 2560032510 0;
BA_ "GenMsgCycleTime" BO_ 2560032510 500;
BA_ "GenMsgSendType" BO_ 2566717950 0;
BA_ "GenMsgCycleTime" BO_ 2566717950 500;
BA_ "GenMsgSendType" BO_ 2499604222 0;
BA_ "GenMsgCycleTime" BO_ 2499604222 200;
BA_ "GenMsgSendType" BO_ 2358902526 0;
BA_ "GenMsgCycleTime" BO_ 2358902526 100;
BA_ "SPN" SG_ 2364556030 EngCyl9PressSensorPreliminaryFMI 6431;
BA_ "SigType" SG_ 2364556030 EngCyl9SynchronousKnockLevel 1;
BA_ "SPN" SG_ 2364556030 EngCyl9SynchronousKnockLevel 6430;
BA_ "SigType" SG_ 2364556030 EngCyl9PeakPress 1;
BA_ "SPN" SG_ 2364556030 EngCyl9PeakPress 6429;
BA_ "SigType" SG_ 2364556030 EngCyl9HeatRelease 1;
BA_ "SPN" SG_ 2364556030 EngCyl9HeatRelease 6428;
BA_ "SPN" SG_ 2364555774 EngCyl8PressSensorPreliminaryFMI 6427;
BA_ "SigType" SG_ 2364555774 EngCyl8SynchronousKnockLevel 1;
BA_ "SPN" SG_ 2364555774 EngCyl8SynchronousKnockLevel 6426;
BA_ "SigType" SG_ 2364555774 EngCyl8PeakPress 1;
BA_ "SPN" SG_ 2364555774 EngCyl8PeakPress 6425;
BA_ "SigType" SG_ 2364555774 EngCyl8HeatRelease 1;
BA_ "SPN" SG_ 2364555774 EngCyl8HeatRelease 6424;
BA_ "SPN" SG_ 2364555518 EngCyl7PressSensorPreliminaryFMI 6423;
BA_ "SigType" SG_ 2364555518 EngCyl7SynchronousKnockLevel 1;
BA_ "SPN" SG_ 2364555518 EngCyl7SynchronousKnockLevel 6422;
BA_ "SigType" SG_ 2364555518 EngCyl7PeakPress 1;
BA_ "SPN" SG_ 2364555518 EngCyl7PeakPress 6421;
BA_ "SigType" SG_ 2364555518 EngCyl7HeatRelease 1;
BA_ "SPN" SG_ 2364555518 EngCyl7HeatRelease 6420;
BA_ "SPN" SG_ 2364555262 EngCyl6PressSensorPreliminaryFMI 6419;
BA_ "SigType" SG_ 2364555262 EngCyl6SynchronousKnockLevel 1;
BA_ "SPN" SG_ 2364555262 EngCyl6SynchronousKnockLevel 6418;
BA_ "SigType" SG_ 2364555262 EngCyl6PeakPress 1;
BA_ "SPN" SG_ 2364555262 EngCyl6PeakPress 6417;
BA_ "SigType" SG_ 2364555262 EngCyl6HeatRelease 1;
BA_ "SPN" SG_ 2364555262 EngCyl6HeatRelease 6416;
BA_ "SPN" SG_ 2364555006 EngCyl5PressSensorPreliminaryFMI 6415;
BA_ "SigType" SG_ 2364555006 EngCyl5SynchronousKnockLevel 1;
BA_ "SPN" SG_ 2364555006 EngCyl5SynchronousKnockLevel 6414;
BA_ "SigType" SG_ 2364555006 EngCyl5PeakPress 1;
BA_ "SPN" SG_ 2364555006 EngCyl5PeakPress 6413;
BA_ "SigType" SG_ 2364555006 EngCyl5HeatRelease 1;
BA_ "SPN" SG_ 2364555006 EngCyl5HeatRelease 6412;
BA_ "SPN" SG_ 2364554750 EngCyl4PressSensorPreliminaryFMI 6411;
BA_ "SigType" SG_ 2364554750 EngCyl4SynchronousKnockLevel 1;
BA_ "SPN" SG_ 2364554750 EngCyl4SynchronousKnockLevel 6410;
BA_ "SigType" SG_ 2364554750 EngCyl4PeakPress 1;
BA_ "SPN" SG_ 2364554750 EngCyl4PeakPress 6409;
BA_ "SigType" SG_ 2364554750 EngCyl4HeatRelease 1;
BA_ "SPN" SG_ 2364554750 EngCyl4HeatRelease 6408;
BA_ "SPN" SG_ 2364554494 EngCyl3PressSensorPreliminaryFMI 6407;
BA_ "SigType" SG_ 2364554494 EngCyl3SynchronousKnockLevel 1;
BA_ "SPN" SG_ 2364554494 EngCyl3SynchronousKnockLevel 6406;
BA_ "SigType" SG_ 2364554494 EngCyl3PeakPress 1;
BA_ "SPN" SG_ 2364554494 EngCyl3PeakPress 6405;
BA_ "SigType" SG_ 2364554494 EngCyl3HeatRelease 1;
BA_ "SPN" SG_ 2364554494 EngCyl3HeatRelease 6404;
BA_ "SPN" SG_ 2364554238 EngCyl2PressSensorPreliminaryFMI 6403;
BA_ "SigType" SG_ 2364554238 EngCyl2SynchronousKnockLevel 1;
BA_ "SPN" SG_ 2364554238 EngCyl2SynchronousKnockLevel 6402;
BA_ "SigType" SG_ 2364554238 EngCyl2PeakPress 1;
BA_ "SPN" SG_ 2364554238 EngCyl2PeakPress 6401;
BA_ "SigType" SG_ 2364554238 EngCyl2HeatRelease 1;
BA_ "SPN" SG_ 2364554238 EngCyl2HeatRelease 6400;
BA_ "SPN" SG_ 2364553982 EngCyl1PressSensorPreliminaryFMI 6399;
BA_ "SigType" SG_ 2364553982 EngCyl1SynchronousKnockLevel 1;
BA_ "SPN" SG_ 2364553982 EngCyl1SynchronousKnockLevel 6398;
BA_ "SigType" SG_ 2364553982 EngCyl1PeakPress 1;
BA_ "SPN" SG_ 2364553982 EngCyl1PeakPress 6397;
BA_ "SigType" SG_ 2364553982 EngCyl1HeatRelease 1;
BA_ "SPN" SG_ 2364553982 EngCyl1HeatRelease 6396;
BA_ "SigType" SG_ 2364553726 EngTotalIntakeMassAirFlowRate 1;
BA_ "SPN" SG_ 2364553726 EngTotalIntakeMassAirFlowRate 6393;
BA_ "SigType" SG_ 2364553726 EngDesiredAirFuelRatio 1;
BA_ "SPN" SG_ 2364553726 EngDesiredAirFuelRatio 6392;
BA_ "SigType" SG_ 2364553470 EngCylTorque 1;
BA_ "SPN" SG_ 2364553470 EngCylTorque 6389;
BA_ "SigType" SG_ 2364553470 EngCylDieselMassFlowRateCmd 1;
BA_ "SPN" SG_ 2364553470 EngCylDieselMassFlowRateCmd 6388;
BA_ "SigType" SG_ 2364553470 EngCylGasMassFlowRateCmd 1;
BA_ "SPN" SG_ 2364553470 EngCylGasMassFlowRateCmd 6387;
BA_ "SigType" SG_ 2364553470 EngGasFuelPercentageCmd 1;
BA_ "SPN" SG_ 2364553470 EngGasFuelPercentageCmd 6386;
BA_ "SPN" SG_ 2364553214 EngTrbCmprssrBlwffActtr1OprtnStt 6316;
BA_ "SigType" SG_ 2364553214 EngTrbCmprssrBlowoffActuator1Pos 1;
BA_ "SPN" SG_ 2364553214 EngTrbCmprssrBlowoffActuator1Pos 6315;
BA_ "SigType" SG_ 2364553214 EngTrbCmprssrBlwffActtr1DsredPos 1;
BA_ "SPN" SG_ 2364553214 EngTrbCmprssrBlwffActtr1DsredPos 6314;
BA_ "SigType" SG_ 2364553214 EngTrbCmprssrBlwoffActuator1Temp 1;
BA_ "SPN" SG_ 2364553214 EngTrbCmprssrBlwoffActuator1Temp 6313;
BA_ "SPN" SG_ 2364553214 EngTrbCmprssrBlwffActtr1TmpSttus 6312;
BA_ "SPN" SG_ 2364553214 EngTrbCmprssrBlwffActtr1PrlmnryF 6311;
BA_ "SPN" SG_ 2364547838 PersistentLimitStatus 4307;
BA_ "SPN" SG_ 2364547838 MachineSelectedSpeedSource 4308;
BA_ "SigType" SG_ 2364547838 MachineSelectedDirection 4;
BA_ "SPN" SG_ 2364547838 MachineSelectedDirection 4309;
BA_ "SPN" SG_ 2364547838 MachineSelectedDistance 4306;
BA_ "SPN" SG_ 2364547838 MachineSelectedSpeed 4305;
BA_ "SigType" SG_ 2364546814 GeneratorGoverningBias 1;
BA_ "SPN" SG_ 2364546814 GeneratorGoverningBias 3938;
BA_ "SPN" SG_ 2364538369 ManufacturerSpecificInformation 3328;
BA_ "SigType" SG_ 2566767614 AccelPedal2Channel3 1;
BA_ "SPN" SG_ 2566767614 AccelPedal2Channel3 2626;
BA_ "SigType" SG_ 2566767614 AccelPedal2Channel2 1;
BA_ "SPN" SG_ 2566767614 AccelPedal2Channel2 2625;
BA_ "SigType" SG_ 2566767614 AccelPedal1Channel3 1;
BA_ "SPN" SG_ 2566767614 AccelPedal1Channel3 2624;
BA_ "SigType" SG_ 2566767614 AccelPedal1Channel2 1;
BA_ "SPN" SG_ 2566767614 AccelPedal1Channel2 2623;
BA_ "SigType" SG_ 2559049470 DesiredEngFuelingState 5;
BA_ "SPN" SG_ 2559049470 DesiredEngFuelingState 5793;
BA_ "SPN" SG_ 2559049470 RequestedFuelType 6317;
BA_ "SPN" SG_ 2349596414 AEBS2MessageChecksum 5683;
BA_ "SPN" SG_ 2349596414 AEBS2MessageCounter 5682;
BA_ "SigType" SG_ 2349596414 DrvrActvtnDmndFrAdvncdEmrgncyBrk 5;
BA_ "SPN" SG_ 2349596414 DrvrActvtnDmndFrAdvncdEmrgncyBrk 5681;
BA_ "SPN" SG_ 2362244862 DataDictionaryRow 2427;
BA_ "SPN" SG_ 2362244862 DataDictionaryColumn 2428;
BA_ "SPN" SG_ 2362244862 ImplementType 2425;
BA_ "SPN" SG_ 2362244862 ImplementPos 2426;
BA_ "SigType" SG_ 2362244862 DataFormat_ErrorCondition 4;
BA_ "SPN" SG_ 2362244862 DataFormat_ErrorCondition 2419;
BA_ "SigType" SG_ 2362244862 ProcessDataType 4;
BA_ "SPN" SG_ 2362244862 ProcessDataType 2420;
BA_ "SPN" SG_ 2362244862 ProcessDataModifier 2421;
BA_ "SPN" SG_ 2362244862 RepetitionRateParameter 2418;
BA_ "SPN" SG_ 2362179326 ProcessVariableValue 2429;
BA_ "SPN" SG_ 2362179326 DataDictionaryRow 2427;
BA_ "SPN" SG_ 2362179326 DataDictionaryColumn 2428;
BA_ "SPN" SG_ 2362179326 ImplementType 2425;
BA_ "SPN" SG_ 2362179326 ImplementPos 2426;
BA_ "SPN" SG_ 2362179326 CountNumber 2422;
BA_ "SigType" SG_ 2362179326 DataFormat_ErrorCondition 4;
BA_ "SPN" SG_ 2362179326 DataFormat_ErrorCondition 2419;
BA_ "SigType" SG_ 2362179326 ProcessDataType 4;
BA_ "SPN" SG_ 2362179326 ProcessDataType 2420;
BA_ "SPN" SG_ 2362179326 ProcessDataModifier 2421;
BA_ "SigType" SG_ 2361851646 ValveFailSafeMode 4;
BA_ "SPN" SG_ 2361851646 ValveFailSafeMode 2934;
BA_ "SPN" SG_ 2361851646 ValveState 2932;
BA_ "SPN" SG_ 2361851646 RetractPortEstFlow 2940;
BA_ "SPN" SG_ 2361851646 ExtendPortEstFlow 2939;
BA_ "SPN" SG_ 2361786110 ReturnPortPress 2943;
BA_ "SPN" SG_ 2361786110 RetractPortPress 2942;
BA_ "SPN" SG_ 2361786110 ExtendPortPress 2941;
BA_ "SPN" SG_ 2361786110 RetractPortMeasuredFlow 2938;
BA_ "SPN" SG_ 2361786110 ExtendPortMeasuredFlow 2937;
BA_ "SPN" SG_ 2361720574 PortFlowCmd 2944;
BA_ "SystemSignalLongSymbol" SG_ 2358509310 VehicleSystemInstanceQualifierFl "VehicleSystemInstanceQualifierFlag";
BA_ "SystemSignalLongSymbol" SG_ 2358509310 ArbitraryAddressCapableQualifier "ArbitraryAddressCapableQualifierFlag";
BA_ "SigType" SG_ 2558983934 SwitchedPowerOutput18Cmd 5;
BA_ "SPN" SG_ 2558983934 SwitchedPowerOutput18Cmd 6002;
BA_ "SigType" SG_ 2558983934 SwitchedPowerOutput19Cmd 5;
BA_ "SPN" SG_ 2558983934 SwitchedPowerOutput19Cmd 6001;
BA_ "SigType" SG_ 2558983934 SwitchedPowerOutput20Cmd 5;
BA_ "SPN" SG_ 2558983934 SwitchedPowerOutput20Cmd 6000;
BA_ "SigType" SG_ 2558983934 SwitchedPowerOutput13Cmd 5;
BA_ "SPN" SG_ 2558983934 SwitchedPowerOutput13Cmd 5999;
BA_ "SigType" SG_ 2558983934 SwitchedPowerOutput14Cmd 5;
BA_ "SPN" SG_ 2558983934 SwitchedPowerOutput14Cmd 5998;
BA_ "SigType" SG_ 2558983934 SwitchedPowerOutput15Cmd 5;
BA_ "SPN" SG_ 2558983934 SwitchedPowerOutput15Cmd 5997;
BA_ "SigType" SG_ 2558983934 SwitchedPowerOutput16Cmd 5;
BA_ "SPN" SG_ 2558983934 SwitchedPowerOutput16Cmd 5996;
BA_ "SigType" SG_ 2558983934 SwitchedPowerOutput9Cmd 5;
BA_ "SPN" SG_ 2558983934 SwitchedPowerOutput9Cmd 5995;
BA_ "SigType" SG_ 2558983934 SwitchedPowerOutput10Cmd 5;
BA_ "SPN" SG_ 2558983934 SwitchedPowerOutput10Cmd 5994;
BA_ "SigType" SG_ 2558983934 SwitchedPowerOutput29Cmd 5;
BA_ "SPN" SG_ 2558983934 SwitchedPowerOutput29Cmd 6015;
BA_ "SigType" SG_ 2558983934 SwitchedPowerOutput30Cmd 5;
BA_ "SPN" SG_ 2558983934 SwitchedPowerOutput30Cmd 6014;
BA_ "SigType" SG_ 2558983934 SwitchedPowerOutput31Cmd 5;
BA_ "SPN" SG_ 2558983934 SwitchedPowerOutput31Cmd 6013;
BA_ "SigType" SG_ 2558983934 SwitchedPowerOutput32Cmd 5;
BA_ "SPN" SG_ 2558983934 SwitchedPowerOutput32Cmd 6012;
BA_ "SigType" SG_ 2558983934 SwitchedPowerOutput25Cmd 5;
BA_ "SPN" SG_ 2558983934 SwitchedPowerOutput25Cmd 6011;
BA_ "SigType" SG_ 2558983934 SwitchedPowerOutput26Cmd 5;
BA_ "SPN" SG_ 2558983934 SwitchedPowerOutput26Cmd 6010;
BA_ "SigType" SG_ 2558983934 SwitchedPowerOutput27Cmd 5;
BA_ "SPN" SG_ 2558983934 SwitchedPowerOutput27Cmd 6009;
BA_ "SigType" SG_ 2558983934 SwitchedPowerOutput28Cmd 5;
BA_ "SPN" SG_ 2558983934 SwitchedPowerOutput28Cmd 6008;
BA_ "SigType" SG_ 2558983934 SwitchedPowerOutput21Cmd 5;
BA_ "SPN" SG_ 2558983934 SwitchedPowerOutput21Cmd 6007;
BA_ "SigType" SG_ 2558983934 SwitchedPowerOutput22Cmd 5;
BA_ "SPN" SG_ 2558983934 SwitchedPowerOutput22Cmd 6006;
BA_ "SigType" SG_ 2558983934 SwitchedPowerOutput23Cmd 5;
BA_ "SPN" SG_ 2558983934 SwitchedPowerOutput23Cmd 6005;
BA_ "SigType" SG_ 2558983934 SwitchedPowerOutput24Cmd 5;
BA_ "SPN" SG_ 2558983934 SwitchedPowerOutput24Cmd 6004;
BA_ "SigType" SG_ 2558983934 SwitchedPowerOutput17Cmd 5;
BA_ "SPN" SG_ 2558983934 SwitchedPowerOutput17Cmd 6003;
BA_ "SigType" SG_ 2558983934 SwitchedPowerOutput11Cmd 5;
BA_ "SPN" SG_ 2558983934 SwitchedPowerOutput11Cmd 5993;
BA_ "SigType" SG_ 2558983934 SwitchedPowerOutput12Cmd 5;
BA_ "SPN" SG_ 2558983934 SwitchedPowerOutput12Cmd 5992;
BA_ "SigType" SG_ 2558983934 SwitchedPowerOutput5Cmd 5;
BA_ "SPN" SG_ 2558983934 SwitchedPowerOutput5Cmd 5991;
BA_ "SigType" SG_ 2558983934 SwitchedPowerOutput6Cmd 5;
BA_ "SPN" SG_ 2558983934 SwitchedPowerOutput6Cmd 5990;
BA_ "SigType" SG_ 2558983934 SwitchedPowerOutput7Cmd 5;
BA_ "SPN" SG_ 2558983934 SwitchedPowerOutput7Cmd 5989;
BA_ "SigType" SG_ 2558983934 SwitchedPowerOutput8Cmd 5;
BA_ "SPN" SG_ 2558983934 SwitchedPowerOutput8Cmd 5988;
BA_ "SigType" SG_ 2558983934 SwitchedPowerOutput1Cmd 5;
BA_ "SPN" SG_ 2558983934 SwitchedPowerOutput1Cmd 5987;
BA_ "SigType" SG_ 2558983934 SwitchedPowerOutput2Cmd 5;
BA_ "SPN" SG_ 2558983934 SwitchedPowerOutput2Cmd 5986;
BA_ "SigType" SG_ 2558983934 SwitchedPowerOutput3Cmd 5;
BA_ "SPN" SG_ 2558983934 SwitchedPowerOutput3Cmd 5985;
BA_ "SigType" SG_ 2558983934 SwitchedPowerOutput4Cmd 5;
BA_ "SPN" SG_ 2558983934 SwitchedPowerOutput4Cmd 5984;
BA_ "SigType" SG_ 2349727486 TransMode10 5;
BA_ "SPN" SG_ 2349727486 TransMode10 6570;
BA_ "SigType" SG_ 2349727486 TransMode9 5;
BA_ "SPN" SG_ 2349727486 TransMode9 6569;
BA_ "SigType" SG_ 2550988542 AccelPedalPos3 1;
BA_ "SPN" SG_ 2550988542 AccelPedalPos3 28;
BA_ "SPN" SG_ 2566767358 FuelType 5837;
BA_ "SigType" SG_ 2566767358 EngFuelMassFlowRate 1;
BA_ "SPN" SG_ 2566767358 EngFuelMassFlowRate 5833;
BA_ "SigType" SG_ 2566767358 EngExhstGsRcrcltn1Valve2PosError 1;
BA_ "SPN" SG_ 2566767358 EngExhstGsRcrcltn1Valve2PosError 5830;
BA_ "SigType" SG_ 2566767358 EngExhstGsRcrcltn1Valve1PosError 1;
BA_ "SPN" SG_ 2566767358 EngExhstGsRcrcltn1Valve1PosError 5829;
BA_ "SigType" SG_ 2566706686 Aftrtrtmnt1DslExhstFldPumpHeater 1;
BA_ "SPN" SG_ 2566706686 Aftrtrtmnt1DslExhstFldPumpHeater 5706;
BA_ "SigType" SG_ 2566705406 Aftertreatment2ParticulateSensor 1;
BA_ "SPN" SG_ 2566705406 Aftertreatment2ParticulateSensor 5836;
BA_ "SigType" SG_ 2566705406 Aftertreatment1ParticulateSensor 1;
BA_ "SPN" SG_ 2566705406 Aftertreatment1ParticulateSensor 5835;
BA_ "SPN" SG_ 2566705150 NOxSnsorATI2SelfdiagnosisTrigger 5712;
BA_ "SPN" SG_ 2566705150 NOxSnsorATO2SelfdiagnosisTrigger 5711;
BA_ "SPN" SG_ 2566705150 NOxSnsorATI1SelfdiagnosisTrigger 5710;
BA_ "SPN" SG_ 2566705150 NOxSnsorATO1SelfdiagnosisTrigger 5709;
BA_ "SigType" SG_ 2566704382 Aftrtrtmnt2OtltGsSnsrPowerSupply 5;
BA_ "SPN" SG_ 2566704382 Aftrtrtmnt2OtltGsSnsrPowerSupply 5761;
BA_ "SigType" SG_ 2566704382 Aftrtrtmnt2IntkGsSnsrPowerSupply 5;
BA_ "SPN" SG_ 2566704382 Aftrtrtmnt2IntkGsSnsrPowerSupply 5760;
BA_ "SigType" SG_ 2566704382 Aftrtrtmnt1OtltGsSnsrPowerSupply 5;
BA_ "SPN" SG_ 2566704382 Aftrtrtmnt1OtltGsSnsrPowerSupply 5759;
BA_ "SigType" SG_ 2566704382 Aftrtrtmnt1IntkGsSnsrPowerSupply 5;
BA_ "SPN" SG_ 2566704382 Aftrtrtmnt1IntkGsSnsrPowerSupply 5758;
BA_ "SPN" SG_ 2566704126 EngExhstGsRcrcltn1Acttr2PrlmnryF 5767;
BA_ "SPN" SG_ 2566704126 EngExhstGsRcrcltn1Acttr2OprtnStt 5772;
BA_ "SPN" SG_ 2566704126 EngExhstGsRcrcltn1Acttr1OprtnStt 5771;
BA_ "SigType" SG_ 2566704126 EngExhstGsRcrcltn1Acttr2DsredPos 1;
BA_ "SPN" SG_ 2566704126 EngExhstGsRcrcltn1Acttr2DsredPos 5770;
BA_ "SigType" SG_ 2566704126 EngExhstGsRcrclton1Actuator2Temp 1;
BA_ "SPN" SG_ 2566704126 EngExhstGsRcrclton1Actuator2Temp 5769;
BA_ "SPN" SG_ 2566704126 EngExhstGsRcrcltn1Acttr2TmpSttus 5768;
BA_ "SigType" SG_ 2566704126 EngExhstGsRcrcltn1Acttr1DsredPos 1;
BA_ "SPN" SG_ 2566704126 EngExhstGsRcrcltn1Acttr1DsredPos 5766;
BA_ "SigType" SG_ 2566704126 EngExhstGsRcrclton1Actuator1Temp 1;
BA_ "SPN" SG_ 2566704126 EngExhstGsRcrclton1Actuator1Temp 5765;
BA_ "SPN" SG_ 2566704126 EngExhstGsRcrcltn1Acttr1TmpSttus 5764;
BA_ "SPN" SG_ 2566704126 EngExhstGsRcrcltn1Acttr1PrlmnryF 5763;
BA_ "SPN" SG_ 2566703870 EngExhstGsRcrcltn2Acttr2OprtnStt 5782;
BA_ "SPN" SG_ 2566703870 EngExhstGsRcrcltn2Acttr1OprtnStt 5781;
BA_ "SigType" SG_ 2566703870 EngExhstGsRcrcltn2Acttr2DsredPos 1;
BA_ "SPN" SG_ 2566703870 EngExhstGsRcrcltn2Acttr2DsredPos 5780;
BA_ "SigType" SG_ 2566703870 EngExhstGsRcrclton2Actuator2Temp 1;
BA_ "SPN" SG_ 2566703870 EngExhstGsRcrclton2Actuator2Temp 5779;
BA_ "SPN" SG_ 2566703870 EngExhstGsRcrcltn2Acttr2TmpSttus 5778;
BA_ "SPN" SG_ 2566703870 EngExhstGsRcrcltn2Acttr2PrlmnryF 5777;
BA_ "SigType" SG_ 2566703870 EngExhstGsRcrcltn2Acttr1DsredPos 1;
BA_ "SPN" SG_ 2566703870 EngExhstGsRcrcltn2Acttr1DsredPos 5776;
BA_ "SigType" SG_ 2566703870 EngExhstGsRcrclton2Actuator1Temp 1;
BA_ "SPN" SG_ 2566703870 EngExhstGsRcrclton2Actuator1Temp 5775;
BA_ "SPN" SG_ 2566703870 EngExhstGsRcrcltn2Acttr1TmpSttus 5774;
BA_ "SPN" SG_ 2566703870 EngExhstGsRcrcltn2Acttr1PrlmnryF 5773;
BA_ "SigType" SG_ 2566703614 EngTurboWastegateActuator2Temp 1;
BA_ "SPN" SG_ 2566703614 EngTurboWastegateActuator2Temp 5787;
BA_ "SigType" SG_ 2566703614 EngFuelValve2Temp 1;
BA_ "SPN" SG_ 2566703614 EngFuelValve2Temp 5786;
BA_ "SigType" SG_ 2566703614 EngFuelValve1Temp 1;
BA_ "SPN" SG_ 2566703614 EngFuelValve1Temp 5785;
BA_ "SigType" SG_ 2566703614 EngThrottleValve2Temp 1;
BA_ "SPN" SG_ 2566703614 EngThrottleValve2Temp 5784;
BA_ "SigType" SG_ 2566703614 EngThrottleValve1Temp 1;
BA_ "SPN" SG_ 2566703614 EngThrottleValve1Temp 5783;
BA_ "SPN" SG_ 2566703358 SrcAddrssOfCntrllngDvcFrFlngStte 6307;
BA_ "SPN" SG_ 2566703358 EngFuelingInhibitPreventedReason 5866;
BA_ "SigType" SG_ 2566703358 EngFuelingInhibitAllowed 5;
BA_ "SPN" SG_ 2566703358 EngFuelingInhibitAllowed 5795;
BA_ "SigType" SG_ 2566703358 FeedbackEngFuelingState 5;
BA_ "SPN" SG_ 2566703358 FeedbackEngFuelingState 5794;
BA_ "SPN" SG_ 2566702590 Aftrtrtmnt1SCRIntrmdtGsTmpPrlmnr 5863;
BA_ "SigType" SG_ 2566702590 Aftrtrtmnt1SCRIntrmediateGasTemp 1;
BA_ "SPN" SG_ 2566702590 Aftrtrtmnt1SCRIntrmediateGasTemp 5862;
BA_ "SPN" SG_ 2566702334 Aftrtrtmnt2SCRIntrmdtGsTmpPrlmnr 5865;
BA_ "SigType" SG_ 2566702334 Aftrtrtmnt2SCRIntrmediateGasTemp 1;
BA_ "SPN" SG_ 2566702334 Aftrtrtmnt2SCRIntrmediateGasTemp 5864;
BA_ "SigType" SG_ 2566702078 SupplyGasMethanePercentage 1;
BA_ "SPN" SG_ 2566702078 SupplyGasMethanePercentage 5867;
BA_ "SigType" SG_ 2566701822 HybridSystemStopIndicator 5;
BA_ "SPN" SG_ 2566701822 HybridSystemStopIndicator 5874;
BA_ "SigType" SG_ 2566701822 HybridSystemOverheatIndicator 5;
BA_ "SPN" SG_ 2566701822 HybridSystemOverheatIndicator 5873;
BA_ "SigType" SG_ 2566701822 HybridSystemWarningIndicator 5;
BA_ "SPN" SG_ 2566701822 HybridSystemWarningIndicator 5872;
BA_ "SigType" SG_ 2431661310 Aftrtrtmnt2SCRIntrmdtNH3GsSn5861 5;
BA_ "SPN" SG_ 2431661310 Aftrtrtmnt2SCRIntrmdtNH3GsSn5861 5861;
BA_ "SPN" SG_ 2431661310 Aftrtrtmnt2SCRIntrmdtNH3GsSnsrHt 5860;
BA_ "SPN" SG_ 2431661310 Aftrtrtmnt2SCRIntrmdtNH3GsSnsrAt 5859;
BA_ "SigType" SG_ 2431661310 Aftrtrtmnt2SCRIntrmdtNH3GsSnsrPw 5;
BA_ "SPN" SG_ 2431661310 Aftrtrtmnt2SCRIntrmdtNH3GsSnsrPw 5858;
BA_ "SigType" SG_ 2431661310 Aftrtrtmnt2SCRIntrmdtNH3RdngStbl 5;
BA_ "SPN" SG_ 2431661310 Aftrtrtmnt2SCRIntrmdtNH3RdngStbl 5857;
BA_ "SPN" SG_ 2431661310 Aftrtrtmnt2SCRIntrmdtNH3SnsrPrlm 5856;
BA_ "SigType" SG_ 2431661310 Aftrtreatment2SCRIntermediateNH3 1;
BA_ "SPN" SG_ 2431661310 Aftrtreatment2SCRIntermediateNH3 5855;
BA_ "SigType" SG_ 2431661054 Aftrtrtmnt1SCRIntrmdtNH3GsSn5854 5;
BA_ "SPN" SG_ 2431661054 Aftrtrtmnt1SCRIntrmdtNH3GsSn5854 5854;
BA_ "SPN" SG_ 2431661054 Aftrtrtmnt1SCRIntrmdtNH3GsSnsrHt 5853;
BA_ "SigType" SG_ 2431661054 Aftrtrtmnt1SCRIntrmdtNH3GsSnsrAt 5;
BA_ "SPN" SG_ 2431661054 Aftrtrtmnt1SCRIntrmdtNH3GsSnsrAt 5852;
BA_ "SigType" SG_ 2431661054 Aftrtrtmnt1SCRIntrmdtNH3GsSnsrPw 5;
BA_ "SPN" SG_ 2431661054 Aftrtrtmnt1SCRIntrmdtNH3GsSnsrPw 5851;
BA_ "SigType" SG_ 2431661054 Aftrtrtmnt1SCRIntrmdtNH3RdngStbl 5;
BA_ "SPN" SG_ 2431661054 Aftrtrtmnt1SCRIntrmdtNH3RdngStbl 5850;
BA_ "SPN" SG_ 2431661054 Aftrtrtmnt1SCRIntrmdtNH3SnsrPrlm 5849;
BA_ "SigType" SG_ 2431661054 Aftrtreatment1SCRIntermediateNH3 1;
BA_ "SPN" SG_ 2431661054 Aftrtreatment1SCRIntermediateNH3 5848;
BA_ "SigType" SG_ 2230334206 LnrDsplcmntSnsrSnsrFigureOfMerit 5;
BA_ "SPN" SG_ 2230334206 LnrDsplcmntSnsrSnsrFigureOfMerit 5824;
BA_ "SigType" SG_ 2230334206 MeasuredLinearDisplacement 1;
BA_ "SPN" SG_ 2230334206 MeasuredLinearDisplacement 5823;
BA_ "SigType" SG_ 2230333950 WandSensorFigureOfMerit 5;
BA_ "SPN" SG_ 2230333950 WandSensorFigureOfMerit 5822;
BA_ "SigType" SG_ 2230333950 WandAngle 1;
BA_ "SPN" SG_ 2230333950 WandAngle 5821;
BA_ "SigType" SG_ 2364551422 WirelessSignalStrength1 1;
BA_ "SPN" SG_ 2364551422 WirelessSignalStrength1 5753;
BA_ "SPN" SG_ 2364551422 TransmitterID1 5752;
BA_ "SPN" SG_ 2364551422 TransmitterCmdState 5751;
BA_ "SigType" SG_ 2364551422 WirelessRollingMessageCounter 1;
BA_ "SPN" SG_ 2364551422 WirelessRollingMessageCounter 5750;
BA_ "SigType" SG_ 2364551166 TmeToCollisionWithRelevantObject 1;
BA_ "SPN" SG_ 2364551166 TmeToCollisionWithRelevantObject 5680;
BA_ "SPN" SG_ 2364551166 BndOffPrbabilityOfRelevantObject 5679;
BA_ "SPN" SG_ 2364551166 RlvntObjctDtctdFrAdvncdEmrgncyBr 5678;
BA_ "SPN" SG_ 2364551166 CollisionWarningLevel 5677;
BA_ "SPN" SG_ 2364551166 AdvncdEmrgencyBrakingSystemState 5676;
BA_ "SigType" SG_ 2566730238 Fan2DriveBypassCmdStatus 1;
BA_ "SPN" SG_ 2566730238 Fan2DriveBypassCmdStatus 1708;
BA_ "SigType" SG_ 2566730238 HydFan2MotorPress 1;
BA_ "SPN" SG_ 2566730238 HydFan2MotorPress 1707;
BA_ "SigType" SG_ 2566730238 Fan2Speed 1;
BA_ "SPN" SG_ 2566730238 Fan2Speed 1598;
BA_ "SPN" SG_ 2566730238 Fan2DriveState 1557;
BA_ "SigType" SG_ 2566730238 EstPercentFan2Speed 1;
BA_ "SPN" SG_ 2566730238 EstPercentFan2Speed 1550;
BA_ "SigType" SG_ 2566711038 LubricationTimingCycleStatus 5;
BA_ "SPN" SG_ 2566711038 LubricationTimingCycleStatus 5520;
BA_ "SigType" SG_ 2566711038 LubricationReservoirLevel 4;
BA_ "SPN" SG_ 2566711038 LubricationReservoirLevel 5519;
BA_ "SigType" SG_ 2566711038 LubricationPumpEnableStatus 5;
BA_ "SPN" SG_ 2566711038 LubricationPumpEnableStatus 5518;
BA_ "SPN" SG_ 2566711038 LubricationOperationModeStatus 5517;
BA_ "SPN" SG_ 2566711038 LubricationCycleModeStatus 5516;
BA_ "SigType" SG_ 2566711038 LubricationCycleModeLockStatus 5;
BA_ "SPN" SG_ 2566711038 LubricationCycleModeLockStatus 5515;
BA_ "SigType" SG_ 2566710782 HydOilTemp 1;
BA_ "SPN" SG_ 2566710782 HydOilTemp 5536;
BA_ "SigType" SG_ 2566710782 HydOilRelativeDielectricity 1;
BA_ "SPN" SG_ 2566710782 HydOilRelativeDielectricity 5535;
BA_ "SigType" SG_ 2566710782 HydOilDensity 1;
BA_ "SPN" SG_ 2566710782 HydOilDensity 5534;
BA_ "SigType" SG_ 2566710782 HydOilDynamicViscosity 1;
BA_ "SPN" SG_ 2566710782 HydOilDynamicViscosity 5533;
BA_ "SigType" SG_ 2566710526 EngFuelTemp 1;
BA_ "SPN" SG_ 2566710526 EngFuelTemp 5540;
BA_ "SigType" SG_ 2566710526 EngFuelDielectricity 1;
BA_ "SPN" SG_ 2566710526 EngFuelDielectricity 5539;
BA_ "SigType" SG_ 2566710526 EngFuelDensity 1;
BA_ "SPN" SG_ 2566710526 EngFuelDensity 5538;
BA_ "SigType" SG_ 2566710526 EngFuelDynamicViscosity 1;
BA_ "SPN" SG_ 2566710526 EngFuelDynamicViscosity 5537;
BA_ "SigType" SG_ 2432492542 DsredEngTurbo2TurbineOutletPress 1;
BA_ "SPN" SG_ 2432492542 DsredEngTurbo2TurbineOutletPress 5545;
BA_ "SigType" SG_ 2432492542 EngTurbo2TurbineOutletPress 1;
BA_ "SPN" SG_ 2432492542 EngTurbo2TurbineOutletPress 5544;
BA_ "SigType" SG_ 2432492542 EngExhaustBrakeActuatorCmd 1;
BA_ "SPN" SG_ 2432492542 EngExhaustBrakeActuatorCmd 5543;
BA_ "SigType" SG_ 2432492542 DsredEngTurbo1TurbineOutletPress 1;
BA_ "SPN" SG_ 2432492542 DsredEngTurbo1TurbineOutletPress 5542;
BA_ "SigType" SG_ 2432492542 EngTurbo1TurbineOutletPress 1;
BA_ "SPN" SG_ 2432492542 EngTurbo1TurbineOutletPress 5541;
BA_ "SigType" SG_ 2566710014 SupplementalFanPower 1;
BA_ "SPN" SG_ 2566710014 SupplementalFanPower 5564;
BA_ "SigType" SG_ 2566710014 SupplementalFanCurrent 1;
BA_ "SPN" SG_ 2566710014 SupplementalFanCurrent 5563;
BA_ "SigType" SG_ 2566710014 SupplementalFanSpeed 1;
BA_ "SPN" SG_ 2566710014 SupplementalFanSpeed 5562;
BA_ "SigType" SG_ 2566710014 SupplementalFanCtrlECUTemp 1;
BA_ "SPN" SG_ 2566710014 SupplementalFanCtrlECUTemp 5561;
BA_ "SPN" SG_ 2566710014 SupplementalFanDriveStatus 5560;
BA_ "SPN" SG_ 2566710014 SupplementalFanCtrlTempStatus 5559;
BA_ "SPN" SG_ 2566710014 SupplementalFanVelocityStatus 5558;
BA_ "SigType" SG_ 2566710014 SupplementalFanDirectionStatus 5;
BA_ "SPN" SG_ 2566710014 SupplementalFanDirectionStatus 5557;
BA_ "SigType" SG_ 2566710014 SupplementalFanEnableStatus 5;
BA_ "SPN" SG_ 2566710014 SupplementalFanEnableStatus 5556;
BA_ "SigType" SG_ 2566709758 HighResolutionEngFuelRate 1;
BA_ "SPN" SG_ 2566709758 HighResolutionEngFuelRate 1600;
BA_ "SigType" SG_ 2566709502 Aftertreatment2FuelMassRate 1;
BA_ "SPN" SG_ 2566709502 Aftertreatment2FuelMassRate 5834;
BA_ "SigType" SG_ 2566709502 Aftertreatment1FuelMassRate 1;
BA_ "SPN" SG_ 2566709502 Aftertreatment1FuelMassRate 5503;
BA_ "SigType" SG_ 2566709502 RelativeUnburnedFuelMassFromEng 1;
BA_ "SPN" SG_ 2566709502 RelativeUnburnedFuelMassFromEng 5502;
BA_ "SigType" SG_ 2566709502 Aftrtrtmnt1DslPrtcltFltrIntkTmpS 1;
BA_ "SPN" SG_ 2566709502 Aftrtrtmnt1DslPrtcltFltrIntkTmpS 5501;
BA_ "SigType" SG_ 2566709246 EngFuelFilterDegradation 1;
BA_ "SPN" SG_ 2566709246 EngFuelFilterDegradation 5584;
BA_ "SigType" SG_ 2566709246 EngFilteredFuelDeliveryAbsPress 1;
BA_ "SPN" SG_ 2566709246 EngFilteredFuelDeliveryAbsPress 5580;
BA_ "SigType" SG_ 2566709246 EngFilteredFuelDeliveryPress 1;
BA_ "SPN" SG_ 2566709246 EngFilteredFuelDeliveryPress 5579;
BA_ "SigType" SG_ 2566709246 EngFuelDeliveryAbsPress 1;
BA_ "SPN" SG_ 2566709246 EngFuelDeliveryAbsPress 5578;
BA_ "SigType" SG_ 2566708990 Aftertreatment1SecondAirAbsPress 1;
BA_ "SPN" SG_ 2566708990 Aftertreatment1SecondAirAbsPress 5589;
BA_ "SigType" SG_ 2566708734 Aftertreatment2SecondAirAbsPress 1;
BA_ "SPN" SG_ 2566708734 Aftertreatment2SecondAirAbsPress 5590;
BA_ "SigType" SG_ 2566708478 AEBSReadinessState 5;
BA_ "SPN" SG_ 2566708478 AEBSReadinessState 6208;
BA_ "SPN" SG_ 2566708478 SrcAddrssOfCntrllngDvcFrPsngCrsC 5609;
BA_ "SPN" SG_ 2566708478 SrcAddrssOfCntrllngDvcFrDsblngCr 5608;
BA_ "SPN" SG_ 2566708478 CruiseCtrlSystemCmdState 5607;
BA_ "SigType" SG_ 2566708478 AdptiveCruiseCtrlReadinessStatus 5;
BA_ "SPN" SG_ 2566708478 AdptiveCruiseCtrlReadinessStatus 5606;
BA_ "SigType" SG_ 2566708222 Aftrtrtmnt1DslPrtcltFltr1StS5635 1;
BA_ "SPN" SG_ 2566708222 Aftrtrtmnt1DslPrtcltFltr1StS5635 5635;
BA_ "SigType" SG_ 2566708222 Aftrtrtmnt1DslPrtcltFltr1StS5634 1;
BA_ "SPN" SG_ 2566708222 Aftrtrtmnt1DslPrtcltFltr1StS5634 5634;
BA_ "SigType" SG_ 2566708222 Aftrtrtmnt1DslPrtcltFltr1StS5633 1;
BA_ "SPN" SG_ 2566708222 Aftrtrtmnt1DslPrtcltFltr1StS5633 5633;
BA_ "SigType" SG_ 2566708222 Aftrtrtmnt1DslPrtcltFltr1StSnsrA 1;
BA_ "SPN" SG_ 2566708222 Aftrtrtmnt1DslPrtcltFltr1StSnsrA 5632;
BA_ "SigType" SG_ 2566707966 Aftrtrtmnt1DslPrtcltFltr1StS5639 1;
BA_ "SPN" SG_ 2566707966 Aftrtrtmnt1DslPrtcltFltr1StS5639 5639;
BA_ "SigType" SG_ 2566707966 Aftrtrtmnt1DslPrtcltFltr1StS5638 1;
BA_ "SPN" SG_ 2566707966 Aftrtrtmnt1DslPrtcltFltr1StS5638 5638;
BA_ "SigType" SG_ 2566707966 Aftrtrtmnt1DslPrtcltFltr1StSnsrF 1;
BA_ "SPN" SG_ 2566707966 Aftrtrtmnt1DslPrtcltFltr1StSnsrF 5637;
BA_ "SigType" SG_ 2566707966 Aftrtrtmnt1DslPrtcltFltr1StSnsrA 1;
BA_ "SPN" SG_ 2566707966 Aftrtrtmnt1DslPrtcltFltr1StSnsrA 5636;
BA_ "SigType" SG_ 2566707710 Aftrtrtmnt1DslPrtcltFltr1StS5643 1;
BA_ "SPN" SG_ 2566707710 Aftrtrtmnt1DslPrtcltFltr1StS5643 5643;
BA_ "SigType" SG_ 2566707710 Aftrtrtmnt1DslPrtcltFltr1StS5642 1;
BA_ "SPN" SG_ 2566707710 Aftrtrtmnt1DslPrtcltFltr1StS5642 5642;
BA_ "SigType" SG_ 2566707710 Aftrtrtmnt1DslPrtcltFltr1StSnsrF 1;
BA_ "SPN" SG_ 2566707710 Aftrtrtmnt1DslPrtcltFltr1StSnsrF 5641;
BA_ "SigType" SG_ 2566707710 Aftrtrtmnt1DslPrtcltFltr1StSnsrA 1;
BA_ "SPN" SG_ 2566707710 Aftrtrtmnt1DslPrtcltFltr1StSnsrA 5640;
BA_ "SigType" SG_ 2297441790 SpprtVrblTrnsRpttnRtFrAcclrtnSns 5;
BA_ "SPN" SG_ 2297441790 SpprtVrblTrnsRpttnRtFrAcclrtnSns 5353;
BA_ "SigType" SG_ 2297441790 VrtclAcclrtnExRangeFigureOfMerit 5;
BA_ "SPN" SG_ 2297441790 VrtclAcclrtnExRangeFigureOfMerit 5352;
BA_ "SigType" SG_ 2297441790 LngtdnlAcclrtnExRngFigureOfMerit 5;
BA_ "SPN" SG_ 2297441790 LngtdnlAcclrtnExRngFigureOfMerit 5351;
BA_ "SigType" SG_ 2297441790 LtrlAcclrtonExRangeFigureOfMerit 5;
BA_ "SPN" SG_ 2297441790 LtrlAcclrtonExRangeFigureOfMerit 5350;
BA_ "SigType" SG_ 2297441790 VerticalAccelerationExRange 1;
BA_ "SPN" SG_ 2297441790 VerticalAccelerationExRange 5349;
BA_ "SigType" SG_ 2297441790 LongitudinalAccelerationExRange 1;
BA_ "SPN" SG_ 2297441790 LongitudinalAccelerationExRange 5348;
BA_ "SigType" SG_ 2297441790 LateralAccelerationExRange 1;
BA_ "SPN" SG_ 2297441790 LateralAccelerationExRange 5347;
BA_ "SigType" SG_ 2566699006 HybridBatteryPackRemainingCharge 1;
BA_ "SPN" SG_ 2566699006 HybridBatteryPackRemainingCharge 5464;
BA_ "SigType" SG_ 2364549630 RllAndPtchExRngMasurementLatency 1;
BA_ "SPN" SG_ 2364549630 RllAndPtchExRngMasurementLatency 4982;
BA_ "SigType" SG_ 2364549630 RollAngleExRangeFigureOfMerit 5;
BA_ "SPN" SG_ 2364549630 RollAngleExRangeFigureOfMerit 4981;
BA_ "SigType" SG_ 2364549630 RollAngleExRangeCompensation 5;
BA_ "SPN" SG_ 2364549630 RollAngleExRangeCompensation 4980;
BA_ "SigType" SG_ 2364549630 PitchAngleExRangeFigureOfMerit 5;
BA_ "SPN" SG_ 2364549630 PitchAngleExRangeFigureOfMerit 4979;
BA_ "SigType" SG_ 2364549630 PitchAngleExRangeCompensation 5;
BA_ "SPN" SG_ 2364549630 PitchAngleExRangeCompensation 4978;
BA_ "SPN" SG_ 2364549630 RollAngleExRange 4977;
BA_ "SPN" SG_ 2364549630 PitchAngleExRange 4976;
BA_ "SigType" SG_ 2499614462 OccpntClssficationSystem10Status 5;
BA_ "SPN" SG_ 2499614462 OccpntClssficationSystem10Status 4972;
BA_ "SigType" SG_ 2499614462 OccpntClssificationSystem9Status 5;
BA_ "SPN" SG_ 2499614462 OccpntClssificationSystem9Status 4971;
BA_ "SigType" SG_ 2499614462 OccpntClssificationSystem8Status 5;
BA_ "SPN" SG_ 2499614462 OccpntClssificationSystem8Status 4970;
BA_ "SigType" SG_ 2499614462 OccpntClssificationSystem7Status 5;
BA_ "SPN" SG_ 2499614462 OccpntClssificationSystem7Status 4969;
BA_ "SigType" SG_ 2499614462 OccpntClssificationSystem6Status 5;
BA_ "SPN" SG_ 2499614462 OccpntClssificationSystem6Status 4968;
BA_ "SigType" SG_ 2499614462 OccpntClssificationSystem5Status 5;
BA_ "SPN" SG_ 2499614462 OccpntClssificationSystem5Status 4967;
BA_ "SigType" SG_ 2499614462 OccpntClssificationSystem4Status 5;
BA_ "SPN" SG_ 2499614462 OccpntClssificationSystem4Status 4966;
BA_ "SigType" SG_ 2499614462 OccpntClssificationSystem3Status 5;
BA_ "SPN" SG_ 2499614462 OccpntClssificationSystem3Status 4965;
BA_ "SPN" SG_ 2499614462 PssngrOccpntClssfctnSystemStatus 4964;
BA_ "SPN" SG_ 2499614462 DrvrOccpntClssfctionSystemStatus 4963;
BA_ "SPN" SG_ 2560098046 CabNoiseCtrlTuningStatus 5060;
BA_ "SigType" SG_ 2560098046 CabNoiseCtrlStatus 5;
BA_ "SPN" SG_ 2560098046 CabNoiseCtrlStatus 5059;
BA_ "SPN" SG_ 2560163582 CabNoiseCtrlTuningCmd 5058;
BA_ "SigType" SG_ 2560163582 CabNoiseCtrlCmd 5;
BA_ "SPN" SG_ 2560163582 CabNoiseCtrlCmd 5057;
BA_ "SigType" SG_ 2297441534 MagnetGeneratorCtrl 5;
BA_ "SPN" SG_ 2297441534 MagnetGeneratorCtrl 5551;
BA_ "SigType" SG_ 2297441534 DropRelayCtrl 5;
BA_ "SPN" SG_ 2297441534 DropRelayCtrl 5403;
BA_ "SigType" SG_ 2297441534 LiftRelayCtrl 5;
BA_ "SPN" SG_ 2297441534 LiftRelayCtrl 5402;
BA_ "SigType" SG_ 2297441534 MaterialDropActiveStatus 5;
BA_ "SPN" SG_ 2297441534 MaterialDropActiveStatus 5014;
BA_ "SigType" SG_ 2297441534 MaterialLiftActiveStatus 5;
BA_ "SPN" SG_ 2297441534 MaterialLiftActiveStatus 5013;
BA_ "SigType" SG_ 2297441534 GneratorCurrentBoostActiveStatus 5;
BA_ "SPN" SG_ 2297441534 GneratorCurrentBoostActiveStatus 5012;
BA_ "SigType" SG_ 2297441534 MaterialDropSwitch 5;
BA_ "SPN" SG_ 2297441534 MaterialDropSwitch 5011;
BA_ "SigType" SG_ 2297441534 MaterialLiftSwitch 5;
BA_ "SPN" SG_ 2297441534 MaterialLiftSwitch 5010;
BA_ "SigType" SG_ 2297441534 MagnetReverseCurrent 1;
BA_ "SPN" SG_ 2297441534 MagnetReverseCurrent 5009;
BA_ "SigType" SG_ 2297441534 MagnetForwardCurrent 1;
BA_ "SPN" SG_ 2297441534 MagnetForwardCurrent 5008;
BA_ "SigType" SG_ 2566722302 GeneratorDutyCycleExceededStatus 5;
BA_ "SPN" SG_ 2566722302 GeneratorDutyCycleExceededStatus 5007;
BA_ "SigType" SG_ 2566722302 VoltageMonitorActiveStatus 5;
BA_ "SPN" SG_ 2566722302 VoltageMonitorActiveStatus 5006;
BA_ "SigType" SG_ 2566722302 GensetEnableActiveStatus 5;
BA_ "SPN" SG_ 2566722302 GensetEnableActiveStatus 5005;
BA_ "SPN" SG_ 2566722302 ReverseCurrentRangeSetting 5002;
BA_ "SigType" SG_ 2566722302 GensetSoftstartActiveStatus 5;
BA_ "SPN" SG_ 2566722302 GensetSoftstartActiveStatus 5004;
BA_ "SigType" SG_ 2566722302 Grapple_MagnetSelectionSwitch 5;
BA_ "SPN" SG_ 2566722302 Grapple_MagnetSelectionSwitch 5003;
BA_ "SigType" SG_ 2566722302 GnstSystmOtputVoltageRangeStatus 5;
BA_ "SPN" SG_ 2566722302 GnstSystmOtputVoltageRangeStatus 5001;
BA_ "SigType" SG_ 2566722302 GeneratorOverheatStatus 5;
BA_ "SPN" SG_ 2566722302 GeneratorOverheatStatus 5000;
BA_ "SigType" SG_ 2566722558 MagnetRatedPower 1;
BA_ "SPN" SG_ 2566722558 MagnetRatedPower 4999;
BA_ "SigType" SG_ 2566722558 MagnetBoostTime 1;
BA_ "SPN" SG_ 2566722558 MagnetBoostTime 4998;
BA_ "SPN" SG_ 2560032510 LwVltgDscnnctDsiredOperatingMode 5149;
BA_ "SigType" SG_ 2566717950 LowVoltageDisconnectTemp 1;
BA_ "SPN" SG_ 2566717950 LowVoltageDisconnectTemp 5148;
BA_ "SPN" SG_ 2566717950 LwVltgeDisconnectVoutOutputState 5147;
BA_ "SPN" SG_ 2566717950 LowVoltageDisconnectOutput1State 5146;
BA_ "SPN" SG_ 2566717950 LowVoltageDisconnectOutput2State 5145;
BA_ "SPN" SG_ 2566717950 LowVoltageDisconnectOutput3State 5144;
BA_ "SPN" SG_ 2566717950 LwVltgDscnnctCrrentOperatingMode 5143;
BA_ "SigType" SG_ 2566717950 LwVltgDscnnectManualConnectState 4;
BA_ "SPN" SG_ 2566717950 LwVltgDscnnectManualConnectState 5142;
BA_ "SigType" SG_ 2566717950 LwVltgDscnnctMnalDisconnectState 4;
BA_ "SPN" SG_ 2566717950 LwVltgDscnnctMnalDisconnectState 5141;
BA_ "SigType" SG_ 2499604222 BldReferenceElevationOffsetRight 1;
BA_ "SPN" SG_ 2499604222 BldReferenceElevationOffsetRight 5413;
BA_ "SigType" SG_ 2499604222 BldeReferenceElevationOffsetLeft 1;
BA_ "SPN" SG_ 2499604222 BldeReferenceElevationOffsetLeft 5412;
BA_ "SigType" SG_ 2499604222 BladeElevationDeviationRight 1;
BA_ "SPN" SG_ 2499604222 BladeElevationDeviationRight 5411;
BA_ "SigType" SG_ 2499604222 BladeElevationDeviationLeft 1;
BA_ "SPN" SG_ 2499604222 BladeElevationDeviationLeft 5410;
BA_ "SigType" SG_ 2358902526 Joystick3Lamp10Cmd 5;
BA_ "SPN" SG_ 2358902526 Joystick3Lamp10Cmd 4489;
BA_ "SigType" SG_ 2358902526 Joystick3Lamp9Cmd 5;
BA_ "SPN" SG_ 2358902526 Joystick3Lamp9Cmd 4488;
BA_ "SigType" SG_ 2358902526 Joystick3Lamp8Cmd 5;
BA_ "SPN" SG_ 2358902526 Joystick3Lamp8Cmd 4487;
BA_ "SigType" SG_ 2358902526 Joystick3Lamp7Cmd 5;
BA_ "SPN" SG_ 2358902526 Joystick3Lamp7Cmd 4486;
BA_ "SigType" SG_ 2358902526 Joystick3Lamp6Cmd 5;
BA_ "SPN" SG_ 2358902526 Joystick3Lamp6Cmd 4485;
BA_ "SigType" SG_ 2358902526 Joystick3Lamp5Cmd 5;
BA_ "SPN" SG_ 2358902526 Joystick3Lamp5Cmd 4484;
BA_ "SigType" SG_ 2358902526 Joystick3Lamp4Cmd 5;
BA_ "SPN" SG_ 2358902526 Joystick3Lamp4Cmd 4483;
BA_ "SigType" SG_ 2358902526 Joystick3Lamp3Cmd 5;
BA_ "SPN" SG_ 2358902526 Joystick3Lamp3Cmd 4482;
BA_ "SigType" SG_ 2358902526 Joystick3Lamp2Cmd 5;
BA_ "SPN" SG_ 2358902526 Joystick3Lamp2Cmd 4481;
BA_ "SigType" SG_ 2358902526 Joystick3Lamp1Cmd 5;
BA_ "SPN" SG_ 2358902526 Joystick3Lamp1Cmd 4480;
BA_ "SigType" SG_ 2358902526 Joystick2Lamp10Cmd 5;
BA_ "SPN" SG_ 2358902526 Joystick2Lamp10Cmd 4479;
BA_ "SigType" SG_ 2358902526 Joystick2Lamp9Cmd 5;
BA_ "SPN" SG_ 2358902526 Joystick2Lamp9Cmd 4478;
BA_ "SigType" SG_ 2358902526 Joystick2Lamp8Cmd 5;
BA_ "SPN" SG_ 2358902526 Joystick2Lamp8Cmd 4477;
BA_ "SigType" SG_ 2358902526 Joystick2Lamp7Cmd 5;
BA_ "SPN" SG_ 2358902526 Joystick2Lamp7Cmd 4476;
BA_ "SigType" SG_ 2358902526 Joystick2Lamp6Cmd 5;
BA_ "SPN" SG_ 2358902526 Joystick2Lamp6Cmd 4475;
BA_ "SigType" SG_ 2358902526 Joystick2Lamp5Cmd 5;
BA_ "SPN" SG_ 2358902526 Joystick2Lamp5Cmd 4474;
BA_ "SigType" SG_ 2358902526 Joystick2Lamp4Cmd 5;
BA_ "SPN" SG_ 2358902526 Joystick2Lamp4Cmd 4473;
BA_ "SigType" SG_ 2358902526 Joystick2Lamp3Cmd 5;
BA_ "SPN" SG_ 2358902526 Joystick2Lamp3Cmd 4472;
BA_ "SigType" SG_ 2358902526 Joystick2Lamp2Cmd 5;
BA_ "SPN" SG_ 2358902526 Joystick2Lamp2Cmd 4471;
BA_ "SigType" SG_ 2358902526 Joystick2Lamp1Cmd 5;
BA_ "SPN" SG_ 2358902526 Joystick2Lamp1Cmd 4470;
BA_ "SigType" SG_ 2358902526 Joystick1Lamp10Cmd 5;
BA_ "SPN" SG_ 2358902526 Joystick1Lamp10Cmd 4469;
BA_ "SigType" SG_ 2358902526 Joystick1Lamp9Cmd 5;
BA_ "SPN" SG_ 2358902526 Joystick1Lamp9Cmd 4468;
BA_ "SigType" SG_ 2358902526 Joystick1Lamp8Cmd 5;
BA_ "SPN" SG_ 2358902526 Joystick1Lamp8Cmd 4467;
BA_ "SigType" SG_ 2358902526 Joystick1Lamp7Cmd 5;
BA_ "SPN" SG_ 2358902526 Joystick1Lamp7Cmd 4466;
BA_ "SigType" SG_ 2358902526 Joystick1Lamp6Cmd 5;
BA_ "SPN" SG_ 2358902526 Joystick1Lamp6Cmd 4465;
BA_ "SigType" SG_ 2358902526 Joystick1Lamp5Cmd 5;
BA_ "SPN" SG_ 2358902526 Joystick1Lamp5Cmd 4464;
BA_ "SigType" SG_ 2358902526 Joystick1Lamp4Cmd 5;
BA_ "SPN" SG_ 2358902526 Joystick1Lamp4Cmd 4463;
BA_ "SigType" SG_ 2358902526 Joystick1Lamp3Cmd 5;
BA_ "SPN" SG_ 2358902526 Joystick1Lamp3Cmd 4462;
BA_ "SigType" SG_ 2358902526 Joystick1Lamp2Cmd 5;
BA_ "SPN" SG_ 2358902526 Joystick1Lamp2Cmd 4461;
BA_ "SigType" SG_ 2358902526 Joystick1Lamp1Cmd 5;
BA_ "SPN" SG_ 2358902526 Joystick1Lamp1Cmd 4460;
VAL_ 2364553214 EngTrbCmprssrBlwffActtr1OprtnStt 15 "Not available" 14 "Error" 5 "Uncontrolled Shutdown Active (no torque is being applied from the actuator)" 4 "Controlled Shutdown Active (driving to the default position - usually this means closed)" 3 "Derate Active (torque output reduced due to environmental conditions)" 2 "Alarm High Severity (functional but transient performance may be reduced)" 1 "Alarm (fully operational but needs service)" 0 "Normal" ;
VAL_ 2364553214 EngTrbCmprssrBlwffActtr1TmpSttus 7 "Not available" 6 "Error" 5 "Not Defined" 4 "Low Most severe" 3 "Low Least severe" 2 "In Range" 1 "High Least severe" 0 "High Most severe" ;
VAL_ 2559049470 DesiredEngFuelingState 3 "Dont care / Take no action" 2 "Parameter supported but no request" 1 "Fueling desired keep engine running" 0 "Fueling not desired shut off engine fueling" ;
VAL_ 2559049470 RequestedFuelType 255 "Not supported" 254 "Reserved for use in SPN 5837" 24 "Reserved for use in SPN 5837" 23 "Natural Gas (NG) - NG" 7 "Propane - PROP" 6 "Compressed Natural Gas (CNG) - CNG" 5 "Liquefied Petroleum Gas (LPG) - LPG" 4 "Diesel - DSL" 3 "Ethanol - ETH" 2 "Methanol - METH" 1 "Gasoline/petrol - GAS" 0 "Not available - NONE" ;
VAL_ 2349596414 DrvrActvtnDmndFrAdvncdEmrgncyBrk 3 "dont care / take no action" 2 "reserved" 1 "the driver wants the Advanced Emergency Braking System to warn or intervene if necessary no deactivation of" 0 "the driver does not want the Advanced Emergency Braking System to warn or intervene at any time deactivation of" ;
VAL_ 2358509310 NMControlModeIndicator 0 "SetPendingName" 1 "PendingName" 2 "CurrentName" 3 "NameACK" 4 "NameNACK" 5 "ReqPendingName" 6 "ReqCurrentName" 7 "AdoptPendingName" 8 "ReqNameAddressClaim" ;
VAL_ 2358509310 ErrorCode 0 "Security not satisfied" 1 "Item(s) not allowed to change" 2 "Item conflict" 3 "Checksum does not match" 4 "Pending Name not set" 255 "Not Available" 5 "Other" ;
VAL_ 2558983934 SwitchedPowerOutput18Cmd 3 "Take no action" 2 "Reserved" 1 "Output on" 0 "Output off" ;
VAL_ 2558983934 SwitchedPowerOutput19Cmd 3 "Take no action" 2 "Reserved" 1 "Output on" 0 "Output off" ;
VAL_ 2558983934 SwitchedPowerOutput20Cmd 3 "Take no action" 2 "Reserved" 1 "Output on" 0 "Output off" ;
VAL_ 2558983934 SwitchedPowerOutput13Cmd 3 "Take no action" 2 "Reserved" 1 "Output on" 0 "Output off" ;
VAL_ 2558983934 SwitchedPowerOutput14Cmd 3 "Take no action" 2 "Reserved" 1 "Output on" 0 "Output off" ;
VAL_ 2558983934 SwitchedPowerOutput15Cmd 3 "Take no action" 2 "Reserved" 1 "Output on" 0 "Output off" ;
VAL_ 2558983934 SwitchedPowerOutput16Cmd 3 "Take no action" 2 "Reserved" 1 "Output on" 0 "Output off" ;
VAL_ 2558983934 SwitchedPowerOutput9Cmd 3 "Take no action" 2 "Reserved" 1 "Output on" 0 "Output off" ;
VAL_ 2558983934 SwitchedPowerOutput10Cmd 3 "Take no action" 2 "Reserved" 1 "Output on" 0 "Output off" ;
VAL_ 2558983934 SwitchedPowerOutput29Cmd 3 "Take no action" 2 "Reserved" 1 "Output on" 0 "Output off" ;
VAL_ 2558983934 SwitchedPowerOutput30Cmd 3 "Take no action" 2 "Reserved" 1 "Output on" 0 "Output off" ;
VAL_ 2558983934 SwitchedPowerOutput31Cmd 3 "Take no action" 2 "Reserved" 1 "Output on" 0 "Output off" ;
VAL_ 2558983934 SwitchedPowerOutput32Cmd 3 "Take no action" 2 "Reserved" 1 "Output on" 0 "Output off" ;
VAL_ 2558983934 SwitchedPowerOutput25Cmd 3 "Take no action" 2 "Reserved" 1 "Output on" 0 "Output off" ;
VAL_ 2558983934 SwitchedPowerOutput26Cmd 3 "Take no action" 2 "Reserved" 1 "Output on" 0 "Output off" ;
VAL_ 2558983934 SwitchedPowerOutput27Cmd 3 "Take no action" 2 "Reserved" 1 "Output on" 0 "Output off" ;
VAL_ 2558983934 SwitchedPowerOutput28Cmd 3 "Take no action" 2 "Reserved" 1 "Output on" 0 "Output off" ;
VAL_ 2558983934 SwitchedPowerOutput21Cmd 3 "Take no action" 2 "Reserved" 1 "Output on" 0 "Output off" ;
VAL_ 2558983934 SwitchedPowerOutput22Cmd 3 "Take no action" 2 "Reserved" 1 "Output on" 0 "Output off" ;
VAL_ 2558983934 SwitchedPowerOutput23Cmd 3 "Take no action" 2 "Reserved" 1 "Output on" 0 "Output off" ;
VAL_ 2558983934 SwitchedPowerOutput24Cmd 3 "Take no action" 2 "Reserved" 1 "Output on" 0 "Output off" ;
VAL_ 2558983934 SwitchedPowerOutput17Cmd 3 "Take no action" 2 "Reserved" 1 "Output on" 0 "Output off" ;
VAL_ 2558983934 SwitchedPowerOutput11Cmd 3 "Take no action" 2 "Reserved" 1 "Output on" 0 "Output off" ;
VAL_ 2558983934 SwitchedPowerOutput12Cmd 1 "Output on" 0 "Output off" 3 "Take no action" 2 "Reserved" ;
VAL_ 2558983934 SwitchedPowerOutput5Cmd 3 "Take no action" 2 "Reserved" 1 "Output on" 0 "Output off" ;
VAL_ 2558983934 SwitchedPowerOutput6Cmd 3 "Take no action" 2 "Reserved" 1 "Output on" 0 "Output off" ;
VAL_ 2558983934 SwitchedPowerOutput7Cmd 3 "Take no action" 2 "Reserved" 1 "Output on" 0 "Output off" ;
VAL_ 2558983934 SwitchedPowerOutput8Cmd 3 "Take no action" 2 "Reserved" 1 "Output on" 0 "Output off" ;
VAL_ 2558983934 SwitchedPowerOutput1Cmd 3 "Take no action" 2 "Reserved" 1 "Output on" 0 "Output off" ;
VAL_ 2558983934 SwitchedPowerOutput2Cmd 3 "Take no action" 2 "Reserved" 1 "Output on" 0 "Output off" ;
VAL_ 2558983934 SwitchedPowerOutput3Cmd 3 "Take no action" 2 "Reserved" 1 "Output on" 0 "Output off" ;
VAL_ 2558983934 SwitchedPowerOutput4Cmd 3 "Take no action" 2 "Reserved" 1 "Output on" 0 "Output off" ;
VAL_ 2349727486 TransMode10 3 "Take no action" 2 "Reserved" 1 "Enable" 0 "Disable" ;
VAL_ 2349727486 TransMode9 3 "Take no action" 2 "Reserved" 1 "Enable" 0 "Disable" ;
VAL_ 2566767358 FuelType 255 "Not available (Parameter not supported)" 254 "Error" 24 "Bi-fuel vehicle using NG – BI_NG" 23 "Natural Gas (NG) - NG" 22 "Hybrid vehicle in regeneration mode - HYB_REG" 21 "Hybrid vehicle using battery and combustion engine - HYB_MIX" 20 "Hybrid vehicle using battery - HYB_ELEC" 19 "Hybrid vehicle using diesel engine - HYB_DSL" 18 "Hybrid vehicle using gasoline engine on ethanol - HYB_ETH" 17 "Hybrid vehicle using gasoline engine - HYB_GAS" 16 "Bi-fuel vehicle using battery and combustion engine - BI_MIX" 15 "Bi-fuel vehicle using battery - BI_ELEC" 14 "Bi-fuel vehicle using propane - BI_PROP" 13 "Bi-fuel vehicle using CNG - BI_CNG" 12 "Bi-fuel vehicle using LPG - BI_LPG" 11 "Bi-fuel vehicle using ethanol - BI_ETH" 10 "Bi-fuel vehicle using methanol - BI_METH" 9 "Bi-fuel vehicle using gasoline - BI_GAS" 8 "Battery/electric - ELEC" 7 "Propane - PROP" 6 "Compressed Natural Gas (CNG) - CNG" 5 "Liquefied Petroleum Gas (LPG) - LPG" 4 "Diesel - DSL" 3 "Ethanol - ETH" 2 "Methanol - METH" 1 "Gasoline/petrol - GAS" 0 "Not available - NONE" ;
VAL_ 2566705150 NOxSnsorATI2SelfdiagnosisTrigger 15 "Not supported" 4 "NOx Sensor ATI2 Self Diagnosis Request at After Run" 3 "NOx Sensor ATI2 Self Diagnosis Request at fuel cut" 2 "NOx Sensor ATI2 Self Diagnosis Request at partial load" 1 "NOx Sensor ATI2 Self Diagnosis Request at Lambda10" 0 "Diagnostic mode disabled" ;
VAL_ 2566705150 NOxSnsorATO2SelfdiagnosisTrigger 15 "Not supported" 4 "NOx Sensor ATO2 Self Diagnosis Request at After Run" 3 "NOx Sensor ATO2 Self Diagnosis Request at fuel cut" 2 "NOx Sensor ATO2 Self Diagnosis Request at partial load" 1 "NOx Sensor ATO2 Self Diagnosis Request at Lambda10" 0 "Diagnostic mode disabled" ;
VAL_ 2566705150 NOxSnsorATI1SelfdiagnosisTrigger 15 "Not supported" 4 "NOx Sensor ATI1 Self Diagnosis Request at After Run" 3 "NOx Sensor ATI1 Self Diagnosis Request at fuel cut" 2 "NOx Sensor ATI1 Self Diagnosis Request at partial load" 1 "NOx Sensor ATI1 Self Diagnosis Request at Lambda10" 0 "Diagnostic mode disabled" ;
VAL_ 2566705150 NOxSnsorATO1SelfdiagnosisTrigger 15 "Not supported" 4 "NOx Sensor ATO1 Self Diagnosis Request at After Run" 3 "NOx Sensor ATO1 Self Diagnosis Request at fuel cut" 2 "NOx Sensor ATO1 Self Diagnosis Request at partial load" 1 "NOx Sensor ATO1 Self Diagnosis Request at Lambda10" 0 "Diagnostic mode disabled" ;
VAL_ 2566704382 Aftrtrtmnt2OtltGsSnsrPowerSupply 3 "Unavailable" 2 "Error" 1 "On The ECU is powering the Aftertreatment 2 Outlet Gas Sensor" 0 "Off" ;
VAL_ 2566704382 Aftrtrtmnt2IntkGsSnsrPowerSupply 3 "Unavailable" 2 "Error" 1 "On The ECU is powering the Aftertreatment 2 Intake Gas Sensor" 0 "Off" ;
VAL_ 2566704382 Aftrtrtmnt1OtltGsSnsrPowerSupply 3 "Unavailable" 2 "Error" 1 "On The ECU is powering the Aftertreatment 1 Outlet Gas Sensor" 0 "Off" ;
VAL_ 2566704382 Aftrtrtmnt1IntkGsSnsrPowerSupply 3 "Unavailable" 2 "Error" 1 "On The ECU is powering the Aftertreatment 1 Intake Gas Sensor" 0 "Off" ;
VAL_ 2566704126 EngExhstGsRcrcltn1Acttr2OprtnStt 15 "Not available" 14 "Error" 5 "Uncontrolled Shutdown Active actuator current is off so it is limp" 4 "Controlled Shutdown Active driving to the default position  usually this means closed" 3 "Derate Active torque output reduced due to environmental conditions" 2 "Alarm High Severity functional but transient performance may be reduced" 1 "Alarm fully operational but needs service" 0 "Normal" ;
VAL_ 2566704126 EngExhstGsRcrcltn1Acttr1OprtnStt 15 "Not available" 14 "Error" 5 "Uncontrolled Shutdown Active actuator current is off so it is limp" 4 "Controlled Shutdown Active driving to the default position  usually this means closed" 3 "Derate Active torque output reduced due to environmental conditions" 2 "Alarm High Severity functional but transient performance may be reduced" 1 "Alarm fully operational but needs service" 0 "Normal" ;
VAL_ 2566704126 EngExhstGsRcrcltn1Acttr2TmpSttus 7 "Not available" 6 "Error" 5 "Not Defined" 4 "Low Most severe" 3 "Low Least severe" 2 "In Range" 1 "High Least severe" 0 "High Most severe" ;
VAL_ 2566704126 EngExhstGsRcrcltn1Acttr1TmpSttus 7 "Not available" 6 "Error" 5 "Not Defined" 4 "Low Most severe" 3 "Low Least severe" 2 "In Range" 1 "High Least severe" 0 "High Most severe" ;
VAL_ 2566703870 EngExhstGsRcrcltn2Acttr2OprtnStt 15 "Not available" 14 "Error" 5 "Uncontrolled Shutdown Active actuator current is off so it is limp" 4 "Controlled Shutdown Active driving to the default position  usually this means closed" 3 "Derate Active torque output reduced due to environmental conditions" 2 "Alarm High Severity functional but transient performance may be reduced" 1 "Alarm fully operational but needs service" 0 "Normal" ;
VAL_ 2566703870 EngExhstGsRcrcltn2Acttr1OprtnStt 5 "Uncontrolled Shutdown Active actuator current is off so it is limp" 4 "Controlled Shutdown Active driving to the default position  usually this means closed" 3 "Derate Active torque output reduced due to environmental conditions" 2 "Alarm High Severity functional but transient performance may be reduced" 1 "Alarm fully operational but needs service" 0 "Normal" 15 "Not available" 14 "Error" ;
VAL_ 2566703870 EngExhstGsRcrcltn2Acttr2TmpSttus 7 "Not available" 6 "Error" 5 "Not Defined" 4 "Low Most severe" 3 "Low Least severe" 2 "In Range" 1 "High Least severe" 0 "High Most severe" ;
VAL_ 2566703870 EngExhstGsRcrcltn2Acttr1TmpSttus 7 "Not available" 6 "Error" 5 "Not Defined" 4 "Low Most severe" 3 "Low Least severe" 2 "In Range" 1 "High Least severe" 0 "High Most severe" ;
VAL_ 2566703358 EngFuelingInhibitPreventedReason 15 "Not Supported" 4 "Service Override" 3 "Engine coolant temperature too low" 2 "Oil Distribution in engine is incomplete" 1 "DPF regeneration is active or preparing to be active" 0 "Fueling inhibit allowed (SPN 5795 = 01)" ;
VAL_ 2566703358 EngFuelingInhibitAllowed 3 "Not Supported" 2 "SAE Reserved" 1 "Engine will stop fueling in response to SPN 5793 Desired Engine Fueling State" 0 "Engine currently will not stop fueling in response to SPN 5793 Desired Engine Fueling State" ;
VAL_ 2566703358 FeedbackEngFuelingState 3 "Not Supported" 2 "No active request per SPN 5793 Desired Engine Fueling State" 1 "Engine will be kept running SPN 5793 Desired Engine Fueling State  01" 0 "Fueling is or will be inhibited SPN 5793 Desired Engine Fueling State  00" ;
VAL_ 2566701822 HybridSystemStopIndicator 3 "Not available" 2 "Hybrid System Stop Indicator is flashing" 1 "Hybrid System Stop Indicator is on continuously" 0 "Hybrid System Stop Indicator is off" ;
VAL_ 2566701822 HybridSystemOverheatIndicator 3 "Not available" 2 "Hybrid System Temperature Indicator is flashing" 1 "Hybrid System Temperature Indicator is on continuously" 0 "Hybrid System Temperature Indicator is off" ;
VAL_ 2566701822 HybridSystemWarningIndicator 3 "Not available" 2 "Hybrid System Warning Indicator is flashing" 1 "Hybrid System Warning Indicator is on continuously" 0 "Hybrid System Warning Indicator is off" ;
VAL_ 2431661310 Aftrtrtmnt2SCRIntrmdtNH3GsSn5861 3 "Heater off or Not available" 2 "Preheat 1" 1 "Preheat 2" 0 "Automatic" ;
VAL_ 2431661310 Aftrtrtmnt2SCRIntrmdtNH3GsSnsrAt 3 "Not available" 2 "Error" 1 "Heater element is in range" 0 "Heater element is not in range" ;
VAL_ 2431661310 Aftrtrtmnt2SCRIntrmdtNH3GsSnsrPw 3 "Not available" 2 "Error" 1 "Heater element is in range" 0 "Heater element is not in range" ;
VAL_ 2431661310 Aftrtrtmnt2SCRIntrmdtNH3RdngStbl 3 "Not available" 2 "Error" 1 "Reading is stable" 0 "Reading is not stable" ;
VAL_ 2431661054 Aftrtrtmnt1SCRIntrmdtNH3GsSn5854 3 "Heater off or not available" 2 "Preheat 1" 1 "Preheat 2" 0 "Automatic" ;
VAL_ 2431661054 Aftrtrtmnt1SCRIntrmdtNH3GsSnsrAt 3 "Not available" 2 "Error" 1 "Heater element is in range" 0 "Heater element is not in range" ;
VAL_ 2431661054 Aftrtrtmnt1SCRIntrmdtNH3GsSnsrPw 3 "Not available" 2 "Error" 1 "Power is in range" 0 "Power is not in range" ;
VAL_ 2431661054 Aftrtrtmnt1SCRIntrmdtNH3RdngStbl 3 "Not available" 2 "Error" 1 "Reading is stable" 0 "Reading is not stable" ;
VAL_ 2230334206 LnrDsplcmntSnsrSnsrFigureOfMerit 3 "Sensor not available" 2 "Sensor failed" 1 "Sensor degraded" 0 "Sensor fully functional" ;
VAL_ 2230333950 WandSensorFigureOfMerit 3 "Sensor not available" 2 "Sensor failed" 1 "Sensor degraded" 0 "Sensor fully functional" ;
VAL_ 2364551422 TransmitterCmdState 15 "Don't Care" 14 "Error" 4 "Standby" 3 "Transmitter Test" 2 "Field Test" 1 "Clear" 0 "Stop" ;
VAL_ 2364551166 BndOffPrbabilityOfRelevantObject 7 "signal not available / not installed" 6 "error indication" 5 "relevant object is already in a turning maneuver" 4 "highest probability for a bend off maneuver of the relevant object" 3 "high probability for a bend off maneuver of the relevant object" 2 "medium probability for a bend off maneuver of the relevant object" 1 "low probability for a bend off maneuver of the relevant object" 0 "no indication for a bend off maneuver of the relevant object" ;
VAL_ 2364551166 RlvntObjctDtctdFrAdvncdEmrgncyBr 7 "signal not available / not installed" 6 "error indication" 2 "relevant object is not being detected reliably" 1 "relevant object is being monitored" 0 "no relevant object monitored" ;
VAL_ 2364551166 CollisionWarningLevel 15 "dont care / take no action" 7 "warning level 7  highest" 6 "warning level 6" 5 "warning level 5" 4 "warning level 4" 3 "warning level 3" 2 "warning level 2" 1 "warning level 1  lowest" 0 "no warning" ;
VAL_ 2364551166 AdvncdEmrgencyBrakingSystemState 15 "not available / not installed" 14 "error indication" 7 "emergency braking active" 6 "collision warning with braking eg brake jerk or partial braking" 5 "collision warning active not affecting vehicle dynamics" 4 "driver overrides system" 3 "system is ready no warning and no braking active" 2 "system is deactivated by driver" 1 "system is temporarily not available eg due to boundary conditions necessary for operation" 0 "system is not ready initialization not finished" ;
VAL_ 2566730238 Fan2DriveState 15 "Not available" 14 "Other" 13 "Engine brake" 12 "Timer" 11 "A/C system" 10 "Transmission retarder" 9 "Manual control" 8 "Reverse Operation" 7 "Default Operation" 6 "Excessive hydraulic oil temperature" 5 "Excessive transmission oil temperature" 4 "Excessive engine coolant temperature" 3 "Excessive engine oil temperature" 2 "Excessive engine air temperature" 1 "Engine systemGeneral" 0 "Fan off" ;
VAL_ 2566711038 LubricationTimingCycleStatus 3 "Not available or not installed" 2 "Error" 1 "Enabled" 0 "Paused" ;
VAL_ 2566711038 LubricationReservoirLevel 3 "Not available or not installed" 2 "Error" 1 "Reservoir Low" 0 "Reservoir Not Low" ;
VAL_ 2566711038 LubricationPumpEnableStatus 3 "Not available" 2 "Error" 1 "Enabled" 0 "Disabled" ;
VAL_ 2566711038 LubricationOperationModeStatus 7 "Not Available" 6 "Error" 5 "Reserved" 4 "Test Mode  3" 3 "Test Mode  2" 2 "Test Mode  1" 1 "Manual Service Mode" 0 "Automatic Mode" ;
VAL_ 2566711038 LubricationCycleModeStatus 7 "Not available" 6 "Error" 2 "Cycle mode  3 Highest Lubrication Frequency" 1 "Cycle mode  2" 0 "Cycle mode  1 Lowest Lubrication Frequency" ;
VAL_ 2566711038 LubricationCycleModeLockStatus 3 "Not available" 2 "Error" 1 "Locked" 0 "Not Locked" ;
VAL_ 2566710014 SupplementalFanDriveStatus 15 "Not available" 14 "Error" 5 "Uncontrolled Shutdown Active  Actuator current is off so it is limp" 4 "Controlled Shutdown Active  Driving to the default position  usually this means closed" 3 "Derate Active  Torque output reduced due to environmental conditions" 2 "Alarm High Severity  Functional but transient performance may be reduced" 1 "Alarm  Fully operational but needs service" 0 "Normal  OK" ;
VAL_ 2566710014 SupplementalFanCtrlTempStatus 7 "Not available" 6 "Error" 5 "Not Defined" 4 "Low Most severe" 3 "Low Least severe" 2 "In Range" 1 "High Least severe" 0 "High most severe" ;
VAL_ 2566710014 SupplementalFanVelocityStatus 15 "Not available" 14 "Error" 4 "Fan Stall" 3 "Fan Spin Down" 2 "Fan Spin Up" 1 "Velocity Error  unable to achieve commanded speed" 0 "At Velocity Fan OK" ;
VAL_ 2566710014 SupplementalFanDirectionStatus 3 "Not available/Not installed" 2 "Error" 1 "Reverse" 0 "Forward" ;
VAL_ 2566710014 SupplementalFanEnableStatus 3 "Not available/Not installed" 2 "Error" 1 "Enabled" 0 "Disabled" ;
VAL_ 2566708478 AEBSReadinessState 3 "Not Available/Not Supported" 2 "Condition exists that prevents system from responding to AEBS commands even though it is configured" 1 "On -- engine is configured to accept commands from an AEBS" 0 "Off -- engine is not configured to accept commands from an AEBS" ;
VAL_ 2566708478 CruiseCtrlSystemCmdState 3 "Cruise control has been reactivated by Cruise Control Resume Command SPN 5604 and Cruise Control States" 2 "Cruise control  has been disabled by Cruise Control Pause Command SPN 5605" 1 "Cruise control has been disabled by Cruise Control Disable Command SPN 5603" 0 "No Cruise Control System Command" 7 "Not Supported" 4 "Cruise control device has received a Cruise Control Resume Command SPN 5604 but there is no previous set" ;
VAL_ 2566708478 AdptiveCruiseCtrlReadinessStatus 3 "Not Available/Not Supported" 2 "Error Condition  Prevents system from responding to adaptive cruise controller commands even though it is" 1 "On  Cruise Control System is configured to accept commands from an adaptive cruise controller" 0 "Off  Cruise Control System is not configured to accept commands from an adaptive cruise controller" ;
VAL_ 2297441790 VrtclAcclrtnExRangeFigureOfMerit 3 "not available" 2 "error" 1 "verticalacceleration is degraded Data is suspect due to enviromental conditions" 0 "vertical acceleration is fully functional Data is within sensor specification" ;
VAL_ 2297441790 LngtdnlAcclrtnExRngFigureOfMerit 3 "not available" 2 "error" 1 "longitudinal acceleration is degraded Data is suspect due to enviromental conditions" 0 "longitudinal acceleration is fully functional Data is within sensor specification" ;
VAL_ 2297441790 LtrlAcclrtonExRangeFigureOfMerit 3 "not available" 2 "error" 1 "lateral acceleration is degraded Data is suspect due to enviromental conditions" 0 "lateral acceleration is fully functional Data is within sensor specification" ;
VAL_ 2364549630 RollAngleExRangeFigureOfMerit 3 "Not available" 2 "Error" 1 "Roll rate degraded Data is suspect due to environmental conditions" 0 "Roll rate fully functional Data is within sensor specification" ;
VAL_ 2364549630 RollAngleExRangeCompensation 3 "Not Available" 2 "Error" 1 "Off" 0 "On" ;
VAL_ 2364549630 PitchAngleExRangeFigureOfMerit 3 "Not available" 2 "Error" 1 "Pitch rate degraded Data is suspect due to environmental conditions" 0 "Pitch rate fully functional Data is within sensor specification" ;
VAL_ 2364549630 PitchAngleExRangeCompensation 3 "Not Available" 2 "Error" 1 "Off" 0 "On" ;
VAL_ 2499614462 OccpntClssficationSystem10Status 3 "not available" 2 "Error  Classification cannot be determined" 1 "occupied" 0 "empty" ;
VAL_ 2499614462 OccpntClssificationSystem9Status 3 "not available" 2 "Error  Classification cannot be determined" 1 "occupied" 0 "empty" ;
VAL_ 2499614462 OccpntClssificationSystem8Status 3 "not available" 2 "Error  Classification cannot be determined" 1 "occupied" 0 "empty" ;
VAL_ 2499614462 OccpntClssificationSystem7Status 3 "not available" 2 "Error  Classification cannot be determined" 1 "occupied" 0 "empty" ;
VAL_ 2499614462 OccpntClssificationSystem6Status 3 "not available" 2 "Error  Classification cannot be determined" 1 "occupied" 0 "empty" ;
VAL_ 2499614462 OccpntClssificationSystem5Status 3 "not available" 2 "Error  Classification cannot be determined" 1 "occupied" 0 "empty" ;
VAL_ 2499614462 OccpntClssificationSystem4Status 3 "not available" 2 "Error  Classification cannot be determined" 1 "occupied" 0 "empty" ;
VAL_ 2499614462 OccpntClssificationSystem3Status 3 "not available" 2 "Error  Classification cannot be determined" 1 "occupied" 0 "empty" ;
VAL_ 2499614462 PssngrOccpntClssfctnSystemStatus 7 "not available" 5 "Error  Classification of occupant cannot be determined" 3 "adult" 4 "large adult" 2 "small adult" 1 "child" 0 "empty" ;
VAL_ 2499614462 DrvrOccpntClssfctionSystemStatus 7 "not available" 6 "Error  Classification of occupant cannot be determined" 5 "reserved" 4 "large adult" 3 "adult" 2 "small adult" 1 "child" 0 "empty" ;
VAL_ 2560098046 CabNoiseCtrlTuningStatus 12 "Reserved" 11 "Reserved" 6 "Reserved" 5 "Reserved" 4 "Reserved" 3 "Reserved" 15 "Not Available/Not Tuning/Not Requested" 14 "Tuning Mode  Error" 10 "Automatic Tuning Mode  Saving Data" 9 "Automatic Tuning Mode  Command Complete" 8 "Automatic Tuning Mode" 7 "Manual Tuning Denied  Requires Security Verification" 13 "Reserved" 2 "Manual Tuning Mode  Saving Data" 1 "Manual Tuning Mode  Command Complete" 0 "Manual Tuning Mode" ;
VAL_ 2560098046 CabNoiseCtrlStatus 3 "Not Available/Not Requested" 2 "Error Indicator" 1 "Cab Noise Control System OFFLine" 0 "Cab Noise Control System ONLine" ;
VAL_ 2560163582 CabNoiseCtrlTuningCmd 7 "Dont Care NOT Commanded" 6 "Reserved" 5 "Exit Tuning Saving Parameters" 4 "Exit Tuning Not Saving Parameters" 3 "Remain In Tuning Save Current Parameters" 2 "Activate Automatic Tuning State Saveing Parameters Exit on Completion" 1 "Activate Automatic Tuning Wait for Save and Exit Commands" 0 "Activate Manual Tuning Wait for Save and Exit Commands" ;
VAL_ 2560163582 CabNoiseCtrlCmd 3 "Dont Care/Not Commanded" 2 "Reserved" 1 "Bring Cab Noise Control System On Line" 0 "Take Cab Noise Control System Off Line" ;
VAL_ 2297441534 MagnetGeneratorCtrl 3 "Take No Action" 2 "Reserved" 1 "On Enable Generator" 0 "Off Disable Generator" ;
VAL_ 2297441534 DropRelayCtrl 3 "Take No Action" 2 "Reserved" 1 "On Enable Drop Relay Request" 0 "Off Disable Drop Relay Request" ;
VAL_ 2297441534 LiftRelayCtrl 3 "Take No Action" 2 "Reserved" 1 "On Enable Lift Relay Request" 0 "Off Disable Lift Relay Request" ;
VAL_ 2297441534 MaterialDropActiveStatus 3 "Not Available" 2 "Error" 1 "On" 0 "Off" ;
VAL_ 2297441534 MaterialLiftActiveStatus 3 "Not Available" 2 "Error" 1 "On" 0 "Off" ;
VAL_ 2297441534 GneratorCurrentBoostActiveStatus 3 "Not Available" 2 "Error" 1 "On" 0 "Off" ;
VAL_ 2297441534 MaterialDropSwitch 3 "Not Available" 2 "Error" 1 "Drop" 0 "Dont Drop" ;
VAL_ 2297441534 MaterialLiftSwitch 3 "Not Available" 2 "Error" 1 "Lift" 0 "Dont Lift" ;
VAL_ 2566722302 GeneratorDutyCycleExceededStatus 3 "Not Avaiable" 2 "Error" 1 "Duty Cycle Exceed" 0 "Duty Cycle Not Exceed" ;
VAL_ 2566722302 VoltageMonitorActiveStatus 3 "Not Available" 2 "Error" 1 "Monitor is On" 0 "Monitor is Off" ;
VAL_ 2566722302 GensetEnableActiveStatus 3 "Not Avaialble" 2 "Error" 1 "Enabled" 0 "Not Enabled" ;
VAL_ 2566722302 ReverseCurrentRangeSetting 31 "Not Available" 30 "Error" 15 "16" 14 "15" 13 "14" 12 "13" 11 "12" 10 "11" 9 "10" 8 "9" 7 "8" 6 "7" 5 "6" 4 "5" 3 "4" 2 "3" 1 "2" 0 "1" ;
VAL_ 2566722302 GensetSoftstartActiveStatus 3 "Not Available" 2 "Error" 1 "On" 0 "Off" ;
VAL_ 2566722302 Grapple_MagnetSelectionSwitch 3 "Not Available" 2 "Error" 1 "Magnet Selected" 0 "Grapple Selected" ;
VAL_ 2566722302 GnstSystmOtputVoltageRangeStatus 3 "Not Available" 2 "Error" 1 "In Range" 0 "Out of Range" ;
VAL_ 2566722302 GeneratorOverheatStatus 3 "Not Available" 2 "Error" 1 "Overheat" 0 "Not Overheat" ;
VAL_ 2560032510 LwVltgDscnnctDsiredOperatingMode 15 "No change" 5 "Manual Connect" 4 "Manual Disconnect" 0 "Automatic" ;
VAL_ 2566717950 LwVltgeDisconnectVoutOutputState 15 "Not available or not installed" 14 "Output fault" 4 "Connect pending alarm active" 3 "Disconnect pending alarm active" 2 "Disconnect alarm expired output off or disconnected" 1 "Output on or connected" 0 "Output off or disconnected" ;
VAL_ 2566717950 LowVoltageDisconnectOutput1State 15 "Not available or not installed" 14 "Output fault" 4 "Connect pending alarm active" 3 "Disconnect pending alarm active" 2 "Disconnect alarm expired output off or disconnected" 1 "Output on or connected" 0 "Output off or disconnected" ;
VAL_ 2566717950 LowVoltageDisconnectOutput2State 15 "Not available or not installed" 14 "Output fault" 4 "Connect pending alarm active" 3 "Disconnect pending alarm active" 2 "Disconnect alarm expired output off or disconnected" 1 "Output on or connected" 0 "Output off or disconnected" ;
VAL_ 2566717950 LowVoltageDisconnectOutput3State 15 "Not available or not installed" 14 "Output fault" 4 "Connect pending alarm active" 3 "Disconnect pending alarm active" 2 "Disconnect alarm expired output off or disconnected" 1 "Output on or connected" 0 "Output off or disconnected" ;
VAL_ 2566717950 LwVltgDscnnctCrrentOperatingMode 15 "Not available" 9 "Manual Connect via hardwired input" 8 "Manual Disconnect via hardwired input" 5 "Manual Connect via J1939 request" 4 "Manual Disconnect via J1939 request" 0 "Automatic" ;
VAL_ 2566717950 LwVltgDscnnectManualConnectState 3 "Not installed" 2 "Error" 1 "Input on" 0 "Input off" ;
VAL_ 2566717950 LwVltgDscnnctMnalDisconnectState 3 "Not installed" 2 "Error" 1 "Input on" 0 "Input off" ;
VAL_ 2358902526 Joystick3Lamp10Cmd 3 "Not available or not installed" 2 "Blinking" 1 "On" 0 "Off" ;
VAL_ 2358902526 Joystick3Lamp9Cmd 3 "Not available or not installed" 2 "Blinking" 1 "On" 0 "Off" ;
VAL_ 2358902526 Joystick3Lamp8Cmd 3 "Not available or not installed" 2 "Blinking" 1 "On" 0 "Off" ;
VAL_ 2358902526 Joystick3Lamp7Cmd 3 "Not available or not installed" 2 "Blinking" 1 "On" 0 "Off" ;
VAL_ 2358902526 Joystick3Lamp6Cmd 3 "Not available or not installed" 2 "Blinking" 1 "On" 0 "Off" ;
VAL_ 2358902526 Joystick3Lamp5Cmd 3 "Not available or not installed" 2 "Blinking" 1 "On" 0 "Off" ;
VAL_ 2358902526 Joystick3Lamp4Cmd 3 "Not available or not installed" 2 "Blinking" 1 "On" 0 "Off" ;
VAL_ 2358902526 Joystick3Lamp3Cmd 3 "Not available or not installed" 2 "Blinking" 1 "On" 0 "Off" ;
VAL_ 2358902526 Joystick3Lamp2Cmd 3 "Not available or not installed" 2 "Blinking" 1 "On" 0 "Off" ;
VAL_ 2358902526 Joystick3Lamp1Cmd 3 "Not available or not installed" 2 "Blinking" 1 "On" 0 "Off" ;
VAL_ 2358902526 Joystick2Lamp10Cmd 3 "Not available or not installed" 2 "Blinking" 1 "On" 0 "Off" ;
VAL_ 2358902526 Joystick2Lamp9Cmd 3 "Not available or not installed" 2 "Blinking" 1 "On" 0 "Off" ;
VAL_ 2358902526 Joystick2Lamp8Cmd 3 "Not available or not installed" 2 "Blinking" 1 "On" 0 "Off" ;
VAL_ 2358902526 Joystick2Lamp7Cmd 3 "Not available or not installed" 2 "Blinking" 1 "On" 0 "Off" ;
VAL_ 2358902526 Joystick2Lamp6Cmd 3 "Not available or not installed" 2 "Blinking" 1 "On" 0 "Off" ;
VAL_ 2358902526 Joystick2Lamp5Cmd 3 "Not available or not installed" 2 "Blinking" 1 "On" 0 "Off" ;
VAL_ 2358902526 Joystick2Lamp4Cmd 3 "Not available or not installed" 2 "Blinking" 1 "On" 0 "Off" ;
VAL_ 2358902526 Joystick2Lamp3Cmd 3 "Not available or not installed" 2 "Blinking" 1 "On" 0 "Off" ;
VAL_ 2358902526 Joystick2Lamp2Cmd 3 "Not available or not installed" 2 "Blinking" 1 "On" 0 "Off" ;
VAL_ 2358902526 Joystick2Lamp1Cmd 3 "Not available or not installed" 2 "Blinking" 1 "On" 0 "Off" ;
VAL_ 2358902526 Joystick1Lamp10Cmd 3 "Not available or not installed" 2 "Blinking" 1 "On" 0 "Off" ;
VAL_ 2358902526 Joystick1Lamp9Cmd 3 "Not available or not installed" 2 "Blinking" 1 "On" 0 "Off" ;
VAL_ 2358902526 Joystick1Lamp8Cmd 3 "Not available or not installed" 2 "Blinking" 1 "On" 0 "Off" ;
VAL_ 2358902526 Joystick1Lamp7Cmd 3 "Not available or not installed" 2 "Blinking" 1 "On" 0 "Off" ;
VAL_ 2358902526 Joystick1Lamp6Cmd 3 "Not available or not installed" 2 "Blinking" 1 "On" 0 "Off" ;
VAL_ 2358902526 Joystick1Lamp5Cmd 3 "Not available or not installed" 2 "Blinking" 1 "On" 0 "Off" ;
VAL_ 2358902526 Joystick1Lamp4Cmd 3 "Not available or not installed" 2 "Blinking" 1 "On" 0 "Off" ;
VAL_ 2358902526 Joystick1Lamp3Cmd 3 "Not available or not installed" 2 "Blinking" 1 "On" 0 "Off" ;
VAL_ 2358902526 Joystick1Lamp2Cmd 3 "Not available or not installed" 2 "Blinking" 1 "On" 0 "Off" ;
VAL_ 2358902526 Joystick1Lamp1Cmd 3 "Not available or not installed" 2 "Blinking" 1 "On" 0 "Off" ;

SG_MUL_VAL_ 2358509310 VehicleSystemQualifierFlag NMControlModeIndicator 0-0, 4-4, 8-8;
SG_MUL_VAL_ 2358509310 VehicleSystemInstanceQualifierFl NMControlModeIndicator 0-0, 4-4, 8-8;
SG_MUL_VAL_ 2358509310 NameChecksum NMControlModeIndicator 0-0;
SG_MUL_VAL_ 2358509310 ManufacturerCodeQualifierFlag NMControlModeIndicator 0-0, 4-4, 8-8;
SG_MUL_VAL_ 2358509310 IndustryGroupQualifierFlag NMControlModeIndicator 0-0, 4-4, 8-8;
SG_MUL_VAL_ 2358509310 FunctionQualifierFlag NMControlModeIndicator 0-0, 4-4, 8-8;
SG_MUL_VAL_ 2358509310 FunctionInstanceQualifierFlag NMControlModeIndicator 0-0, 4-4, 8-8;
SG_MUL_VAL_ 2358509310 ErrorCode NMControlModeIndicator 4-4;
SG_MUL_VAL_ 2358509310 ECUInstanceQualifierFlag NMControlModeIndicator 0-0, 4-4, 8-8;
SG_MUL_VAL_ 2358509310 CommandVehicleSystemInstance NMControlModeIndicator 0-3, 8-8;
SG_MUL_VAL_ 2358509310 CommandVehicleSystem NMControlModeIndicator 0-3, 8-8;
SG_MUL_VAL_ 2358509310 CommandManufacturerCode NMControlModeIndicator 0-3, 8-8;
SG_MUL_VAL_ 2358509310 CommandIndustryGroup NMControlModeIndicator 0-3, 8-8;
SG_MUL_VAL_ 2358509310 CommandFunctionInstance NMControlModeIndicator 0-3, 8-8;
SG_MUL_VAL_ 2358509310 CommandFunction NMControlModeIndicator 0-3, 8-8;
SG_MUL_VAL_ 2358509310 CommandECUInstance NMControlModeIndicator 0-3, 8-8;
SG_MUL_VAL_ 2358509310 CommandArbitraryAddressCapable NMControlModeIndicator 0-3, 8-8;
SG_MUL_VAL_ 2358509310 ArbitraryAddressCapableQualifier ManufacturerCodeQualifierFlag 0-0, 4-4, 8-8;
